VERSION ""

NS_ :

BS_:

BU_: R_BPCU_MCU JiaShiCang L_BPCU_MCU EMPC_ECU

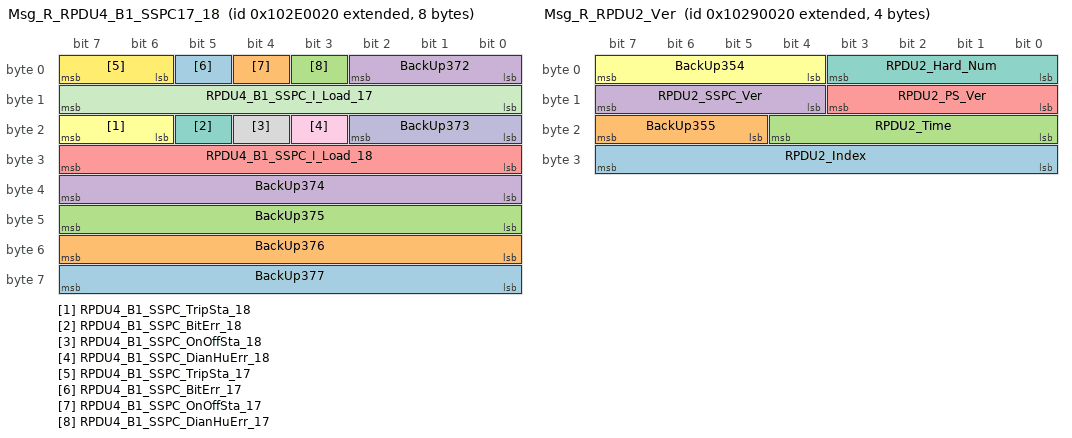
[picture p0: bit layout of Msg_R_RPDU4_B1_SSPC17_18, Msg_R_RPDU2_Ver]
BO_ 2418933792 Msg_R_RPDU4_B1_SSPC17_18: 8 R_BPCU_MCU
 SG_ BackUp377 : 56|8@1+ (1,0) [0|0] ""  JiaShiCang
 SG_ BackUp376 : 48|8@1+ (1,0) [0|0] ""  JiaShiCang
 SG_ BackUp375 : 40|8@1+ (1,0) [0|0] ""  JiaShiCang
 SG_ BackUp374 : 32|8@1+ (1,0) [0|0] ""  JiaShiCang
 SG_ RPDU4_B1_SSPC_I_Load_18 : 24|8@1+ (0.1,0) [0|25.5] "A"  JiaShiCang
 SG_ RPDU4_B1_SSPC_TripSta_18 : 22|2@1+ (1,0) [0|3] ""  JiaShiCang
 SG_ RPDU4_B1_SSPC_BitErr_18 : 21|1@1+ (1,0) [0|1] ""  JiaShiCang
 SG_ RPDU4_B1_SSPC_OnOffSta_18 : 20|1@1+ (1,0) [0|1] ""  JiaShiCang
 SG_ RPDU4_B1_SSPC_DianHuErr_18 : 19|1@1+ (1,0) [0|1] ""  JiaShiCang
 SG_ BackUp373 : 16|3@1+ (1,0) [0|0] ""  JiaShiCang
 SG_ RPDU4_B1_SSPC_I_Load_17 : 8|8@1+ (0.1,0) [0|25.5] "A"  JiaShiCang
 SG_ RPDU4_B1_SSPC_TripSta_17 : 6|2@1+ (1,0) [0|3] ""  JiaShiCang
 SG_ RPDU4_B1_SSPC_BitErr_17 : 5|1@1+ (1,0) [0|1] ""  JiaShiCang
 SG_ RPDU4_B1_SSPC_OnOffSta_17 : 4|1@1+ (1,0) [0|1] ""  JiaShiCang
 SG_ RPDU4_B1_SSPC_DianHuErr_17 : 3|1@1+ (1,0) [0|1] ""  JiaShiCang
 SG_ BackUp372 : 0|3@1+ (1,0) [0|0] ""  JiaShiCang

BO_ 2418868256 Msg_R_RPDU4_B1_SSPC13_16: 8 R_BPCU_MCU
 SG_ RPDU4_B1_SSPC_I_Load_16 : 56|8@1+ (0.1,0) [0|25.5] "A"  JiaShiCang
 SG_ RPDU4_B1_SSPC_TripSta_16 : 54|2@1+ (1,0) [0|3] ""  JiaShiCang
 SG_ RPDU4_B1_SSPC_BitErr_16 : 53|1@1+ (1,0) [0|1] ""  JiaShiCang
 SG_ RPDU4_B1_SSPC_OnOffSta_16 : 52|1@1+ (1,0) [0|1] ""  JiaShiCang
 SG_ RPDU4_B1_SSPC_DianHuErr_16 : 51|1@1+ (1,0) [0|1] ""  JiaShiCang
 SG_ BackUp371 : 48|3@1+ (1,0) [0|0] ""  JiaShiCang
 SG_ RPDU4_B1_SSPC_I_Load_15 : 40|8@1+ (0.1,0) [0|25.5] "A"  JiaShiCang
 SG_ RPDU4_B1_SSPC_TripSta_15 : 38|2@1+ (1,0) [0|3] ""  JiaShiCang
 SG_ RPDU4_B1_SSPC_BitErr_15 : 37|1@1+ (1,0) [0|1] ""  JiaShiCang
 SG_ RPDU4_B1_SSPC_OnOffSta_15 : 36|1@1+ (1,0) [0|1] ""  JiaShiCang
 SG_ RPDU4_B1_SSPC_DianHuErr_15 : 35|1@1+ (1,0) [0|1] ""  JiaShiCang
 SG_ BackUp370 : 32|3@1+ (1,0) [0|0] ""  JiaShiCang
 SG_ RPDU4_B1_SSPC_I_Load_14 : 24|8@1+ (0.1,0) [0|25.5] "A"  JiaShiCang
 SG_ RPDU4_B1_SSPC_TripSta_14 : 22|2@1+ (1,0) [0|3] ""  JiaShiCang
 SG_ RPDU4_B1_SSPC_BitErr_14 : 21|1@1+ (1,0) [0|1] ""  JiaShiCang
 SG_ RPDU4_B1_SSPC_OnOffSta_14 : 20|1@1+ (1,0) [0|1] ""  JiaShiCang
 SG_ RPDU4_B1_SSPC_DianHuErr_14 : 19|1@1+ (1,0) [0|1] ""  JiaShiCang
 SG_ BackUp369 : 16|3@1+ (1,0) [0|0] ""  JiaShiCang
 SG_ RPDU4_B1_SSPC_I_Load_13 : 8|8@1+ (0.1,0) [0|25.5] "A"  JiaShiCang
 SG_ RPDU4_B1_SSPC_TripSta_13 : 6|2@1+ (1,0) [0|3] ""  JiaShiCang
 SG_ RPDU4_B1_SSPC_BitErr_13 : 5|1@1+ (1,0) [0|1] ""  JiaShiCang
 SG_ RPDU4_B1_SSPC_OnOffSta_13 : 4|1@1+ (1,0) [0|1] ""  JiaShiCang
 SG_ RPDU4_B1_SSPC_DianHuErr_13 : 3|1@1+ (1,0) [0|1] ""  JiaShiCang
 SG_ BackUp368 : 0|3@1+ (1,0) [0|0] ""  JiaShiCang

BO_ 2418802720 Msg_R_RPDU4_B1_SSPC09_12: 8 R_BPCU_MCU
 SG_ RPDU4_B1_SSPC_I_Load_12 : 56|8@1+ (0.1,0) [0|25.5] "A"  JiaShiCang
 SG_ RPDU4_B1_SSPC_TripSta_12 : 54|2@1+ (1,0) [0|3] ""  JiaShiCang
 SG_ RPDU4_B1_SSPC_BitErr_12 : 53|1@1+ (1,0) [0|1] ""  JiaShiCang
 SG_ RPDU4_B1_SSPC_OnOffSta_12 : 52|1@1+ (1,0) [0|1] ""  JiaShiCang
 SG_ RPDU4_B1_SSPC_DianHuErr_12 : 51|1@1+ (1,0) [0|1] ""  JiaShiCang
 SG_ BackUp367 : 48|3@1+ (1,0) [0|0] ""  JiaShiCang
 SG_ RPDU4_B1_SSPC_I_Load_11 : 40|8@1+ (0.1,0) [0|25.5] "A"  JiaShiCang
 SG_ RPDU4_B1_SSPC_TripSta_11 : 38|2@1+ (1,0) [0|3] ""  JiaShiCang
 SG_ RPDU4_B1_SSPC_BitErr_11 : 37|1@1+ (1,0) [0|1] ""  JiaShiCang
 SG_ RPDU4_B1_SSPC_OnOffSta_11 : 36|1@1+ (1,0) [0|1] ""  JiaShiCang
 SG_ RPDU4_B1_SSPC_DianHuErr_11 : 35|1@1+ (1,0) [0|1] ""  JiaShiCang
 SG_ BackUp366 : 32|3@1+ (1,0) [0|0] ""  JiaShiCang
 SG_ RPDU4_B1_SSPC_I_Load_10 : 24|8@1+ (0.1,0) [0|25.5] "A"  JiaShiCang
 SG_ RPDU4_B1_SSPC_TripSta_10 : 22|2@1+ (1,0) [0|3] ""  JiaShiCang
 SG_ RPDU4_B1_SSPC_BitErr_10 : 21|1@1+ (1,0) [0|1] ""  JiaShiCang
 SG_ RPDU4_B1_SSPC_OnOffSta_10 : 20|1@1+ (1,0) [0|1] ""  JiaShiCang
 SG_ RPDU4_B1_SSPC_DianHuErr_10 : 19|1@1+ (1,0) [0|1] ""  JiaShiCang
 SG_ BackUp365 : 16|3@1+ (1,0) [0|0] ""  JiaShiCang
 SG_ RPDU4_B1_SSPC_I_Load_09 : 8|8@1+ (0.1,0) [0|25.5] "A"  JiaShiCang
 SG_ RPDU4_B1_SSPC_TripSta_09 : 6|2@1+ (1,0) [0|3] ""  JiaShiCang
 SG_ RPDU4_B1_SSPC_BitErr_09 : 5|1@1+ (1,0) [0|1] ""  JiaShiCang
 SG_ RPDU4_B1_SSPC_OnOffSta_09 : 4|1@1+ (1,0) [0|1] ""  JiaShiCang
 SG_ RPDU4_B1_SSPC_DianHuErr_09 : 3|1@1+ (1,0) [0|1] ""  JiaShiCang
 SG_ BackUp364 : 0|3@1+ (1,0) [0|0] ""  JiaShiCang

BO_ 2418737184 Msg_R_RPDU4_B1_SSPC05_08: 8 R_BPCU_MCU
 SG_ RPDU4_B1_SSPC_I_Load_08 : 56|8@1+ (0.1,0) [0|25.5] "A"  JiaShiCang
 SG_ RPDU4_B1_SSPC_TripSta_08 : 54|2@1+ (1,0) [0|3] ""  JiaShiCang
 SG_ RPDU4_B1_SSPC_BitErr_08 : 53|1@1+ (1,0) [0|1] ""  JiaShiCang
 SG_ RPDU4_B1_SSPC_OnOffSta_08 : 52|1@1+ (1,0) [0|1] ""  JiaShiCang
 SG_ RPDU4_B1_SSPC_DianHuErr_08 : 51|1@1+ (1,0) [0|1] ""  JiaShiCang
 SG_ BackUp363 : 48|3@1+ (1,0) [0|0] ""  JiaShiCang
 SG_ RPDU4_B1_SSPC_I_Load_07 : 40|8@1+ (0.1,0) [0|25.5] "A"  JiaShiCang
 SG_ RPDU4_B1_SSPC_TripSta_07 : 38|2@1+ (1,0) [0|3] ""  JiaShiCang
 SG_ RPDU4_B1_SSPC_BitErr_07 : 37|1@1+ (1,0) [0|1] ""  JiaShiCang
 SG_ RPDU4_B1_SSPC_OnOffSta_07 : 36|1@1+ (1,0) [0|1] ""  JiaShiCang
 SG_ RPDU4_B1_SSPC_DianHuErr_07 : 35|1@1+ (1,0) [0|1] ""  JiaShiCang
 SG_ BackUp362 : 32|3@1+ (1,0) [0|0] ""  JiaShiCang
 SG_ RPDU4_B1_SSPC_I_Load_06 : 24|8@1+ (0.1,0) [0|25.5] "A"  JiaShiCang
 SG_ RPDU4_B1_SSPC_TripSta_06 : 22|2@1+ (1,0) [0|3] ""  JiaShiCang
 SG_ RPDU4_B1_SSPC_BitErr_06 : 21|1@1+ (1,0) [0|1] ""  JiaShiCang
 SG_ RPDU4_B1_SSPC_OnOffSta_06 : 20|1@1+ (1,0) [0|1] ""  JiaShiCang
 SG_ RPDU4_B1_SSPC_DianHuErr_06 : 19|1@1+ (1,0) [0|1] ""  JiaShiCang
 SG_ BackUp361 : 16|3@1+ (1,0) [0|0] ""  JiaShiCang
 SG_ RPDU4_B1_SSPC_I_Load_05 : 8|8@1+ (0.1,0) [0|25.5] "A"  JiaShiCang
 SG_ RPDU4_B1_SSPC_TripSta_05 : 6|2@1+ (1,0) [0|3] ""  JiaShiCang
 SG_ RPDU4_B1_SSPC_BitErr_05 : 5|1@1+ (1,0) [0|1] ""  JiaShiCang
 SG_ RPDU4_B1_SSPC_OnOffSta_05 : 4|1@1+ (1,0) [0|1] ""  JiaShiCang
 SG_ RPDU4_B1_SSPC_DianHuErr_05 : 3|1@1+ (1,0) [0|1] ""  JiaShiCang
 SG_ BackUp360 : 0|3@1+ (1,0) [0|0] ""  JiaShiCang

BO_ 2418671648 Msg_R_RPDU4_B1_SSPC01_04: 8 R_BPCU_MCU
 SG_ RPDU4_B1_SSPC_I_Load_04 : 56|8@1+ (0.1,0) [0|25.5] "A"  JiaShiCang
 SG_ RPDU4_B1_SSPC_TripSta_04 : 54|2@1+ (1,0) [0|3] ""  JiaShiCang
 SG_ RPDU4_B1_SSPC_BitErr_04 : 53|1@1+ (1,0) [0|1] ""  JiaShiCang
 SG_ RPDU4_B1_SSPC_OnOffSta_04 : 52|1@1+ (1,0) [0|1] ""  JiaShiCang
 SG_ RPDU4_B1_SSPC_DianHuErr_04 : 51|1@1+ (1,0) [0|1] ""  JiaShiCang
 SG_ BackUp359 : 48|3@1+ (1,0) [0|0] ""  JiaShiCang
 SG_ RPDU4_B1_SSPC_I_Load_03 : 40|8@1+ (0.1,0) [0|25.5] "A"  JiaShiCang
 SG_ RPDU4_B1_SSPC_TripSta_03 : 38|2@1+ (1,0) [0|3] ""  JiaShiCang
 SG_ RPDU4_B1_SSPC_BitErr_03 : 37|1@1+ (1,0) [0|1] ""  JiaShiCang
 SG_ RPDU4_B1_SSPC_OnOffSta_03 : 36|1@1+ (1,0) [0|1] ""  JiaShiCang
 SG_ RPDU4_B1_SSPC_DianHuErr_03 : 35|1@1+ (1,0) [0|1] ""  JiaShiCang
 SG_ BackUp358 : 32|3@1+ (1,0) [0|0] ""  JiaShiCang
 SG_ RPDU4_B1_SSPC_I_Load_02 : 24|8@1+ (0.1,0) [0|25.5] "A"  JiaShiCang
 SG_ RPDU4_B1_SSPC_TripSta_02 : 22|2@1+ (1,0) [0|3] ""  JiaShiCang
 SG_ RPDU4_B1_SSPC_BitErr_02 : 21|1@1+ (1,0) [0|1] ""  JiaShiCang
 SG_ RPDU4_B1_SSPC_OnOffSta_02 : 20|1@1+ (1,0) [0|1] ""  JiaShiCang
 SG_ RPDU4_B1_SSPC_DianHuErr_02 : 19|1@1+ (1,0) [0|1] ""  JiaShiCang
 SG_ BackUp357 : 16|3@1+ (1,0) [0|0] ""  JiaShiCang
 SG_ RPDU4_B1_SSPC_I_Load_01 : 8|8@1+ (0.1,0) [0|25.5] "A"  JiaShiCang
 SG_ RPDU4_B1_SSPC_TripSta_01 : 6|2@1+ (1,0) [0|3] ""  JiaShiCang
 SG_ RPDU4_B1_SSPC_BitErr_01 : 5|1@1+ (1,0) [0|1] ""  JiaShiCang
 SG_ RPDU4_B1_SSPC_OnOffSta_01 : 4|1@1+ (1,0) [0|1] ""  JiaShiCang
 SG_ RPDU4_B1_SSPC_DianHuErr_01 : 3|1@1+ (1,0) [0|1] ""  JiaShiCang
 SG_ BackUp356 : 0|3@1+ (1,0) [0|0] ""  JiaShiCang

BO_ 2418606112 Msg_R_RPDU2_Ver: 4 R_BPCU_MCU
 SG_ RPDU2_Index : 24|8@1+ (1,0) [0|255] ""  JiaShiCang
 SG_ BackUp355 : 21|3@1+ (1,0) [0|0] ""  JiaShiCang
 SG_ RPDU2_Time : 16|5@1+ (1,0) [0|31] ""  JiaShiCang
 SG_ RPDU2_SSPC_Ver : 12|4@1+ (1,0) [0|15] ""  JiaShiCang
 SG_ RPDU2_PS_Ver : 8|4@1+ (1,0) [0|15] ""  JiaShiCang
 SG_ BackUp354 : 4|4@1+ (1,0) [0|0] ""  JiaShiCang
 SG_ RPDU2_Hard_Num : 0|4@1+ (1,0) [0|15] ""  JiaShiCang

BO_ 2418540576 Msg_R_RPDU2_B6_SSPC05_07: 8 R_BPCU_MCU
 SG_ BackUp353 : 56|8@1+ (1,0) [0|0] ""  JiaShiCang
 SG_ BackUp352 : 48|8@1+ (1,0) [0|0] ""  JiaShiCang
 SG_ RPDU2_B6_SSPC_I_Load_07 : 40|8@1+ (0.1,0) [0|25.5] "A"  JiaShiCang
 SG_ RPDU2_B6_SSPC_TripSta_07 : 38|2@1+ (1,0) [0|3] ""  JiaShiCang
 SG_ RPDU2_B6_SSPC_BitErr_07 : 37|1@1+ (1,0) [0|1] ""  JiaShiCang
 SG_ RPDU2_B6_SSPC_OnOffSta_07 : 36|1@1+ (1,0) [0|1] ""  JiaShiCang
 SG_ RPDU2_B6_SSPC_DianHuErr_07 : 35|1@1+ (1,0) [0|1] ""  JiaShiCang
 SG_ BackUp351 : 32|3@1+ (1,0) [0|0] ""  JiaShiCang
 SG_ RPDU2_B6_SSPC_I_Load_06 : 24|8@1+ (0.1,0) [0|25.5] "A"  JiaShiCang
 SG_ RPDU2_B6_SSPC_TripSta_06 : 22|2@1+ (1,0) [0|3] ""  JiaShiCang
 SG_ RPDU2_B6_SSPC_BitErr_06 : 21|1@1+ (1,0) [0|1] ""  JiaShiCang
 SG_ RPDU2_B6_SSPC_OnOffSta_06 : 20|1@1+ (1,0) [0|1] ""  JiaShiCang
 SG_ RPDU2_B6_SSPC_DianHuErr_06 : 19|1@1+ (1,0) [0|1] ""  JiaShiCang
 SG_ BackUp350 : 16|3@1+ (1,0) [0|0] ""  JiaShiCang
 SG_ RPDU2_B6_SSPC_I_Load_05 : 8|8@1+ (0.1,0) [0|25.5] "A"  JiaShiCang
 SG_ RPDU2_B6_SSPC_TripSta_05 : 6|2@1+ (1,0) [0|3] ""  JiaShiCang
 SG_ RPDU2_B6_SSPC_BitErr_05 : 5|1@1+ (1,0) [0|1] ""  JiaShiCang
 SG_ RPDU2_B6_SSPC_OnOffSta_05 : 4|1@1+ (1,0) [0|1] ""  JiaShiCang
 SG_ RPDU2_B6_SSPC_DianHuErr_05 : 3|1@1+ (1,0) [0|1] ""  JiaShiCang
 SG_ BackUp349 : 0|3@1+ (1,0) [0|0] ""  JiaShiCang

BO_ 2418475040 Msg_R_RPDU2_B6_SSPC01_04: 8 R_BPCU_MCU
 SG_ RPDU2_B6_SSPC_I_Load_04 : 56|8@1+ (0.1,0) [0|25.5] "A"  JiaShiCang
 SG_ RPDU2_B6_SSPC_TripSta_04 : 54|2@1+ (1,0) [0|3] ""  JiaShiCang
 SG_ RPDU2_B6_SSPC_BitErr_04 : 53|1@1+ (1,0) [0|1] ""  JiaShiCang
 SG_ RPDU2_B6_SSPC_OnOffSta_04 : 52|1@1+ (1,0) [0|1] ""  JiaShiCang
 SG_ RPDU2_B6_SSPC_DianHuErr_04 : 51|1@1+ (1,0) [0|1] ""  JiaShiCang
 SG_ BackUp348 : 48|3@1+ (1,0) [0|0] ""  JiaShiCang
 SG_ RPDU2_B6_SSPC_I_Load_03 : 40|8@1+ (0.1,0) [0|25.5] "A"  JiaShiCang
 SG_ RPDU2_B6_SSPC_TripSta_03 : 38|2@1+ (1,0) [0|3] ""  JiaShiCang
 SG_ RPDU2_B6_SSPC_BitErr_03 : 37|1@1+ (1,0) [0|1] ""  JiaShiCang
 SG_ RPDU2_B6_SSPC_OnOffSta_03 : 36|1@1+ (1,0) [0|1] ""  JiaShiCang
 SG_ RPDU2_B6_SSPC_DianHuErr_03 : 35|1@1+ (1,0) [0|1] ""  JiaShiCang
 SG_ BackUp347 : 32|3@1+ (1,0) [0|0] ""  JiaShiCang
 SG_ RPDU2_B6_SSPC_I_Load_02 : 24|8@1+ (0.1,0) [0|25.5] "A"  JiaShiCang
 SG_ RPDU2_B6_SSPC_TripSta_02 : 22|2@1+ (1,0) [0|3] ""  JiaShiCang
 SG_ RPDU2_B6_SSPC_BitErr_02 : 21|1@1+ (1,0) [0|1] ""  JiaShiCang
 SG_ RPDU2_B6_SSPC_OnOffSta_02 : 20|1@1+ (1,0) [0|1] ""  JiaShiCang
 SG_ RPDU2_B6_SSPC_DianHuErr_02 : 19|1@1+ (1,0) [0|1] ""  JiaShiCang
 SG_ BackUp346 : 16|3@1+ (1,0) [0|0] ""  JiaShiCang
 SG_ RPDU2_B6_SSPC_I_Load_01 : 8|8@1+ (0.1,0) [0|25.5] "A"  JiaShiCang
 SG_ RPDU2_B6_SSPC_TripSta_01 : 6|2@1+ (1,0) [0|3] ""  JiaShiCang
 SG_ RPDU2_B6_SSPC_BitErr_01 : 5|1@1+ (1,0) [0|1] ""  JiaShiCang
 SG_ RPDU2_B6_SSPC_OnOffSta_01 : 4|1@1+ (1,0) [0|1] ""  JiaShiCang
 SG_ RPDU2_B6_SSPC_DianHuErr_01 : 3|1@1+ (1,0) [0|1] ""  JiaShiCang
 SG_ BackUp345 : 0|3@1+ (1,0) [0|0] ""  JiaShiCang

BO_ 2418409504 Msg_R_RPDU2_B5_SSPC05_07: 8 R_BPCU_MCU
 SG_ BackUp344 : 56|8@1+ (1,0) [0|0] ""  JiaShiCang
 SG_ BackUp343 : 48|8@1+ (1,0) [0|0] ""  JiaShiCang
 SG_ RPDU2_B5_SSPC_I_Load_07 : 40|8@1+ (0.1,0) [0|25.5] "A"  JiaShiCang
 SG_ RPDU2_B5_SSPC_TripSta_07 : 38|2@1+ (1,0) [0|3] ""  JiaShiCang
 SG_ RPDU2_B5_SSPC_BitErr_07 : 37|1@1+ (1,0) [0|1] ""  JiaShiCang
 SG_ RPDU2_B5_SSPC_OnOffSta_07 : 36|1@1+ (1,0) [0|1] ""  JiaShiCang
 SG_ RPDU2_B5_SSPC_DianHuErr_07 : 35|1@1+ (1,0) [0|1] ""  JiaShiCang
 SG_ BackUp342 : 32|3@1+ (1,0) [0|0] ""  JiaShiCang
 SG_ RPDU2_B5_SSPC_I_Load_06 : 24|8@1+ (0.1,0) [0|25.5] "A"  JiaShiCang
 SG_ RPDU2_B5_SSPC_TripSta_06 : 22|2@1+ (1,0) [0|3] ""  JiaShiCang
 SG_ RPDU2_B5_SSPC_BitErr_06 : 21|1@1+ (1,0) [0|1] ""  JiaShiCang
 SG_ RPDU2_B5_SSPC_OnOffSta_06 : 20|1@1+ (1,0) [0|1] ""  JiaShiCang
 SG_ RPDU2_B5_SSPC_DianHuErr_06 : 19|1@1+ (1,0) [0|1] ""  JiaShiCang
 SG_ BackUp341 : 16|3@1+ (1,0) [0|0] ""  JiaShiCang
 SG_ RPDU2_B5_SSPC_I_Load_05 : 8|8@1+ (0.1,0) [0|25.5] "A"  JiaShiCang
 SG_ RPDU2_B5_SSPC_TripSta_05 : 6|2@1+ (1,0) [0|3] ""  JiaShiCang
 SG_ RPDU2_B5_SSPC_BitErr_05 : 5|1@1+ (1,0) [0|1] ""  JiaShiCang
 SG_ RPDU2_B5_SSPC_OnOffSta_05 : 4|1@1+ (1,0) [0|1] ""  JiaShiCang
 SG_ RPDU2_B5_SSPC_DianHuErr_05 : 3|1@1+ (1,0) [0|1] ""  JiaShiCang
 SG_ BackUp340 : 0|3@1+ (1,0) [0|0] ""  JiaShiCang

BO_ 2418343968 Msg_R_RPDU2_B5_SSPC01_04: 8 R_BPCU_MCU
 SG_ RPDU2_B5_SSPC_I_Load_04 : 56|8@1+ (0.1,0) [0|25.5] "A"  JiaShiCang
 SG_ RPDU2_B5_SSPC_TripSta_04 : 54|2@1+ (1,0) [0|3] ""  JiaShiCang
 SG_ RPDU2_B5_SSPC_BitErr_04 : 53|1@1+ (1,0) [0|1] ""  JiaShiCang
 SG_ RPDU2_B5_SSPC_OnOffSta_04 : 52|1@1+ (1,0) [0|1] ""  JiaShiCang
 SG_ RPDU2_B5_SSPC_DianHuErr_04 : 51|1@1+ (1,0) [0|1] ""  JiaShiCang
 SG_ BackUp339 : 48|3@1+ (1,0) [0|0] ""  JiaShiCang
 SG_ RPDU2_B5_SSPC_I_Load_03 : 40|8@1+ (0.1,0) [0|25.5] "A"  JiaShiCang
 SG_ RPDU2_B5_SSPC_TripSta_03 : 38|2@1+ (1,0) [0|3] ""  JiaShiCang
 SG_ RPDU2_B5_SSPC_BitErr_03 : 37|1@1+ (1,0) [0|1] ""  JiaShiCang
 SG_ RPDU2_B5_SSPC_OnOffSta_03 : 36|1@1+ (1,0) [0|1] ""  JiaShiCang
 SG_ RPDU2_B5_SSPC_DianHuErr_03 : 35|1@1+ (1,0) [0|1] ""  JiaShiCang
 SG_ BackUp338 : 32|3@1+ (1,0) [0|0] ""  JiaShiCang
 SG_ RPDU2_B5_SSPC_I_Load_02 : 24|8@1+ (0.1,0) [0|25.5] "A"  JiaShiCang
 SG_ RPDU2_B5_SSPC_TripSta_02 : 22|2@1+ (1,0) [0|3] ""  JiaShiCang
 SG_ RPDU2_B5_SSPC_BitErr_02 : 21|1@1+ (1,0) [0|1] ""  JiaShiCang
 SG_ RPDU2_B5_SSPC_OnOffSta_02 : 20|1@1+ (1,0) [0|1] ""  JiaShiCang
 SG_ RPDU2_B5_SSPC_DianHuErr_02 : 19|1@1+ (1,0) [0|1] ""  JiaShiCang
 SG_ BackUp337 : 16|3@1+ (1,0) [0|0] ""  JiaShiCang
 SG_ RPDU2_B5_SSPC_I_Load_01 : 8|8@1+ (0.1,0) [0|25.5] "A"  JiaShiCang
 SG_ RPDU2_B5_SSPC_TripSta_01 : 6|2@1+ (1,0) [0|3] ""  JiaShiCang
 SG_ RPDU2_B5_SSPC_BitErr_01 : 5|1@1+ (1,0) [0|1] ""  JiaShiCang
 SG_ RPDU2_B5_SSPC_OnOffSta_01 : 4|1@1+ (1,0) [0|1] ""  JiaShiCang
 SG_ RPDU2_B5_SSPC_DianHuErr_01 : 3|1@1+ (1,0) [0|1] ""  JiaShiCang
 SG_ BackUp336 : 0|3@1+ (1,0) [0|0] ""  JiaShiCang

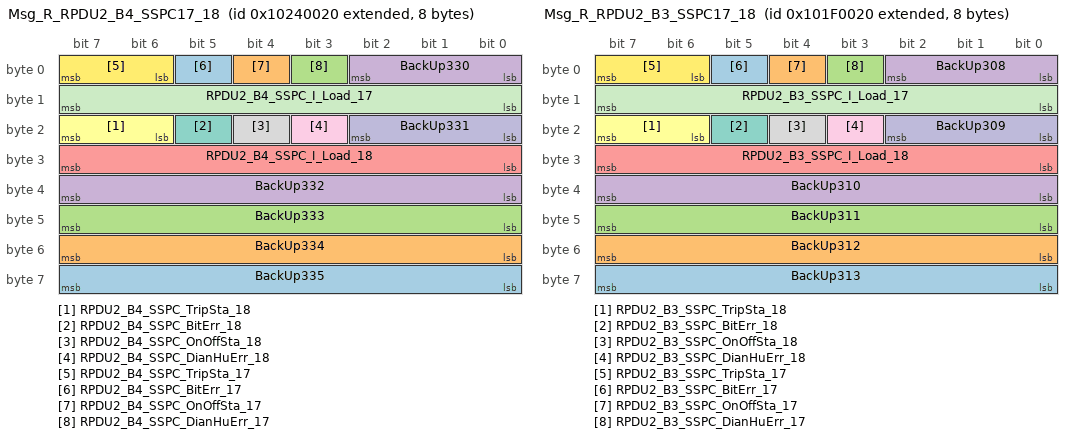
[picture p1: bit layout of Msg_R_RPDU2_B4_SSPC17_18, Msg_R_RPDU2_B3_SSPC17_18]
BO_ 2418278432 Msg_R_RPDU2_B4_SSPC17_18: 8 R_BPCU_MCU
 SG_ BackUp335 : 56|8@1+ (1,0) [0|0] ""  JiaShiCang
 SG_ BackUp334 : 48|8@1+ (1,0) [0|0] ""  JiaShiCang
 SG_ BackUp333 : 40|8@1+ (1,0) [0|0] ""  JiaShiCang
 SG_ BackUp332 : 32|8@1+ (1,0) [0|0] ""  JiaShiCang
 SG_ RPDU2_B4_SSPC_I_Load_18 : 24|8@1+ (0.1,0) [0|25.5] "A"  JiaShiCang
 SG_ RPDU2_B4_SSPC_TripSta_18 : 22|2@1+ (1,0) [0|3] ""  JiaShiCang
 SG_ RPDU2_B4_SSPC_BitErr_18 : 21|1@1+ (1,0) [0|1] ""  JiaShiCang
 SG_ RPDU2_B4_SSPC_OnOffSta_18 : 20|1@1+ (1,0) [0|1] ""  JiaShiCang
 SG_ RPDU2_B4_SSPC_DianHuErr_18 : 19|1@1+ (1,0) [0|1] ""  JiaShiCang
 SG_ BackUp331 : 16|3@1+ (1,0) [0|0] ""  JiaShiCang
 SG_ RPDU2_B4_SSPC_I_Load_17 : 8|8@1+ (0.1,0) [0|25.5] "A"  JiaShiCang
 SG_ RPDU2_B4_SSPC_TripSta_17 : 6|2@1+ (1,0) [0|3] ""  JiaShiCang
 SG_ RPDU2_B4_SSPC_BitErr_17 : 5|1@1+ (1,0) [0|1] ""  JiaShiCang
 SG_ RPDU2_B4_SSPC_OnOffSta_17 : 4|1@1+ (1,0) [0|1] ""  JiaShiCang
 SG_ RPDU2_B4_SSPC_DianHuErr_17 : 3|1@1+ (1,0) [0|1] ""  JiaShiCang
 SG_ BackUp330 : 0|3@1+ (1,0) [0|0] ""  JiaShiCang

BO_ 2418212896 Msg_R_RPDU2_B4_SSPC13_16: 8 R_BPCU_MCU
 SG_ RPDU2_B4_SSPC_I_Load_16 : 56|8@1+ (0.1,0) [0|25.5] "A"  JiaShiCang
 SG_ RPDU2_B4_SSPC_TripSta_16 : 54|2@1+ (1,0) [0|3] ""  JiaShiCang
 SG_ RPDU2_B4_SSPC_BitErr_16 : 53|1@1+ (1,0) [0|1] ""  JiaShiCang
 SG_ RPDU2_B4_SSPC_OnOffSta_16 : 52|1@1+ (1,0) [0|1] ""  JiaShiCang
 SG_ RPDU2_B4_SSPC_DianHuErr_16 : 51|1@1+ (1,0) [0|1] ""  JiaShiCang
 SG_ BackUp329 : 48|3@1+ (1,0) [0|0] ""  JiaShiCang
 SG_ RPDU2_B4_SSPC_I_Load_15 : 40|8@1+ (0.1,0) [0|25.5] "A"  JiaShiCang
 SG_ RPDU2_B4_SSPC_TripSta_15 : 38|2@1+ (1,0) [0|3] ""  JiaShiCang
 SG_ RPDU2_B4_SSPC_BitErr_15 : 37|1@1+ (1,0) [0|1] ""  JiaShiCang
 SG_ RPDU2_B4_SSPC_OnOffSta_15 : 36|1@1+ (1,0) [0|1] ""  JiaShiCang
 SG_ RPDU2_B4_SSPC_DianHuErr_15 : 35|1@1+ (1,0) [0|1] ""  JiaShiCang
 SG_ BackUp328 : 32|3@1+ (1,0) [0|0] ""  JiaShiCang
 SG_ RPDU2_B4_SSPC_I_Load_14 : 24|8@1+ (0.1,0) [0|25.5] "A"  JiaShiCang
 SG_ RPDU2_B4_SSPC_TripSta_14 : 22|2@1+ (1,0) [0|3] ""  JiaShiCang
 SG_ RPDU2_B4_SSPC_BitErr_14 : 21|1@1+ (1,0) [0|1] ""  JiaShiCang
 SG_ RPDU2_B4_SSPC_OnOffSta_14 : 20|1@1+ (1,0) [0|1] ""  JiaShiCang
 SG_ RPDU2_B4_SSPC_DianHuErr_14 : 19|1@1+ (1,0) [0|1] ""  JiaShiCang
 SG_ BackUp327 : 16|3@1+ (1,0) [0|0] ""  JiaShiCang
 SG_ RPDU2_B4_SSPC_I_Load_13 : 8|8@1+ (0.1,0) [0|25.5] "A"  JiaShiCang
 SG_ RPDU2_B4_SSPC_TripSta_13 : 6|2@1+ (1,0) [0|3] ""  JiaShiCang
 SG_ RPDU2_B4_SSPC_BitErr_13 : 5|1@1+ (1,0) [0|1] ""  JiaShiCang
 SG_ RPDU2_B4_SSPC_OnOffSta_13 : 4|1@1+ (1,0) [0|1] ""  JiaShiCang
 SG_ RPDU2_B4_SSPC_DianHuErr_13 : 3|1@1+ (1,0) [0|1] ""  JiaShiCang
 SG_ BackUp326 : 0|3@1+ (1,0) [0|0] ""  JiaShiCang

BO_ 2418147360 Msg_R_RPDU2_B4_SSPC09_12: 8 R_BPCU_MCU
 SG_ RPDU2_B4_SSPC_I_Load_12 : 56|8@1+ (0.1,0) [0|25.5] "A"  JiaShiCang
 SG_ RPDU2_B4_SSPC_TripSta_12 : 54|2@1+ (1,0) [0|3] ""  JiaShiCang
 SG_ RPDU2_B4_SSPC_BitErr_12 : 53|1@1+ (1,0) [0|1] ""  JiaShiCang
 SG_ RPDU2_B4_SSPC_OnOffSta_12 : 52|1@1+ (1,0) [0|1] ""  JiaShiCang
 SG_ RPDU2_B4_SSPC_DianHuErr_12 : 51|1@1+ (1,0) [0|1] ""  JiaShiCang
 SG_ BackUp325 : 48|3@1+ (1,0) [0|0] ""  JiaShiCang
 SG_ RPDU2_B4_SSPC_I_Load_11 : 40|8@1+ (0.1,0) [0|25.5] "A"  JiaShiCang
 SG_ RPDU2_B4_SSPC_TripSta_11 : 38|2@1+ (1,0) [0|3] ""  JiaShiCang
 SG_ RPDU2_B4_SSPC_BitErr_11 : 37|1@1+ (1,0) [0|1] ""  JiaShiCang
 SG_ RPDU2_B4_SSPC_OnOffSta_11 : 36|1@1+ (1,0) [0|1] ""  JiaShiCang
 SG_ RPDU2_B4_SSPC_DianHuErr_11 : 35|1@1+ (1,0) [0|1] ""  JiaShiCang
 SG_ BackUp324 : 32|3@1+ (1,0) [0|0] ""  JiaShiCang
 SG_ RPDU2_B4_SSPC_I_Load_10 : 24|8@1+ (0.1,0) [0|25.5] "A"  JiaShiCang
 SG_ RPDU2_B4_SSPC_TripSta_10 : 22|2@1+ (1,0) [0|3] ""  JiaShiCang
 SG_ RPDU2_B4_SSPC_BitErr_10 : 21|1@1+ (1,0) [0|1] ""  JiaShiCang
 SG_ RPDU2_B4_SSPC_OnOffSta_10 : 20|1@1+ (1,0) [0|1] ""  JiaShiCang
 SG_ RPDU2_B4_SSPC_DianHuErr_10 : 19|1@1+ (1,0) [0|1] ""  JiaShiCang
 SG_ BackUp323 : 16|3@1+ (1,0) [0|0] ""  JiaShiCang
 SG_ RPDU2_B4_SSPC_I_Load_09 : 8|8@1+ (0.1,0) [0|25.5] "A"  JiaShiCang
 SG_ RPDU2_B4_SSPC_TripSta_09 : 6|2@1+ (1,0) [0|3] ""  JiaShiCang
 SG_ RPDU2_B4_SSPC_BitErr_09 : 5|1@1+ (1,0) [0|1] ""  JiaShiCang
 SG_ RPDU2_B4_SSPC_OnOffSta_09 : 4|1@1+ (1,0) [0|1] ""  JiaShiCang
 SG_ RPDU2_B4_SSPC_DianHuErr_09 : 3|1@1+ (1,0) [0|1] ""  JiaShiCang
 SG_ BackUp322 : 0|3@1+ (1,0) [0|0] ""  JiaShiCang

BO_ 2418081824 Msg_R_RPDU2_B4_SSPC05_08: 8 R_BPCU_MCU
 SG_ RPDU2_B4_SSPC_I_Load_08 : 56|8@1+ (0.1,0) [0|25.5] "A"  JiaShiCang
 SG_ RPDU2_B4_SSPC_TripSta_08 : 54|2@1+ (1,0) [0|3] ""  JiaShiCang
 SG_ RPDU2_B4_SSPC_BitErr_08 : 53|1@1+ (1,0) [0|1] ""  JiaShiCang
 SG_ RPDU2_B4_SSPC_OnOffSta_08 : 52|1@1+ (1,0) [0|1] ""  JiaShiCang
 SG_ RPDU2_B4_SSPC_DianHuErr_08 : 51|1@1+ (1,0) [0|1] ""  JiaShiCang
 SG_ BackUp321 : 48|3@1+ (1,0) [0|0] ""  JiaShiCang
 SG_ RPDU2_B4_SSPC_I_Load_07 : 40|8@1+ (0.1,0) [0|25.5] "A"  JiaShiCang
 SG_ RPDU2_B4_SSPC_TripSta_07 : 38|2@1+ (1,0) [0|3] ""  JiaShiCang
 SG_ RPDU2_B4_SSPC_BitErr_07 : 37|1@1+ (1,0) [0|1] ""  JiaShiCang
 SG_ RPDU2_B4_SSPC_OnOffSta_07 : 36|1@1+ (1,0) [0|1] ""  JiaShiCang
 SG_ RPDU2_B4_SSPC_DianHuErr_07 : 35|1@1+ (1,0) [0|1] ""  JiaShiCang
 SG_ BackUp320 : 32|3@1+ (1,0) [0|0] ""  JiaShiCang
 SG_ RPDU2_B4_SSPC_I_Load_06 : 24|8@1+ (0.1,0) [0|25.5] "A"  JiaShiCang
 SG_ RPDU2_B4_SSPC_TripSta_06 : 22|2@1+ (1,0) [0|3] ""  JiaShiCang
 SG_ RPDU2_B4_SSPC_BitErr_06 : 21|1@1+ (1,0) [0|1] ""  JiaShiCang
 SG_ RPDU2_B4_SSPC_OnOffSta_06 : 20|1@1+ (1,0) [0|1] ""  JiaShiCang
 SG_ RPDU2_B4_SSPC_DianHuErr_06 : 19|1@1+ (1,0) [0|1] ""  JiaShiCang
 SG_ BackUp319 : 16|3@1+ (1,0) [0|0] ""  JiaShiCang
 SG_ RPDU2_B4_SSPC_I_Load_05 : 8|8@1+ (0.1,0) [0|25.5] "A"  JiaShiCang
 SG_ RPDU2_B4_SSPC_TripSta_05 : 6|2@1+ (1,0) [0|3] ""  JiaShiCang
 SG_ RPDU2_B4_SSPC_BitErr_05 : 5|1@1+ (1,0) [0|1] ""  JiaShiCang
 SG_ RPDU2_B4_SSPC_OnOffSta_05 : 4|1@1+ (1,0) [0|1] ""  JiaShiCang
 SG_ RPDU2_B4_SSPC_DianHuErr_05 : 3|1@1+ (1,0) [0|1] ""  JiaShiCang
 SG_ BackUp318 : 0|3@1+ (1,0) [0|0] ""  JiaShiCang

BO_ 2418016288 Msg_R_RPDU2_B4_SSPC01_04: 8 R_BPCU_MCU
 SG_ RPDU2_B4_SSPC_I_Load_04 : 56|8@1+ (0.1,0) [0|25.5] "A"  JiaShiCang
 SG_ RPDU2_B4_SSPC_TripSta_04 : 54|2@1+ (1,0) [0|3] ""  JiaShiCang
 SG_ RPDU2_B4_SSPC_BitErr_04 : 53|1@1+ (1,0) [0|1] ""  JiaShiCang
 SG_ RPDU2_B4_SSPC_OnOffSta_04 : 52|1@1+ (1,0) [0|1] ""  JiaShiCang
 SG_ RPDU2_B4_SSPC_DianHuErr_04 : 51|1@1+ (1,0) [0|1] ""  JiaShiCang
 SG_ BackUp317 : 48|3@1+ (1,0) [0|0] ""  JiaShiCang
 SG_ RPDU2_B4_SSPC_I_Load_03 : 40|8@1+ (0.1,0) [0|25.5] "A"  JiaShiCang
 SG_ RPDU2_B4_SSPC_TripSta_03 : 38|2@1+ (1,0) [0|3] ""  JiaShiCang
 SG_ RPDU2_B4_SSPC_BitErr_03 : 37|1@1+ (1,0) [0|1] ""  JiaShiCang
 SG_ RPDU2_B4_SSPC_OnOffSta_03 : 36|1@1+ (1,0) [0|1] ""  JiaShiCang
 SG_ RPDU2_B4_SSPC_DianHuErr_03 : 35|1@1+ (1,0) [0|1] ""  JiaShiCang
 SG_ BackUp316 : 32|3@1+ (1,0) [0|0] ""  JiaShiCang
 SG_ RPDU2_B4_SSPC_I_Load_02 : 24|8@1+ (0.1,0) [0|25.5] "A"  JiaShiCang
 SG_ RPDU2_B4_SSPC_TripSta_02 : 22|2@1+ (1,0) [0|3] ""  JiaShiCang
 SG_ RPDU2_B4_SSPC_BitErr_02 : 21|1@1+ (1,0) [0|1] ""  JiaShiCang
 SG_ RPDU2_B4_SSPC_OnOffSta_02 : 20|1@1+ (1,0) [0|1] ""  JiaShiCang
 SG_ RPDU2_B4_SSPC_DianHuErr_02 : 19|1@1+ (1,0) [0|1] ""  JiaShiCang
 SG_ BackUp315 : 16|3@1+ (1,0) [0|0] ""  JiaShiCang
 SG_ RPDU2_B4_SSPC_I_Load_01 : 8|8@1+ (0.1,0) [0|25.5] "A"  JiaShiCang
 SG_ RPDU2_B4_SSPC_TripSta_01 : 6|2@1+ (1,0) [0|3] ""  JiaShiCang
 SG_ RPDU2_B4_SSPC_BitErr_01 : 5|1@1+ (1,0) [0|1] ""  JiaShiCang
 SG_ RPDU2_B4_SSPC_OnOffSta_01 : 4|1@1+ (1,0) [0|1] ""  JiaShiCang
 SG_ RPDU2_B4_SSPC_DianHuErr_01 : 3|1@1+ (1,0) [0|1] ""  JiaShiCang
 SG_ BackUp314 : 0|3@1+ (1,0) [0|0] ""  JiaShiCang

BO_ 2417950752 Msg_R_RPDU2_B3_SSPC17_18: 8 R_BPCU_MCU
 SG_ BackUp313 : 56|8@1+ (1,0) [0|0] ""  JiaShiCang
 SG_ BackUp312 : 48|8@1+ (1,0) [0|0] ""  JiaShiCang
 SG_ BackUp311 : 40|8@1+ (1,0) [0|0] ""  JiaShiCang
 SG_ BackUp310 : 32|8@1+ (1,0) [0|0] ""  JiaShiCang
 SG_ RPDU2_B3_SSPC_I_Load_18 : 24|8@1+ (0.1,0) [0|25.5] "A"  JiaShiCang
 SG_ RPDU2_B3_SSPC_TripSta_18 : 22|2@1+ (1,0) [0|3] ""  JiaShiCang
 SG_ RPDU2_B3_SSPC_BitErr_18 : 21|1@1+ (1,0) [0|1] ""  JiaShiCang
 SG_ RPDU2_B3_SSPC_OnOffSta_18 : 20|1@1+ (1,0) [0|1] ""  JiaShiCang
 SG_ RPDU2_B3_SSPC_DianHuErr_18 : 19|1@1+ (1,0) [0|1] ""  JiaShiCang
 SG_ BackUp309 : 16|3@1+ (1,0) [0|0] ""  JiaShiCang
 SG_ RPDU2_B3_SSPC_I_Load_17 : 8|8@1+ (0.1,0) [0|25.5] "A"  JiaShiCang
 SG_ RPDU2_B3_SSPC_TripSta_17 : 6|2@1+ (1,0) [0|3] ""  JiaShiCang
 SG_ RPDU2_B3_SSPC_BitErr_17 : 5|1@1+ (1,0) [0|1] ""  JiaShiCang
 SG_ RPDU2_B3_SSPC_OnOffSta_17 : 4|1@1+ (1,0) [0|1] ""  JiaShiCang
 SG_ RPDU2_B3_SSPC_DianHuErr_17 : 3|1@1+ (1,0) [0|1] ""  JiaShiCang
 SG_ BackUp308 : 0|3@1+ (1,0) [0|0] ""  JiaShiCang

BO_ 2417885216 Msg_R_RPDU2_B3_SSPC13_16: 8 R_BPCU_MCU
 SG_ RPDU2_B3_SSPC_I_Load_16 : 56|8@1+ (0.1,0) [0|25.5] "A"  JiaShiCang
 SG_ RPDU2_B3_SSPC_TripSta_16 : 54|2@1+ (1,0) [0|3] ""  JiaShiCang
 SG_ RPDU2_B3_SSPC_BitErr_16 : 53|1@1+ (1,0) [0|1] ""  JiaShiCang
 SG_ RPDU2_B3_SSPC_OnOffSta_16 : 52|1@1+ (1,0) [0|1] ""  JiaShiCang
 SG_ RPDU2_B3_SSPC_DianHuErr_16 : 51|1@1+ (1,0) [0|1] ""  JiaShiCang
 SG_ BackUp307 : 48|3@1+ (1,0) [0|0] ""  JiaShiCang
 SG_ RPDU2_B3_SSPC_I_Load_15 : 40|8@1+ (0.1,0) [0|25.5] "A"  JiaShiCang
 SG_ RPDU2_B3_SSPC_TripSta_15 : 38|2@1+ (1,0) [0|3] ""  JiaShiCang
 SG_ RPDU2_B3_SSPC_BitErr_15 : 37|1@1+ (1,0) [0|1] ""  JiaShiCang
 SG_ RPDU2_B3_SSPC_OnOffSta_15 : 36|1@1+ (1,0) [0|1] ""  JiaShiCang
 SG_ RPDU2_B3_SSPC_DianHuErr_15 : 35|1@1+ (1,0) [0|1] ""  JiaShiCang
 SG_ BackUp306 : 32|3@1+ (1,0) [0|0] ""  JiaShiCang
 SG_ RPDU2_B3_SSPC_I_Load_14 : 24|8@1+ (0.1,0) [0|25.5] "A"  JiaShiCang
 SG_ RPDU2_B3_SSPC_TripSta_14 : 22|2@1+ (1,0) [0|3] ""  JiaShiCang
 SG_ RPDU2_B3_SSPC_BitErr_14 : 21|1@1+ (1,0) [0|1] ""  JiaShiCang
 SG_ RPDU2_B3_SSPC_OnOffSta_14 : 20|1@1+ (1,0) [0|1] ""  JiaShiCang
 SG_ RPDU2_B3_SSPC_DianHuErr_14 : 19|1@1+ (1,0) [0|1] ""  JiaShiCang
 SG_ BackUp305 : 16|3@1+ (1,0) [0|0] ""  JiaShiCang
 SG_ RPDU2_B3_SSPC_I_Load_13 : 8|8@1+ (0.1,0) [0|25.5] "A"  JiaShiCang
 SG_ RPDU2_B3_SSPC_TripSta_13 : 6|2@1+ (1,0) [0|3] ""  JiaShiCang
 SG_ RPDU2_B3_SSPC_BitErr_13 : 5|1@1+ (1,0) [0|1] ""  JiaShiCang
 SG_ RPDU2_B3_SSPC_OnOffSta_13 : 4|1@1+ (1,0) [0|1] ""  JiaShiCang
 SG_ RPDU2_B3_SSPC_DianHuErr_13 : 3|1@1+ (1,0) [0|1] ""  JiaShiCang
 SG_ BackUp304 : 0|3@1+ (1,0) [0|0] ""  JiaShiCang

BO_ 2417819680 Msg_R_RPDU2_B3_SSPC09_12: 8 R_BPCU_MCU
 SG_ RPDU2_B3_SSPC_I_Load_12 : 56|8@1+ (0.1,0) [0|25.5] "A"  JiaShiCang
 SG_ RPDU2_B3_SSPC_TripSta_12 : 54|2@1+ (1,0) [0|3] ""  JiaShiCang
 SG_ RPDU2_B3_SSPC_BitErr_12 : 53|1@1+ (1,0) [0|1] ""  JiaShiCang
 SG_ RPDU2_B3_SSPC_OnOffSta_12 : 52|1@1+ (1,0) [0|1] ""  JiaShiCang
 SG_ RPDU2_B3_SSPC_DianHuErr_12 : 51|1@1+ (1,0) [0|1] ""  JiaShiCang
 SG_ BackUp303 : 48|3@1+ (1,0) [0|0] ""  JiaShiCang
 SG_ RPDU2_B3_SSPC_I_Load_11 : 40|8@1+ (0.1,0) [0|25.5] "A"  JiaShiCang
 SG_ RPDU2_B3_SSPC_TripSta_11 : 38|2@1+ (1,0) [0|3] ""  JiaShiCang
 SG_ RPDU2_B3_SSPC_BitErr_11 : 37|1@1+ (1,0) [0|1] ""  JiaShiCang
 SG_ RPDU2_B3_SSPC_OnOffSta_11 : 36|1@1+ (1,0) [0|1] ""  JiaShiCang
 SG_ RPDU2_B3_SSPC_DianHuErr_11 : 35|1@1+ (1,0) [0|1] ""  JiaShiCang
 SG_ BackUp302 : 32|3@1+ (1,0) [0|0] ""  JiaShiCang
 SG_ RPDU2_B3_SSPC_I_Load_10 : 24|8@1+ (0.1,0) [0|25.5] "A"  JiaShiCang
 SG_ RPDU2_B3_SSPC_TripSta_10 : 22|2@1+ (1,0) [0|3] ""  JiaShiCang
 SG_ RPDU2_B3_SSPC_BitErr_10 : 21|1@1+ (1,0) [0|1] ""  JiaShiCang
 SG_ RPDU2_B3_SSPC_OnOffSta_10 : 20|1@1+ (1,0) [0|1] ""  JiaShiCang
 SG_ RPDU2_B3_SSPC_DianHuErr_10 : 19|1@1+ (1,0) [0|1] ""  JiaShiCang
 SG_ BackUp301 : 16|3@1+ (1,0) [0|0] ""  JiaShiCang
 SG_ RPDU2_B3_SSPC_I_Load_09 : 8|8@1+ (0.1,0) [0|25.5] "A"  JiaShiCang
 SG_ RPDU2_B3_SSPC_TripSta_09 : 6|2@1+ (1,0) [0|3] ""  JiaShiCang
 SG_ RPDU2_B3_SSPC_BitErr_09 : 5|1@1+ (1,0) [0|1] ""  JiaShiCang
 SG_ RPDU2_B3_SSPC_OnOffSta_09 : 4|1@1+ (1,0) [0|1] ""  JiaShiCang
 SG_ RPDU2_B3_SSPC_DianHuErr_09 : 3|1@1+ (1,0) [0|1] ""  JiaShiCang
 SG_ BackUp300 : 0|3@1+ (1,0) [0|0] ""  JiaShiCang

BO_ 2417754144 Msg_R_RPDU2_B3_SSPC05_08: 8 R_BPCU_MCU
 SG_ RPDU2_B3_SSPC_I_Load_08 : 56|8@1+ (0.1,0) [0|25.5] "A"  JiaShiCang
 SG_ RPDU2_B3_SSPC_TripSta_08 : 54|2@1+ (1,0) [0|3] ""  JiaShiCang
 SG_ RPDU2_B3_SSPC_BitErr_08 : 53|1@1+ (1,0) [0|1] ""  JiaShiCang
 SG_ RPDU2_B3_SSPC_OnOffSta_08 : 52|1@1+ (1,0) [0|1] ""  JiaShiCang
 SG_ RPDU2_B3_SSPC_DianHuErr_08 : 51|1@1+ (1,0) [0|1] ""  JiaShiCang
 SG_ BackUp299 : 48|3@1+ (1,0) [0|0] ""  JiaShiCang
 SG_ RPDU2_B3_SSPC_I_Load_07 : 40|8@1+ (0.1,0) [0|25.5] "A"  JiaShiCang
 SG_ RPDU2_B3_SSPC_TripSta_07 : 38|2@1+ (1,0) [0|3] ""  JiaShiCang
 SG_ RPDU2_B3_SSPC_BitErr_07 : 37|1@1+ (1,0) [0|1] ""  JiaShiCang
 SG_ RPDU2_B3_SSPC_OnOffSta_07 : 36|1@1+ (1,0) [0|1] ""  JiaShiCang
 SG_ RPDU2_B3_SSPC_DianHuErr_07 : 35|1@1+ (1,0) [0|1] ""  JiaShiCang
 SG_ BackUp298 : 32|3@1+ (1,0) [0|0] ""  JiaShiCang
 SG_ RPDU2_B3_SSPC_I_Load_06 : 24|8@1+ (0.1,0) [0|25.5] "A"  JiaShiCang
 SG_ RPDU2_B3_SSPC_TripSta_06 : 22|2@1+ (1,0) [0|3] ""  JiaShiCang
 SG_ RPDU2_B3_SSPC_BitErr_06 : 21|1@1+ (1,0) [0|1] ""  JiaShiCang
 SG_ RPDU2_B3_SSPC_OnOffSta_06 : 20|1@1+ (1,0) [0|1] ""  JiaShiCang
 SG_ RPDU2_B3_SSPC_DianHuErr_06 : 19|1@1+ (1,0) [0|1] ""  JiaShiCang
 SG_ BackUp297 : 16|3@1+ (1,0) [0|0] ""  JiaShiCang
 SG_ RPDU2_B3_SSPC_I_Load_05 : 8|8@1+ (0.1,0) [0|25.5] "A"  JiaShiCang
 SG_ RPDU2_B3_SSPC_TripSta_05 : 6|2@1+ (1,0) [0|3] ""  JiaShiCang
 SG_ RPDU2_B3_SSPC_BitErr_05 : 5|1@1+ (1,0) [0|1] ""  JiaShiCang
 SG_ RPDU2_B3_SSPC_OnOffSta_05 : 4|1@1+ (1,0) [0|1] ""  JiaShiCang
 SG_ RPDU2_B3_SSPC_DianHuErr_05 : 3|1@1+ (1,0) [0|1] ""  JiaShiCang
 SG_ BackUp296 : 0|3@1+ (1,0) [0|0] ""  JiaShiCang

BO_ 2417688608 Msg_R_RPDU2_B3_SSPC01_04: 8 R_BPCU_MCU
 SG_ RPDU2_B3_SSPC_I_Load_04 : 56|8@1+ (0.1,0) [0|25.5] "A"  JiaShiCang
 SG_ RPDU2_B3_SSPC_TripSta_04 : 54|2@1+ (1,0) [0|3] ""  JiaShiCang
 SG_ RPDU2_B3_SSPC_BitErr_04 : 53|1@1+ (1,0) [0|1] ""  JiaShiCang
 SG_ RPDU2_B3_SSPC_OnOffSta_04 : 52|1@1+ (1,0) [0|1] ""  JiaShiCang
 SG_ RPDU2_B3_SSPC_DianHuErr_04 : 51|1@1+ (1,0) [0|1] ""  JiaShiCang
 SG_ BackUp295 : 48|3@1+ (1,0) [0|0] ""  JiaShiCang
 SG_ RPDU2_B3_SSPC_I_Load_03 : 40|8@1+ (0.1,0) [0|25.5] "A"  JiaShiCang
 SG_ RPDU2_B3_SSPC_TripSta_03 : 38|2@1+ (1,0) [0|3] ""  JiaShiCang
 SG_ RPDU2_B3_SSPC_BitErr_03 : 37|1@1+ (1,0) [0|1] ""  JiaShiCang
 SG_ RPDU2_B3_SSPC_OnOffSta_03 : 36|1@1+ (1,0) [0|1] ""  JiaShiCang
 SG_ RPDU2_B3_SSPC_DianHuErr_03 : 35|1@1+ (1,0) [0|1] ""  JiaShiCang
 SG_ BackUp294 : 32|3@1+ (1,0) [0|0] ""  JiaShiCang
 SG_ RPDU2_B3_SSPC_I_Load_02 : 24|8@1+ (0.1,0) [0|25.5] "A"  JiaShiCang
 SG_ RPDU2_B3_SSPC_TripSta_02 : 22|2@1+ (1,0) [0|3] ""  JiaShiCang
 SG_ RPDU2_B3_SSPC_BitErr_02 : 21|1@1+ (1,0) [0|1] ""  JiaShiCang
 SG_ RPDU2_B3_SSPC_OnOffSta_02 : 20|1@1+ (1,0) [0|1] ""  JiaShiCang
 SG_ RPDU2_B3_SSPC_DianHuErr_02 : 19|1@1+ (1,0) [0|1] ""  JiaShiCang
 SG_ BackUp293 : 16|3@1+ (1,0) [0|0] ""  JiaShiCang
 SG_ RPDU2_B3_SSPC_I_Load_01 : 8|8@1+ (0.1,0) [0|25.5] "A"  JiaShiCang
 SG_ RPDU2_B3_SSPC_TripSta_01 : 6|2@1+ (1,0) [0|3] ""  JiaShiCang
 SG_ RPDU2_B3_SSPC_BitErr_01 : 5|1@1+ (1,0) [0|1] ""  JiaShiCang
 SG_ RPDU2_B3_SSPC_OnOffSta_01 : 4|1@1+ (1,0) [0|1] ""  JiaShiCang
 SG_ RPDU2_B3_SSPC_DianHuErr_01 : 3|1@1+ (1,0) [0|1] ""  JiaShiCang
 SG_ BackUp292 : 0|3@1+ (1,0) [0|0] ""  JiaShiCang

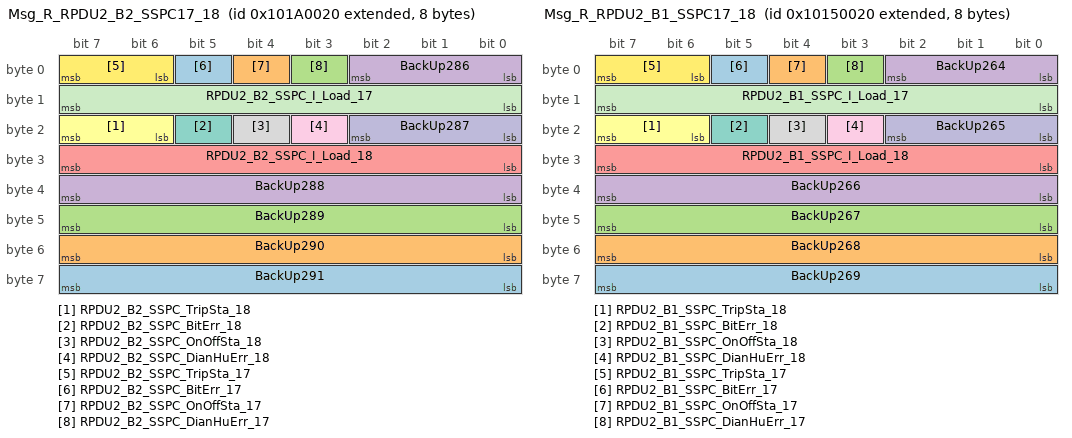
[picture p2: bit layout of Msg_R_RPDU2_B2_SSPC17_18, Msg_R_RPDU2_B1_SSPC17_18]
BO_ 2417623072 Msg_R_RPDU2_B2_SSPC17_18: 8 R_BPCU_MCU
 SG_ BackUp291 : 56|8@1+ (1,0) [0|0] ""  JiaShiCang
 SG_ BackUp290 : 48|8@1+ (1,0) [0|0] ""  JiaShiCang
 SG_ BackUp289 : 40|8@1+ (1,0) [0|0] ""  JiaShiCang
 SG_ BackUp288 : 32|8@1+ (1,0) [0|0] ""  JiaShiCang
 SG_ RPDU2_B2_SSPC_I_Load_18 : 24|8@1+ (0.1,0) [0|25.5] "A"  JiaShiCang
 SG_ RPDU2_B2_SSPC_TripSta_18 : 22|2@1+ (1,0) [0|3] ""  JiaShiCang
 SG_ RPDU2_B2_SSPC_BitErr_18 : 21|1@1+ (1,0) [0|1] ""  JiaShiCang
 SG_ RPDU2_B2_SSPC_OnOffSta_18 : 20|1@1+ (1,0) [0|1] ""  JiaShiCang
 SG_ RPDU2_B2_SSPC_DianHuErr_18 : 19|1@1+ (1,0) [0|1] ""  JiaShiCang
 SG_ BackUp287 : 16|3@1+ (1,0) [0|0] ""  JiaShiCang
 SG_ RPDU2_B2_SSPC_I_Load_17 : 8|8@1+ (0.1,0) [0|25.5] "A"  JiaShiCang
 SG_ RPDU2_B2_SSPC_TripSta_17 : 6|2@1+ (1,0) [0|3] ""  JiaShiCang
 SG_ RPDU2_B2_SSPC_BitErr_17 : 5|1@1+ (1,0) [0|1] ""  JiaShiCang
 SG_ RPDU2_B2_SSPC_OnOffSta_17 : 4|1@1+ (1,0) [0|1] ""  JiaShiCang
 SG_ RPDU2_B2_SSPC_DianHuErr_17 : 3|1@1+ (1,0) [0|1] ""  JiaShiCang
 SG_ BackUp286 : 0|3@1+ (1,0) [0|0] ""  JiaShiCang

BO_ 2417557536 Msg_R_RPDU2_B2_SSPC13_16: 8 R_BPCU_MCU
 SG_ RPDU2_B2_SSPC_I_Load_16 : 56|8@1+ (0.1,0) [0|25.5] "A"  JiaShiCang
 SG_ RPDU2_B2_SSPC_TripSta_16 : 54|2@1+ (1,0) [0|3] ""  JiaShiCang
 SG_ RPDU2_B2_SSPC_BitErr_16 : 53|1@1+ (1,0) [0|1] ""  JiaShiCang
 SG_ RPDU2_B2_SSPC_OnOffSta_16 : 52|1@1+ (1,0) [0|1] ""  JiaShiCang
 SG_ RPDU2_B2_SSPC_DianHuErr_16 : 51|1@1+ (1,0) [0|1] ""  JiaShiCang
 SG_ BackUp285 : 48|3@1+ (1,0) [0|0] ""  JiaShiCang
 SG_ RPDU2_B2_SSPC_I_Load_15 : 40|8@1+ (0.1,0) [0|25.5] "A"  JiaShiCang
 SG_ RPDU2_B2_SSPC_TripSta_15 : 38|2@1+ (1,0) [0|3] ""  JiaShiCang
 SG_ RPDU2_B2_SSPC_BitErr_15 : 37|1@1+ (1,0) [0|1] ""  JiaShiCang
 SG_ RPDU2_B2_SSPC_OnOffSta_15 : 36|1@1+ (1,0) [0|1] ""  JiaShiCang
 SG_ RPDU2_B2_SSPC_DianHuErr_15 : 35|1@1+ (1,0) [0|1] ""  JiaShiCang
 SG_ BackUp284 : 32|3@1+ (1,0) [0|0] ""  JiaShiCang
 SG_ RPDU2_B2_SSPC_I_Load_14 : 24|8@1+ (0.1,0) [0|25.5] "A"  JiaShiCang
 SG_ RPDU2_B2_SSPC_TripSta_14 : 22|2@1+ (1,0) [0|3] ""  JiaShiCang
 SG_ RPDU2_B2_SSPC_BitErr_14 : 21|1@1+ (1,0) [0|1] ""  JiaShiCang
 SG_ RPDU2_B2_SSPC_OnOffSta_14 : 20|1@1+ (1,0) [0|1] ""  JiaShiCang
 SG_ RPDU2_B2_SSPC_DianHuErr_14 : 19|1@1+ (1,0) [0|1] ""  JiaShiCang
 SG_ BackUp283 : 16|3@1+ (1,0) [0|0] ""  JiaShiCang
 SG_ RPDU2_B2_SSPC_I_Load_13 : 8|8@1+ (0.1,0) [0|25.5] "A"  JiaShiCang
 SG_ RPDU2_B2_SSPC_TripSta_13 : 6|2@1+ (1,0) [0|3] ""  JiaShiCang
 SG_ RPDU2_B2_SSPC_BitErr_13 : 5|1@1+ (1,0) [0|1] ""  JiaShiCang
 SG_ RPDU2_B2_SSPC_OnOffSta_13 : 4|1@1+ (1,0) [0|1] ""  JiaShiCang
 SG_ RPDU2_B2_SSPC_DianHuErr_13 : 3|1@1+ (1,0) [0|1] ""  JiaShiCang
 SG_ BackUp282 : 0|3@1+ (1,0) [0|0] ""  JiaShiCang

BO_ 2417492000 Msg_R_RPDU2_B2_SSPC09_12: 8 R_BPCU_MCU
 SG_ RPDU2_B2_SSPC_I_Load_12 : 56|8@1+ (0.1,0) [0|25.5] "A"  JiaShiCang
 SG_ RPDU2_B2_SSPC_TripSta_12 : 54|2@1+ (1,0) [0|3] ""  JiaShiCang
 SG_ RPDU2_B2_SSPC_BitErr_12 : 53|1@1+ (1,0) [0|1] ""  JiaShiCang
 SG_ RPDU2_B2_SSPC_OnOffSta_12 : 52|1@1+ (1,0) [0|1] ""  JiaShiCang
 SG_ RPDU2_B2_SSPC_DianHuErr_12 : 51|1@1+ (1,0) [0|1] ""  JiaShiCang
 SG_ BackUp281 : 48|3@1+ (1,0) [0|0] ""  JiaShiCang
 SG_ RPDU2_B2_SSPC_I_Load_11 : 40|8@1+ (0.1,0) [0|25.5] "A"  JiaShiCang
 SG_ RPDU2_B2_SSPC_TripSta_11 : 38|2@1+ (1,0) [0|3] ""  JiaShiCang
 SG_ RPDU2_B2_SSPC_BitErr_11 : 37|1@1+ (1,0) [0|1] ""  JiaShiCang
 SG_ RPDU2_B2_SSPC_OnOffSta_11 : 36|1@1+ (1,0) [0|1] ""  JiaShiCang
 SG_ RPDU2_B2_SSPC_DianHuErr_11 : 35|1@1+ (1,0) [0|1] ""  JiaShiCang
 SG_ BackUp280 : 32|3@1+ (1,0) [0|0] ""  JiaShiCang
 SG_ RPDU2_B2_SSPC_I_Load_10 : 24|8@1+ (0.1,0) [0|25.5] "A"  JiaShiCang
 SG_ RPDU2_B2_SSPC_TripSta_10 : 22|2@1+ (1,0) [0|3] ""  JiaShiCang
 SG_ RPDU2_B2_SSPC_BitErr_10 : 21|1@1+ (1,0) [0|1] ""  JiaShiCang
 SG_ RPDU2_B2_SSPC_OnOffSta_10 : 20|1@1+ (1,0) [0|1] ""  JiaShiCang
 SG_ RPDU2_B2_SSPC_DianHuErr_10 : 19|1@1+ (1,0) [0|1] ""  JiaShiCang
 SG_ BackUp279 : 16|3@1+ (1,0) [0|0] ""  JiaShiCang
 SG_ RPDU2_B2_SSPC_I_Load_09 : 8|8@1+ (0.1,0) [0|25.5] "A"  JiaShiCang
 SG_ RPDU2_B2_SSPC_TripSta_09 : 6|2@1+ (1,0) [0|3] ""  JiaShiCang
 SG_ RPDU2_B2_SSPC_BitErr_09 : 5|1@1+ (1,0) [0|1] ""  JiaShiCang
 SG_ RPDU2_B2_SSPC_OnOffSta_09 : 4|1@1+ (1,0) [0|1] ""  JiaShiCang
 SG_ RPDU2_B2_SSPC_DianHuErr_09 : 3|1@1+ (1,0) [0|1] ""  JiaShiCang
 SG_ BackUp278 : 0|3@1+ (1,0) [0|0] ""  JiaShiCang

BO_ 2417426464 Msg_R_RPDU2_B2_SSPC05_08: 8 R_BPCU_MCU
 SG_ RPDU2_B2_SSPC_I_Load_08 : 56|8@1+ (0.1,0) [0|25.5] "A"  JiaShiCang
 SG_ RPDU2_B2_SSPC_TripSta_08 : 54|2@1+ (1,0) [0|3] ""  JiaShiCang
 SG_ RPDU2_B2_SSPC_BitErr_08 : 53|1@1+ (1,0) [0|1] ""  JiaShiCang
 SG_ RPDU2_B2_SSPC_OnOffSta_08 : 52|1@1+ (1,0) [0|1] ""  JiaShiCang
 SG_ RPDU2_B2_SSPC_DianHuErr_08 : 51|1@1+ (1,0) [0|1] ""  JiaShiCang
 SG_ BackUp277 : 48|3@1+ (1,0) [0|0] ""  JiaShiCang
 SG_ RPDU2_B2_SSPC_I_Load_07 : 40|8@1+ (0.1,0) [0|25.5] "A"  JiaShiCang
 SG_ RPDU2_B2_SSPC_TripSta_07 : 38|2@1+ (1,0) [0|3] ""  JiaShiCang
 SG_ RPDU2_B2_SSPC_BitErr_07 : 37|1@1+ (1,0) [0|1] ""  JiaShiCang
 SG_ RPDU2_B2_SSPC_OnOffSta_07 : 36|1@1+ (1,0) [0|1] ""  JiaShiCang
 SG_ RPDU2_B2_SSPC_DianHuErr_07 : 35|1@1+ (1,0) [0|1] ""  JiaShiCang
 SG_ BackUp276 : 32|3@1+ (1,0) [0|0] ""  JiaShiCang
 SG_ RPDU2_B2_SSPC_I_Load_06 : 24|8@1+ (0.1,0) [0|25.5] "A"  JiaShiCang
 SG_ RPDU2_B2_SSPC_TripSta_06 : 22|2@1+ (1,0) [0|3] ""  JiaShiCang
 SG_ RPDU2_B2_SSPC_BitErr_06 : 21|1@1+ (1,0) [0|1] ""  JiaShiCang
 SG_ RPDU2_B2_SSPC_OnOffSta_06 : 20|1@1+ (1,0) [0|1] ""  JiaShiCang
 SG_ RPDU2_B2_SSPC_DianHuErr_06 : 19|1@1+ (1,0) [0|1] ""  JiaShiCang
 SG_ BackUp275 : 16|3@1+ (1,0) [0|0] ""  JiaShiCang
 SG_ RPDU2_B2_SSPC_I_Load_05 : 8|8@1+ (0.1,0) [0|25.5] "A"  JiaShiCang
 SG_ RPDU2_B2_SSPC_TripSta_05 : 6|2@1+ (1,0) [0|3] ""  JiaShiCang
 SG_ RPDU2_B2_SSPC_BitErr_05 : 5|1@1+ (1,0) [0|1] ""  JiaShiCang
 SG_ RPDU2_B2_SSPC_OnOffSta_05 : 4|1@1+ (1,0) [0|1] ""  JiaShiCang
 SG_ RPDU2_B2_SSPC_DianHuErr_05 : 3|1@1+ (1,0) [0|1] ""  JiaShiCang
 SG_ BackUp274 : 0|3@1+ (1,0) [0|0] ""  JiaShiCang

BO_ 2417360928 Msg_R_RPDU2_B2_SSPC01_04: 8 R_BPCU_MCU
 SG_ RPDU2_B2_SSPC_I_Load_04 : 56|8@1+ (0.1,0) [0|25.5] "A"  JiaShiCang
 SG_ RPDU2_B2_SSPC_TripSta_04 : 54|2@1+ (1,0) [0|3] ""  JiaShiCang
 SG_ RPDU2_B2_SSPC_BitErr_04 : 53|1@1+ (1,0) [0|1] ""  JiaShiCang
 SG_ RPDU2_B2_SSPC_OnOffSta_04 : 52|1@1+ (1,0) [0|1] ""  JiaShiCang
 SG_ RPDU2_B2_SSPC_DianHuErr_04 : 51|1@1+ (1,0) [0|1] ""  JiaShiCang
 SG_ BackUp273 : 48|3@1+ (1,0) [0|0] ""  JiaShiCang
 SG_ RPDU2_B2_SSPC_I_Load_03 : 40|8@1+ (0.1,0) [0|25.5] "A"  JiaShiCang
 SG_ RPDU2_B2_SSPC_TripSta_03 : 38|2@1+ (1,0) [0|3] ""  JiaShiCang
 SG_ RPDU2_B2_SSPC_BitErr_03 : 37|1@1+ (1,0) [0|1] ""  JiaShiCang
 SG_ RPDU2_B2_SSPC_OnOffSta_03 : 36|1@1+ (1,0) [0|1] ""  JiaShiCang
 SG_ RPDU2_B2_SSPC_DianHuErr_03 : 35|1@1+ (1,0) [0|1] ""  JiaShiCang
 SG_ BackUp272 : 32|3@1+ (1,0) [0|0] ""  JiaShiCang
 SG_ RPDU2_B2_SSPC_I_Load_02 : 24|8@1+ (0.1,0) [0|25.5] "A"  JiaShiCang
 SG_ RPDU2_B2_SSPC_TripSta_02 : 22|2@1+ (1,0) [0|3] ""  JiaShiCang
 SG_ RPDU2_B2_SSPC_BitErr_02 : 21|1@1+ (1,0) [0|1] ""  JiaShiCang
 SG_ RPDU2_B2_SSPC_OnOffSta_02 : 20|1@1+ (1,0) [0|1] ""  JiaShiCang
 SG_ RPDU2_B2_SSPC_DianHuErr_02 : 19|1@1+ (1,0) [0|1] ""  JiaShiCang
 SG_ BackUp271 : 16|3@1+ (1,0) [0|0] ""  JiaShiCang
 SG_ RPDU2_B2_SSPC_I_Load_01 : 8|8@1+ (0.1,0) [0|25.5] "A"  JiaShiCang
 SG_ RPDU2_B2_SSPC_TripSta_01 : 6|2@1+ (1,0) [0|3] ""  JiaShiCang
 SG_ RPDU2_B2_SSPC_BitErr_01 : 5|1@1+ (1,0) [0|1] ""  JiaShiCang
 SG_ RPDU2_B2_SSPC_OnOffSta_01 : 4|1@1+ (1,0) [0|1] ""  JiaShiCang
 SG_ RPDU2_B2_SSPC_DianHuErr_01 : 3|1@1+ (1,0) [0|1] ""  JiaShiCang
 SG_ BackUp270 : 0|3@1+ (1,0) [0|0] ""  JiaShiCang

BO_ 2417295392 Msg_R_RPDU2_B1_SSPC17_18: 8 R_BPCU_MCU
 SG_ BackUp269 : 56|8@1+ (1,0) [0|0] ""  JiaShiCang
 SG_ BackUp268 : 48|8@1+ (1,0) [0|0] ""  JiaShiCang
 SG_ BackUp267 : 40|8@1+ (1,0) [0|0] ""  JiaShiCang
 SG_ BackUp266 : 32|8@1+ (1,0) [0|0] ""  JiaShiCang
 SG_ RPDU2_B1_SSPC_I_Load_18 : 24|8@1+ (0.1,0) [0|25.5] "A"  JiaShiCang
 SG_ RPDU2_B1_SSPC_TripSta_18 : 22|2@1+ (1,0) [0|3] ""  JiaShiCang
 SG_ RPDU2_B1_SSPC_BitErr_18 : 21|1@1+ (1,0) [0|1] ""  JiaShiCang
 SG_ RPDU2_B1_SSPC_OnOffSta_18 : 20|1@1+ (1,0) [0|1] ""  JiaShiCang
 SG_ RPDU2_B1_SSPC_DianHuErr_18 : 19|1@1+ (1,0) [0|1] ""  JiaShiCang
 SG_ BackUp265 : 16|3@1+ (1,0) [0|0] ""  JiaShiCang
 SG_ RPDU2_B1_SSPC_I_Load_17 : 8|8@1+ (0.1,0) [0|25.5] "A"  JiaShiCang
 SG_ RPDU2_B1_SSPC_TripSta_17 : 6|2@1+ (1,0) [0|3] ""  JiaShiCang
 SG_ RPDU2_B1_SSPC_BitErr_17 : 5|1@1+ (1,0) [0|1] ""  JiaShiCang
 SG_ RPDU2_B1_SSPC_OnOffSta_17 : 4|1@1+ (1,0) [0|1] ""  JiaShiCang
 SG_ RPDU2_B1_SSPC_DianHuErr_17 : 3|1@1+ (1,0) [0|1] ""  JiaShiCang
 SG_ BackUp264 : 0|3@1+ (1,0) [0|0] ""  JiaShiCang

BO_ 2417229856 Msg_R_RPDU2_B1_SSPC13_16: 8 R_BPCU_MCU
 SG_ RPDU2_B1_SSPC_I_Load_16 : 56|8@1+ (0.1,0) [0|25.5] "A"  JiaShiCang
 SG_ RPDU2_B1_SSPC_TripSta_16 : 54|2@1+ (1,0) [0|3] ""  JiaShiCang
 SG_ RPDU2_B1_SSPC_BitErr_16 : 53|1@1+ (1,0) [0|1] ""  JiaShiCang
 SG_ RPDU2_B1_SSPC_OnOffSta_16 : 52|1@1+ (1,0) [0|1] ""  JiaShiCang
 SG_ RPDU2_B1_SSPC_DianHuErr_16 : 51|1@1+ (1,0) [0|1] ""  JiaShiCang
 SG_ BackUp263 : 48|3@1+ (1,0) [0|0] ""  JiaShiCang
 SG_ RPDU2_B1_SSPC_I_Load_15 : 40|8@1+ (0.1,0) [0|25.5] "A"  JiaShiCang
 SG_ RPDU2_B1_SSPC_TripSta_15 : 38|2@1+ (1,0) [0|3] ""  JiaShiCang
 SG_ RPDU2_B1_SSPC_BitErr_15 : 37|1@1+ (1,0) [0|1] ""  JiaShiCang
 SG_ RPDU2_B1_SSPC_OnOffSta_15 : 36|1@1+ (1,0) [0|1] ""  JiaShiCang
 SG_ RPDU2_B1_SSPC_DianHuErr_15 : 35|1@1+ (1,0) [0|1] ""  JiaShiCang
 SG_ BackUp262 : 32|3@1+ (1,0) [0|0] ""  JiaShiCang
 SG_ RPDU2_B1_SSPC_I_Load_14 : 24|8@1+ (0.1,0) [0|25.5] "A"  JiaShiCang
 SG_ RPDU2_B1_SSPC_TripSta_14 : 22|2@1+ (1,0) [0|3] ""  JiaShiCang
 SG_ RPDU2_B1_SSPC_BitErr_14 : 21|1@1+ (1,0) [0|1] ""  JiaShiCang
 SG_ RPDU2_B1_SSPC_OnOffSta_14 : 20|1@1+ (1,0) [0|1] ""  JiaShiCang
 SG_ RPDU2_B1_SSPC_DianHuErr_14 : 19|1@1+ (1,0) [0|1] ""  JiaShiCang
 SG_ BackUp261 : 16|3@1+ (1,0) [0|0] ""  JiaShiCang
 SG_ RPDU2_B1_SSPC_I_Load_13 : 8|8@1+ (0.1,0) [0|25.5] "A"  JiaShiCang
 SG_ RPDU2_B1_SSPC_TripSta_13 : 6|2@1+ (1,0) [0|3] ""  JiaShiCang
 SG_ RPDU2_B1_SSPC_BitErr_13 : 5|1@1+ (1,0) [0|1] ""  JiaShiCang
 SG_ RPDU2_B1_SSPC_OnOffSta_13 : 4|1@1+ (1,0) [0|1] ""  JiaShiCang
 SG_ RPDU2_B1_SSPC_DianHuErr_13 : 3|1@1+ (1,0) [0|1] ""  JiaShiCang
 SG_ BackUp260 : 0|3@1+ (1,0) [0|0] ""  JiaShiCang

BO_ 2417164320 Msg_R_RPDU2_B1_SSPC09_12: 8 R_BPCU_MCU
 SG_ RPDU2_B1_SSPC_I_Load_12 : 56|8@1+ (0.1,0) [0|25.5] "A"  JiaShiCang
 SG_ RPDU2_B1_SSPC_TripSta_12 : 54|2@1+ (1,0) [0|3] ""  JiaShiCang
 SG_ RPDU2_B1_SSPC_BitErr_12 : 53|1@1+ (1,0) [0|1] ""  JiaShiCang
 SG_ RPDU2_B1_SSPC_OnOffSta_12 : 52|1@1+ (1,0) [0|1] ""  JiaShiCang
 SG_ RPDU2_B1_SSPC_DianHuErr_12 : 51|1@1+ (1,0) [0|1] ""  JiaShiCang
 SG_ BackUp259 : 48|3@1+ (1,0) [0|0] ""  JiaShiCang
 SG_ RPDU2_B1_SSPC_I_Load_11 : 40|8@1+ (0.1,0) [0|25.5] "A"  JiaShiCang
 SG_ RPDU2_B1_SSPC_TripSta_11 : 38|2@1+ (1,0) [0|3] ""  JiaShiCang
 SG_ RPDU2_B1_SSPC_BitErr_11 : 37|1@1+ (1,0) [0|1] ""  JiaShiCang
 SG_ RPDU2_B1_SSPC_OnOffSta_11 : 36|1@1+ (1,0) [0|1] ""  JiaShiCang
 SG_ RPDU2_B1_SSPC_DianHuErr_11 : 35|1@1+ (1,0) [0|1] ""  JiaShiCang
 SG_ BackUp258 : 32|3@1+ (1,0) [0|0] ""  JiaShiCang
 SG_ RPDU2_B1_SSPC_I_Load_10 : 24|8@1+ (0.1,0) [0|25.5] "A"  JiaShiCang
 SG_ RPDU2_B1_SSPC_TripSta_10 : 22|2@1+ (1,0) [0|3] ""  JiaShiCang
 SG_ RPDU2_B1_SSPC_BitErr_10 : 21|1@1+ (1,0) [0|1] ""  JiaShiCang
 SG_ RPDU2_B1_SSPC_OnOffSta_10 : 20|1@1+ (1,0) [0|1] ""  JiaShiCang
 SG_ RPDU2_B1_SSPC_DianHuErr_10 : 19|1@1+ (1,0) [0|1] ""  JiaShiCang
 SG_ BackUp257 : 16|3@1+ (1,0) [0|0] ""  JiaShiCang
 SG_ RPDU2_B1_SSPC_I_Load_09 : 8|8@1+ (0.1,0) [0|25.5] "A"  JiaShiCang
 SG_ RPDU2_B1_SSPC_TripSta_09 : 6|2@1+ (1,0) [0|3] ""  JiaShiCang
 SG_ RPDU2_B1_SSPC_BitErr_09 : 5|1@1+ (1,0) [0|1] ""  JiaShiCang
 SG_ RPDU2_B1_SSPC_OnOffSta_09 : 4|1@1+ (1,0) [0|1] ""  JiaShiCang
 SG_ RPDU2_B1_SSPC_DianHuErr_09 : 3|1@1+ (1,0) [0|1] ""  JiaShiCang
 SG_ BackUp256 : 0|3@1+ (1,0) [0|0] ""  JiaShiCang

BO_ 2417098784 Msg_R_RPDU2_B1_SSPC05_08: 8 R_BPCU_MCU
 SG_ RPDU2_B1_SSPC_I_Load_08 : 56|8@1+ (0.1,0) [0|25.5] "A"  JiaShiCang
 SG_ RPDU2_B1_SSPC_TripSta_08 : 54|2@1+ (1,0) [0|3] ""  JiaShiCang
 SG_ RPDU2_B1_SSPC_BitErr_08 : 53|1@1+ (1,0) [0|1] ""  JiaShiCang
 SG_ RPDU2_B1_SSPC_OnOffSta_08 : 52|1@1+ (1,0) [0|1] ""  JiaShiCang
 SG_ RPDU2_B1_SSPC_DianHuErr_08 : 51|1@1+ (1,0) [0|1] ""  JiaShiCang
 SG_ BackUp255 : 48|3@1+ (1,0) [0|0] ""  JiaShiCang
 SG_ RPDU2_B1_SSPC_I_Load_07 : 40|8@1+ (0.1,0) [0|25.5] "A"  JiaShiCang
 SG_ RPDU2_B1_SSPC_TripSta_07 : 38|2@1+ (1,0) [0|3] ""  JiaShiCang
 SG_ RPDU2_B1_SSPC_BitErr_07 : 37|1@1+ (1,0) [0|1] ""  JiaShiCang
 SG_ RPDU2_B1_SSPC_OnOffSta_07 : 36|1@1+ (1,0) [0|1] ""  JiaShiCang
 SG_ RPDU2_B1_SSPC_DianHuErr_07 : 35|1@1+ (1,0) [0|1] ""  JiaShiCang
 SG_ BackUp254 : 32|3@1+ (1,0) [0|0] ""  JiaShiCang
 SG_ RPDU2_B1_SSPC_I_Load_06 : 24|8@1+ (0.1,0) [0|25.5] "A"  JiaShiCang
 SG_ RPDU2_B1_SSPC_TripSta_06 : 22|2@1+ (1,0) [0|3] ""  JiaShiCang
 SG_ RPDU2_B1_SSPC_BitErr_06 : 21|1@1+ (1,0) [0|1] ""  JiaShiCang
 SG_ RPDU2_B1_SSPC_OnOffSta_06 : 20|1@1+ (1,0) [0|1] ""  JiaShiCang
 SG_ RPDU2_B1_SSPC_DianHuErr_06 : 19|1@1+ (1,0) [0|1] ""  JiaShiCang
 SG_ BackUp253 : 16|3@1+ (1,0) [0|0] ""  JiaShiCang
 SG_ RPDU2_B1_SSPC_I_Load_05 : 8|8@1+ (0.1,0) [0|25.5] "A"  JiaShiCang
 SG_ RPDU2_B1_SSPC_TripSta_05 : 6|2@1+ (1,0) [0|3] ""  JiaShiCang
 SG_ RPDU2_B1_SSPC_BitErr_05 : 5|1@1+ (1,0) [0|1] ""  JiaShiCang
 SG_ RPDU2_B1_SSPC_OnOffSta_05 : 4|1@1+ (1,0) [0|1] ""  JiaShiCang
 SG_ RPDU2_B1_SSPC_DianHuErr_05 : 3|1@1+ (1,0) [0|1] ""  JiaShiCang
 SG_ BackUp252 : 0|3@1+ (1,0) [0|0] ""  JiaShiCang

BO_ 2417033248 Msg_R_RPDU2_B1_SSPC01_04: 8 R_BPCU_MCU
 SG_ RPDU2_B1_SSPC_I_Load_04 : 56|8@1+ (0.1,0) [0|25.5] "A"  JiaShiCang
 SG_ RPDU2_B1_SSPC_TripSta_04 : 54|2@1+ (1,0) [0|3] ""  JiaShiCang
 SG_ RPDU2_B1_SSPC_BitErr_04 : 53|1@1+ (1,0) [0|1] ""  JiaShiCang
 SG_ RPDU2_B1_SSPC_OnOffSta_04 : 52|1@1+ (1,0) [0|1] ""  JiaShiCang
 SG_ RPDU2_B1_SSPC_DianHuErr_04 : 51|1@1+ (1,0) [0|1] ""  JiaShiCang
 SG_ BackUp251 : 48|3@1+ (1,0) [0|0] ""  JiaShiCang
 SG_ RPDU2_B1_SSPC_I_Load_03 : 40|8@1+ (0.1,0) [0|25.5] "A"  JiaShiCang
 SG_ RPDU2_B1_SSPC_TripSta_03 : 38|2@1+ (1,0) [0|3] ""  JiaShiCang
 SG_ RPDU2_B1_SSPC_BitErr_03 : 37|1@1+ (1,0) [0|1] ""  JiaShiCang
 SG_ RPDU2_B1_SSPC_OnOffSta_03 : 36|1@1+ (1,0) [0|1] ""  JiaShiCang
 SG_ RPDU2_B1_SSPC_DianHuErr_03 : 35|1@1+ (1,0) [0|1] ""  JiaShiCang
 SG_ BackUp250 : 32|3@1+ (1,0) [0|0] ""  JiaShiCang
 SG_ RPDU2_B1_SSPC_I_Load_02 : 24|8@1+ (0.1,0) [0|25.5] "A"  JiaShiCang
 SG_ RPDU2_B1_SSPC_TripSta_02 : 22|2@1+ (1,0) [0|3] ""  JiaShiCang
 SG_ RPDU2_B1_SSPC_BitErr_02 : 21|1@1+ (1,0) [0|1] ""  JiaShiCang
 SG_ RPDU2_B1_SSPC_OnOffSta_02 : 20|1@1+ (1,0) [0|1] ""  JiaShiCang
 SG_ RPDU2_B1_SSPC_DianHuErr_02 : 19|1@1+ (1,0) [0|1] ""  JiaShiCang
 SG_ BackUp249 : 16|3@1+ (1,0) [0|0] ""  JiaShiCang
 SG_ RPDU2_B1_SSPC_I_Load_01 : 8|8@1+ (0.1,0) [0|25.5] "A"  JiaShiCang
 SG_ RPDU2_B1_SSPC_TripSta_01 : 6|2@1+ (1,0) [0|3] ""  JiaShiCang
 SG_ RPDU2_B1_SSPC_BitErr_01 : 5|1@1+ (1,0) [0|1] ""  JiaShiCang
 SG_ RPDU2_B1_SSPC_OnOffSta_01 : 4|1@1+ (1,0) [0|1] ""  JiaShiCang
 SG_ RPDU2_B1_SSPC_DianHuErr_01 : 3|1@1+ (1,0) [0|1] ""  JiaShiCang
 SG_ BackUp248 : 0|3@1+ (1,0) [0|0] ""  JiaShiCang

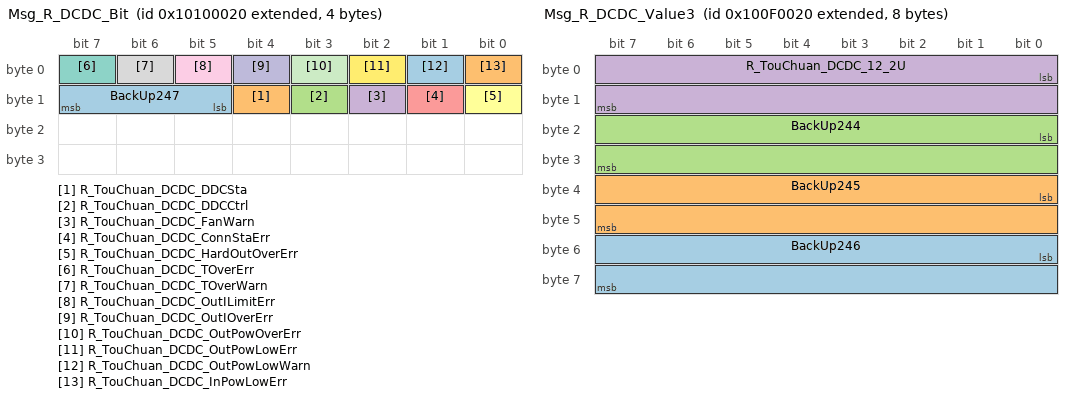
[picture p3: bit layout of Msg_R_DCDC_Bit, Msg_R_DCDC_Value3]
BO_ 2416967712 Msg_R_DCDC_Bit: 4 R_BPCU_MCU
 SG_ BackUp247 : 13|3@1+ (1,0) [0|0] ""  JiaShiCang
 SG_ R_TouChuan_DCDC_DDCSta : 12|1@1+ (1,0) [0|1] ""  JiaShiCang
 SG_ R_TouChuan_DCDC_DDCCtrl : 11|1@1+ (1,0) [0|1] ""  JiaShiCang
 SG_ R_TouChuan_DCDC_FanWarn : 10|1@1+ (1,0) [0|1] ""  JiaShiCang
 SG_ R_TouChuan_DCDC_ConnStaErr : 9|1@1+ (1,0) [0|1] ""  JiaShiCang
 SG_ R_TouChuan_DCDC_HardOutOverErr : 8|1@1+ (1,0) [0|1] ""  JiaShiCang
 SG_ R_TouChuan_DCDC_TOverErr : 7|1@1+ (1,0) [0|1] ""  JiaShiCang
 SG_ R_TouChuan_DCDC_TOverWarn : 6|1@1+ (1,0) [0|1] ""  JiaShiCang
 SG_ R_TouChuan_DCDC_OutILimitErr : 5|1@1+ (1,0) [0|1] ""  JiaShiCang
 SG_ R_TouChuan_DCDC_OutIOverErr : 4|1@1+ (1,0) [0|1] ""  JiaShiCang
 SG_ R_TouChuan_DCDC_OutPowOverErr : 3|1@1+ (1,0) [0|1] ""  JiaShiCang
 SG_ R_TouChuan_DCDC_OutPowLowErr : 2|1@1+ (1,0) [0|1] ""  JiaShiCang
 SG_ R_TouChuan_DCDC_OutPowLowWarn : 1|1@1+ (1,0) [0|1] ""  JiaShiCang
 SG_ R_TouChuan_DCDC_InPowLowErr : 0|1@1+ (1,0) [0|1] ""  JiaShiCang

BO_ 2416902176 Msg_R_DCDC_Value3: 8 R_BPCU_MCU
 SG_ BackUp246 : 48|16@1+ (1,0) [0|0] ""  JiaShiCang
 SG_ BackUp245 : 32|16@1+ (1,0) [0|0] ""  JiaShiCang
 SG_ BackUp244 : 16|16@1+ (1,0) [0|0] ""  JiaShiCang
 SG_ R_TouChuan_DCDC_12_2U : 0|16@1+ (0.1,0) [0|6553.5] "V"  JiaShiCang

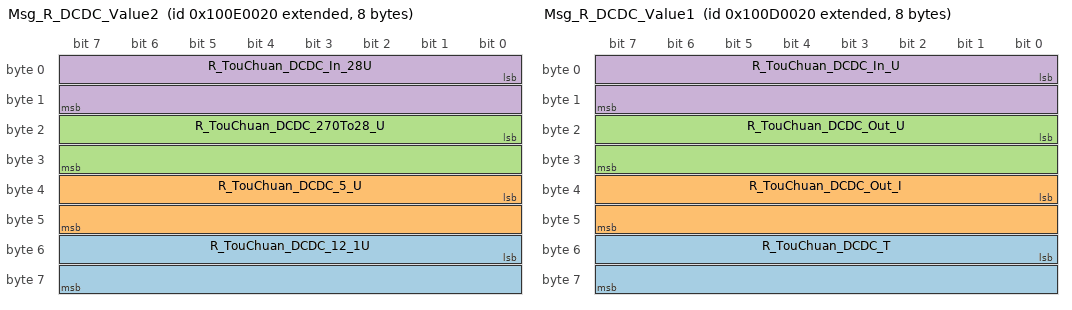
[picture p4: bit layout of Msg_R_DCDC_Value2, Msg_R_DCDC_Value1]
BO_ 2416836640 Msg_R_DCDC_Value2: 8 R_BPCU_MCU
 SG_ R_TouChuan_DCDC_12_1U : 48|16@1+ (0.1,0) [0|6553.5] "V"  JiaShiCang
 SG_ R_TouChuan_DCDC_5_U : 32|16@1+ (0.1,0) [0|6553.5] "V"  JiaShiCang
 SG_ R_TouChuan_DCDC_270To28_U : 16|16@1+ (0.1,0) [0|6553.5] "V"  JiaShiCang
 SG_ R_TouChuan_DCDC_In_28U : 0|16@1+ (0.1,0) [0|6553.5] "V"  JiaShiCang

BO_ 2416771104 Msg_R_DCDC_Value1: 8 R_BPCU_MCU
 SG_ R_TouChuan_DCDC_T : 48|16@1+ (1,-55) [-55|65480] ""  JiaShiCang
 SG_ R_TouChuan_DCDC_Out_I : 32|16@1+ (0.1,0) [0|6553.5] "A"  JiaShiCang
 SG_ R_TouChuan_DCDC_Out_U : 16|16@1+ (0.1,0) [0|6553.5] "V"  JiaShiCang
 SG_ R_TouChuan_DCDC_In_U : 0|16@1+ (0.1,0) [0|6553.5] "V"  JiaShiCang

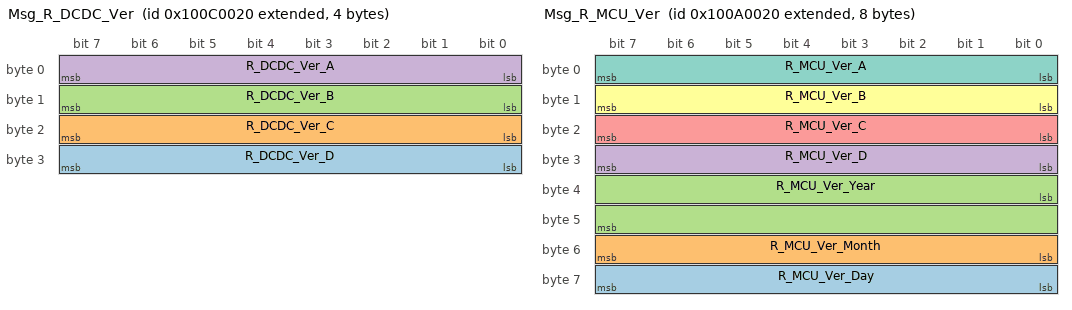
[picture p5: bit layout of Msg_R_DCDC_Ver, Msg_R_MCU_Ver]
BO_ 2416705568 Msg_R_DCDC_Ver: 4 R_BPCU_MCU
 SG_ R_DCDC_Ver_D : 24|8@1+ (1,0) [0|153] ""  JiaShiCang
 SG_ R_DCDC_Ver_C : 16|8@1+ (1,0) [0|153] ""  JiaShiCang
 SG_ R_DCDC_Ver_B : 8|8@1+ (1,0) [0|153] ""  JiaShiCang
 SG_ R_DCDC_Ver_A : 0|8@1+ (1,0) [0|153] ""  JiaShiCang

BO_ 2416574496 Msg_R_MCU_Ver: 8 R_BPCU_MCU
 SG_ R_MCU_Ver_Day : 56|8@1+ (1,0) [1|49] ""  JiaShiCang
 SG_ R_MCU_Ver_Month : 48|8@1+ (1,0) [1|18] ""  JiaShiCang
 SG_ R_MCU_Ver_Year : 32|16@1+ (1,0) [0|39321] ""  JiaShiCang
 SG_ R_MCU_Ver_D : 24|8@1+ (1,0) [0|153] ""  JiaShiCang
 SG_ R_MCU_Ver_C : 16|8@1+ (1,0) [0|153] ""  JiaShiCang
 SG_ R_MCU_Ver_B : 8|8@1+ (1,0) [0|153] ""  JiaShiCang
 SG_ R_MCU_Ver_A : 0|8@1+ (1,0) [0|153] ""  JiaShiCang

BO_ 2416508960 Msg_R_DuanLuQi_State: 7 R_BPCU_MCU
 SG_ BackUp243 : 49|7@1+ (1,0) [0|0] ""  JiaShiCang
 SG_ R_DuanLuQi_Sta_49 : 48|1@1+ (1,0) [0|1] ""  JiaShiCang
 SG_ R_DuanLuQi_Sta_48 : 47|1@1+ (1,0) [0|1] ""  JiaShiCang
 SG_ R_DuanLuQi_Sta_47 : 46|1@1+ (1,0) [0|1] ""  JiaShiCang
 SG_ R_DuanLuQi_Sta_46 : 45|1@1+ (1,0) [0|1] ""  JiaShiCang
 SG_ R_DuanLuQi_Sta_45 : 44|1@1+ (1,0) [0|1] ""  JiaShiCang
 SG_ R_DuanLuQi_Sta_44 : 43|1@1+ (1,0) [0|1] ""  JiaShiCang
 SG_ R_DuanLuQi_Sta_43 : 42|1@1+ (1,0) [0|1] ""  JiaShiCang
 SG_ R_DuanLuQi_Sta_42 : 41|1@1+ (1,0) [0|1] ""  JiaShiCang
 SG_ R_DuanLuQi_Sta_41 : 40|1@1+ (1,0) [0|1] ""  JiaShiCang
 SG_ R_DuanLuQi_Sta_40 : 39|1@1+ (1,0) [0|1] ""  JiaShiCang
 SG_ R_DuanLuQi_Sta_39 : 38|1@1+ (1,0) [0|1] ""  JiaShiCang
 SG_ R_DuanLuQi_Sta_38 : 37|1@1+ (1,0) [0|1] ""  JiaShiCang
 SG_ R_DuanLuQi_Sta_37 : 36|1@1+ (1,0) [0|1] ""  JiaShiCang
 SG_ R_DuanLuQi_Sta_36 : 35|1@1+ (1,0) [0|1] ""  JiaShiCang
 SG_ R_DuanLuQi_Sta_35 : 34|1@1+ (1,0) [0|1] ""  JiaShiCang
 SG_ R_DuanLuQi_Sta_34 : 33|1@1+ (1,0) [0|1] ""  JiaShiCang
 SG_ R_DuanLuQi_Sta_33 : 32|1@1+ (1,0) [0|1] ""  JiaShiCang
 SG_ R_DuanLuQi_Sta_32 : 31|1@1+ (1,0) [0|1] ""  JiaShiCang
 SG_ R_DuanLuQi_Sta_31 : 30|1@1+ (1,0) [0|1] ""  JiaShiCang
 SG_ R_DuanLuQi_Sta_30 : 29|1@1+ (1,0) [0|1] ""  JiaShiCang
 SG_ R_DuanLuQi_Sta_29 : 28|1@1+ (1,0) [0|1] ""  JiaShiCang
 SG_ R_DuanLuQi_Sta_28 : 27|1@1+ (1,0) [0|1] ""  JiaShiCang
 SG_ R_DuanLuQi_Sta_27 : 26|1@1+ (1,0) [0|1] ""  JiaShiCang
 SG_ R_DuanLuQi_Sta_26 : 25|1@1+ (1,0) [0|1] ""  JiaShiCang
 SG_ R_DuanLuQi_Sta_25 : 24|1@1+ (1,0) [0|1] ""  JiaShiCang
 SG_ R_DuanLuQi_Sta_24 : 23|1@1+ (1,0) [0|1] ""  JiaShiCang
 SG_ R_DuanLuQi_Sta_23 : 22|1@1+ (1,0) [0|1] ""  JiaShiCang
 SG_ R_DuanLuQi_Sta_22 : 21|1@1+ (1,0) [0|1] ""  JiaShiCang
 SG_ R_DuanLuQi_Sta_21 : 20|1@1+ (1,0) [0|1] ""  JiaShiCang
 SG_ R_DuanLuQi_Sta_20 : 19|1@1+ (1,0) [0|1] ""  JiaShiCang
 SG_ R_DuanLuQi_Sta_19 : 18|1@1+ (1,0) [0|1] ""  JiaShiCang
 SG_ R_DuanLuQi_Sta_18 : 17|1@1+ (1,0) [0|1] ""  JiaShiCang
 SG_ R_DuanLuQi_Sta_17 : 16|1@1+ (1,0) [0|1] ""  JiaShiCang
 SG_ R_DuanLuQi_Sta_16 : 15|1@1+ (1,0) [0|1] ""  JiaShiCang
 SG_ R_DuanLuQi_Sta_15 : 14|1@1+ (1,0) [0|1] ""  JiaShiCang
 SG_ R_DuanLuQi_Sta_14 : 13|1@1+ (1,0) [0|1] ""  JiaShiCang
 SG_ R_DuanLuQi_Sta_13 : 12|1@1+ (1,0) [0|1] ""  JiaShiCang
 SG_ R_DuanLuQi_Sta_12 : 11|1@1+ (1,0) [0|1] ""  JiaShiCang
 SG_ R_DuanLuQi_Sta_11 : 10|1@1+ (1,0) [0|1] ""  JiaShiCang
 SG_ R_DuanLuQi_Sta_10 : 9|1@1+ (1,0) [0|1] ""  JiaShiCang
 SG_ R_DuanLuQi_Sta_09 : 8|1@1+ (1,0) [0|1] ""  JiaShiCang
 SG_ R_DuanLuQi_Sta_08 : 7|1@1+ (1,0) [0|1] ""  JiaShiCang
 SG_ R_DuanLuQi_Sta_07 : 6|1@1+ (1,0) [0|1] ""  JiaShiCang
 SG_ R_DuanLuQi_Sta_06 : 5|1@1+ (1,0) [0|1] ""  JiaShiCang
 SG_ R_DuanLuQi_Sta_05 : 4|1@1+ (1,0) [0|1] ""  JiaShiCang
 SG_ R_DuanLuQi_Sta_04 : 3|1@1+ (1,0) [0|1] ""  JiaShiCang
 SG_ R_DuanLuQi_Sta_03 : 2|1@1+ (1,0) [0|1] ""  JiaShiCang
 SG_ R_DuanLuQi_Sta_02 : 1|1@1+ (1,0) [0|1] ""  JiaShiCang
 SG_ R_DuanLuQi_Sta_01 : 0|1@1+ (1,0) [0|1] ""  JiaShiCang

BO_ 2416443424 Msg_R_BIT_Msg: 8 R_BPCU_MCU
 SG_ BackUp242 : 39|1@1+ (1,0) [0|0] ""  JiaShiCang
 SG_ R_RE28IOver : 38|1@1+ (1,0) [0|1] ""  JiaShiCang
 SG_ R_RL28IOver : 37|1@1+ (1,0) [0|1] ""  JiaShiCang
 SG_ R_HLT281IOver : 36|1@1+ (1,0) [0|1] ""  JiaShiCang
 SG_ R_HLT282IOver : 35|1@1+ (1,0) [0|1] ""  JiaShiCang
 SG_ R_RE270IOver : 34|1@1+ (1,0) [0|1] ""  JiaShiCang
 SG_ BackUp241 : 33|1@1+ (1,0) [0|0] ""  JiaShiCang
 SG_ R_HLT270IOver : 32|1@1+ (1,0) [0|1] ""  JiaShiCang
 SG_ BackUp240 : 30|2@1+ (1,0) [0|0] ""  JiaShiCang
 SG_ R_HOTBBUSta : 28|2@1+ (1,0) [0|3] ""  JiaShiCang
 SG_ R_HLT281USta : 26|2@1+ (1,0) [0|3] ""  JiaShiCang
 SG_ R_HLT282USta : 24|2@1+ (1,0) [0|3] ""  JiaShiCang
 SG_ R_DCDC28OutUSta : 22|2@1+ (1,0) [0|3] ""  JiaShiCang
 SG_ R_DCDC270InUSta : 20|2@1+ (1,0) [0|3] ""  JiaShiCang
 SG_ R_HLT270USta : 18|2@1+ (1,0) [0|3] ""  JiaShiCang
 SG_ R_Batter270USta : 16|2@1+ (1,0) [0|3] ""  JiaShiCang
 SG_ BackUp239 : 11|5@1+ (1,0) [0|0] ""  JiaShiCang
 SG_ R_Heart_BIT : 10|1@1+ (1,0) [0|1] ""  JiaShiCang
 SG_ R_ZBUART_BIT : 9|1@1+ (1,0) [0|1] ""  JiaShiCang
 SG_ R_ADCIN_BIT : 8|1@1+ (1,0) [0|1] ""  JiaShiCang
 SG_ R_GpioIN_BIT : 7|1@1+ (1,0) [0|1] ""  JiaShiCang
 SG_ R_Flash_BIT : 6|1@1+ (1,0) [0|1] ""  JiaShiCang
 SG_ R_UART_BIT : 5|1@1+ (1,0) [0|1] ""  JiaShiCang
 SG_ R_IntCAN2_BIT : 4|1@1+ (1,0) [0|1] ""  JiaShiCang
 SG_ R_IntCAN1_BIT : 3|1@1+ (1,0) [0|1] ""  JiaShiCang
 SG_ R_ExtCAN_BIT : 2|1@1+ (1,0) [0|1] ""  JiaShiCang
 SG_ R_CPU_BIT : 1|1@1+ (1,0) [0|1] ""  JiaShiCang
 SG_ R_Pow_BIT : 0|1@1+ (1,0) [0|1] ""  JiaShiCang

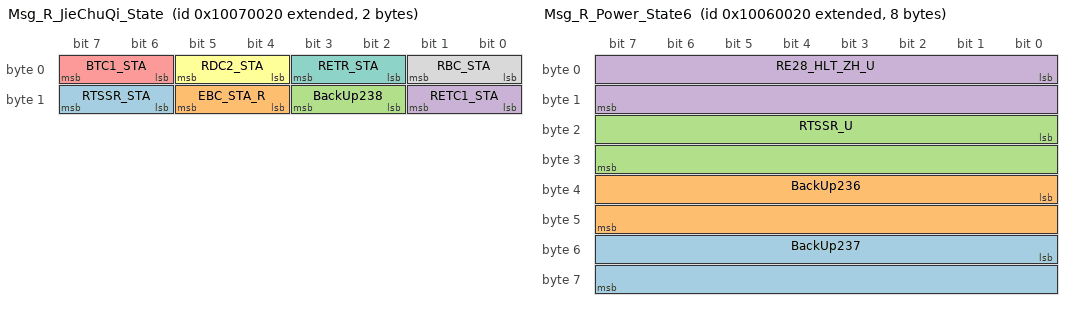
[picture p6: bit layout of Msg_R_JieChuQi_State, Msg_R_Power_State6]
BO_ 2416377888 Msg_R_JieChuQi_State: 2 R_BPCU_MCU
 SG_ RTSSR_STA : 14|2@1+ (1,0) [0|3] ""  JiaShiCang
 SG_ EBC_STA_R : 12|2@1+ (1,0) [0|3] ""  JiaShiCang
 SG_ BackUp238 : 10|2@1+ (1,0) [0|0] ""  JiaShiCang
 SG_ RETC1_STA : 8|2@1+ (1,0) [0|3] ""  JiaShiCang
 SG_ BTC1_STA : 6|2@1+ (1,0) [0|3] ""  JiaShiCang
 SG_ RDC2_STA : 4|2@1+ (1,0) [0|3] ""  JiaShiCang
 SG_ RETR_STA : 2|2@1+ (1,0) [0|3] ""  JiaShiCang
 SG_ RBC_STA : 0|2@1+ (1,0) [0|3] ""  JiaShiCang

BO_ 2416312352 Msg_R_Power_State6: 8 R_BPCU_MCU
 SG_ BackUp237 : 48|16@1+ (1,0) [0|0] ""  JiaShiCang
 SG_ BackUp236 : 32|16@1+ (1,0) [0|0] ""  JiaShiCang
 SG_ RTSSR_U : 16|16@1+ (0.1,0) [0|6553.5] "V"  JiaShiCang
 SG_ RE28_HLT_ZH_U : 0|16@1+ (0.1,0) [0|6553.5] "V"  JiaShiCang

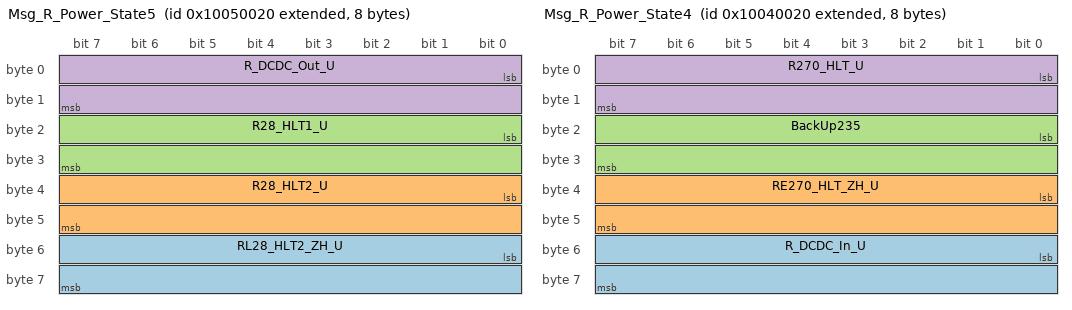
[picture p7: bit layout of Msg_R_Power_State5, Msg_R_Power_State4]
BO_ 2416246816 Msg_R_Power_State5: 8 R_BPCU_MCU
 SG_ RL28_HLT2_ZH_U : 48|16@1+ (0.1,0) [0|6553.5] "V"  JiaShiCang
 SG_ R28_HLT2_U : 32|16@1+ (0.1,0) [0|6553.5] "V"  JiaShiCang
 SG_ R28_HLT1_U : 16|16@1+ (0.1,0) [0|6553.5] "V"  JiaShiCang
 SG_ R_DCDC_Out_U : 0|16@1+ (0.1,0) [0|6553.5] "V"  JiaShiCang

BO_ 2416181280 Msg_R_Power_State4: 8 R_BPCU_MCU
 SG_ R_DCDC_In_U : 48|16@1+ (0.1,0) [0|6553.5] "V"  JiaShiCang
 SG_ RE270_HLT_ZH_U : 32|16@1+ (0.1,0) [0|6553.5] "V"  JiaShiCang
 SG_ BackUp235 : 16|16@1+ (1,0) [0|0] ""  JiaShiCang
 SG_ R270_HLT_U : 0|16@1+ (0.1,0) [0|6553.5] "V"  JiaShiCang

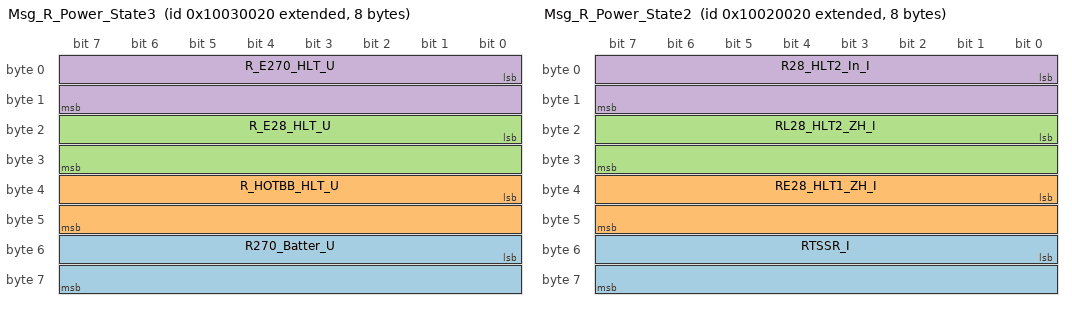
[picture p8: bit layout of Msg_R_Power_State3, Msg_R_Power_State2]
BO_ 2416115744 Msg_R_Power_State3: 8 R_BPCU_MCU
 SG_ R270_Batter_U : 48|16@1+ (0.1,0) [0|6553.5] "V"  JiaShiCang
 SG_ R_HOTBB_HLT_U : 32|16@1+ (0.1,0) [0|6553.5] "V"  JiaShiCang
 SG_ R_E28_HLT_U : 16|16@1+ (0.1,0) [0|6553.5] "V"  JiaShiCang
 SG_ R_E270_HLT_U : 0|16@1+ (0.1,0) [0|6553.5] "V"  JiaShiCang

BO_ 2416050208 Msg_R_Power_State2: 8 R_BPCU_MCU
 SG_ RTSSR_I : 48|16@1+ (0.1,0) [0|6553.5] "A"  JiaShiCang
 SG_ RE28_HLT1_ZH_I : 32|16@1+ (0.1,0) [0|6553.5] "A"  JiaShiCang
 SG_ RL28_HLT2_ZH_I : 16|16@1+ (0.1,0) [0|6553.5] "A"  JiaShiCang
 SG_ R28_HLT2_In_I : 0|16@1+ (0.1,0) [0|6553.5] "A"  JiaShiCang

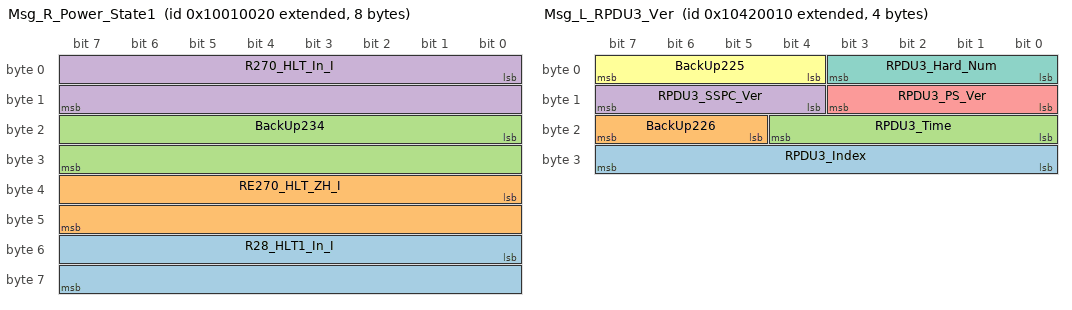
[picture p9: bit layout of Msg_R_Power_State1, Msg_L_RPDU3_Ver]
BO_ 2415984672 Msg_R_Power_State1: 8 R_BPCU_MCU
 SG_ R28_HLT1_In_I : 48|16@1+ (0.1,0) [0|6553.5] "A"  JiaShiCang
 SG_ RE270_HLT_ZH_I : 32|16@1+ (0.1,0) [0|6553.5] "A"  JiaShiCang
 SG_ BackUp234 : 16|16@1+ (1,0) [0|0] ""  JiaShiCang
 SG_ R270_HLT_In_I : 0|16@1+ (0.1,0) [0|6553.5] "A"  JiaShiCang

BO_ 2421178384 Msg_L_ChongGou_JiaoHu: 8 L_BPCU_MCU
 SG_ BackUp233 : 56|8@1+ (1,0) [0|0] ""  R_BPCU_MCU,EMPC_ECU
 SG_ BackUp232 : 48|8@1+ (1,0) [0|0] ""  R_BPCU_MCU,EMPC_ECU
 SG_ BackUp231 : 32|16@1+ (1,0) [0|0] ""  R_BPCU_MCU,EMPC_ECU
 SG_ BackUp230 : 24|8@1+ (1,0) [0|0] ""  R_BPCU_MCU,EMPC_ECU
 SG_ LETC1_Ctrl : 23|1@1+ (1,0) [0|1] ""  R_BPCU_MCU,EMPC_ECU
 SG_ LETR_Ctrl : 22|1@1+ (1,0) [0|1] ""  R_BPCU_MCU,EMPC_ECU
 SG_ LETR_STA_ChongGou : 20|2@1+ (1,0) [0|3] ""  R_BPCU_MCU,EMPC_ECU
 SG_ LETC1_ChongGou_ChangJing : 18|2@1+ (1,0) [0|3] ""  R_BPCU_MCU,EMPC_ECU
 SG_ LETC1_STA_ChongGou : 16|2@1+ (1,0) [0|3] ""  R_BPCU_MCU,EMPC_ECU
 SG_ BTC2_STA_ChongGou : 14|2@1+ (1,0) [0|3] ""  R_BPCU_MCU,EMPC_ECU
 SG_ BackUp229 : 13|1@1+ (1,0) [0|0] ""  R_BPCU_MCU,EMPC_ECU
 SG_ BTC2_ReSta : 12|1@1+ (1,0) [0|1] ""  R_BPCU_MCU,EMPC_ECU
 SG_ BackUp228 : 11|1@1+ (1,0) [0|0] ""  R_BPCU_MCU,EMPC_ECU
 SG_ LTR_Ctrl : 10|1@1+ (1,0) [0|1] ""  R_BPCU_MCU,EMPC_ECU
 SG_ LDC2_Ctrl : 9|1@1+ (1,0) [0|1] ""  R_BPCU_MCU,EMPC_ECU
 SG_ LDC1_Ctrl : 8|1@1+ (1,0) [0|1] ""  R_BPCU_MCU,EMPC_ECU
 SG_ BTC2_ChongGou_ChangJing : 6|2@1+ (1,0) [0|3] ""  R_BPCU_MCU,EMPC_ECU
 SG_ BackUp227 : 4|2@1+ (1,0) [0|0] ""  R_BPCU_MCU,EMPC_ECU
 SG_ LETC1_ReSta : 3|1@1+ (1,0) [0|1] ""  R_BPCU_MCU,EMPC_ECU
 SG_ L_HLT282IOver_ChongGou : 2|1@1+ (1,0) [0|1] ""  R_BPCU_MCU,EMPC_ECU
 SG_ L_HLT281IOver_ChongGou : 1|1@1+ (1,0) [0|1] ""  R_BPCU_MCU,EMPC_ECU
 SG_ L_HLT270IOver_ChongGou : 0|1@1+ (1,0) [0|1] ""  R_BPCU_MCU,EMPC_ECU

BO_ 2420244496 Msg_L_RPDU3_Ver: 4 L_BPCU_MCU
 SG_ RPDU3_Index : 24|8@1+ (1,0) [0|255] ""  JiaShiCang
 SG_ BackUp226 : 21|3@1+ (1,0) [0|0] ""  JiaShiCang
 SG_ RPDU3_Time : 16|5@1+ (1,0) [0|31] ""  JiaShiCang
 SG_ RPDU3_SSPC_Ver : 12|4@1+ (1,0) [0|15] ""  JiaShiCang
 SG_ RPDU3_PS_Ver : 8|4@1+ (1,0) [0|15] ""  JiaShiCang
 SG_ BackUp225 : 4|4@1+ (1,0) [0|0] ""  JiaShiCang
 SG_ RPDU3_Hard_Num : 0|4@1+ (1,0) [0|15] ""  JiaShiCang

BO_ 2420178960 Msg_L_RPDU3_B6_SSPC05_07: 8 L_BPCU_MCU
 SG_ BackUp224 : 56|8@1+ (1,0) [0|0] ""  JiaShiCang
 SG_ BackUp223 : 48|8@1+ (1,0) [0|0] ""  JiaShiCang
 SG_ RPDU3_B6_SSPC_I_Load_07 : 40|8@1+ (0.1,0) [0|25.5] "A"  JiaShiCang
 SG_ RPDU3_B6_SSPC_TripSta_07 : 38|2@1+ (1,0) [0|3] ""  JiaShiCang
 SG_ RPDU3_B6_SSPC_BitErr_07 : 37|1@1+ (1,0) [0|1] ""  JiaShiCang
 SG_ RPDU3_B6_SSPC_OnOffSta_07 : 36|1@1+ (1,0) [0|1] ""  JiaShiCang
 SG_ RPDU3_B6_SSPC_DianHuErr_07 : 35|1@1+ (1,0) [0|1] ""  JiaShiCang
 SG_ BackUp222 : 32|3@1+ (1,0) [0|0] ""  JiaShiCang
 SG_ RPDU3_B6_SSPC_I_Load_06 : 24|8@1+ (0.1,0) [0|25.5] "A"  JiaShiCang
 SG_ RPDU3_B6_SSPC_TripSta_06 : 22|2@1+ (1,0) [0|3] ""  JiaShiCang
 SG_ RPDU3_B6_SSPC_BitErr_06 : 21|1@1+ (1,0) [0|1] ""  JiaShiCang
 SG_ RPDU3_B6_SSPC_OnOffSta_06 : 20|1@1+ (1,0) [0|1] ""  JiaShiCang
 SG_ RPDU3_B6_SSPC_DianHuErr_06 : 19|1@1+ (1,0) [0|1] ""  JiaShiCang
 SG_ BackUp221 : 16|3@1+ (1,0) [0|0] ""  JiaShiCang
 SG_ RPDU3_B6_SSPC_I_Load_05 : 8|8@1+ (0.1,0) [0|25.5] "A"  JiaShiCang
 SG_ RPDU3_B6_SSPC_TripSta_05 : 6|2@1+ (1,0) [0|3] ""  JiaShiCang
 SG_ RPDU3_B6_SSPC_BitErr_05 : 5|1@1+ (1,0) [0|1] ""  JiaShiCang
 SG_ RPDU3_B6_SSPC_OnOffSta_05 : 4|1@1+ (1,0) [0|1] ""  JiaShiCang
 SG_ RPDU3_B6_SSPC_DianHuErr_05 : 3|1@1+ (1,0) [0|1] ""  JiaShiCang
 SG_ BackUp220 : 0|3@1+ (1,0) [0|0] ""  JiaShiCang

BO_ 2420113424 Msg_L_RPDU3_B6_SSPC01_04: 8 L_BPCU_MCU
 SG_ RPDU3_B6_SSPC_I_Load_04 : 56|8@1+ (0.1,0) [0|25.5] "A"  JiaShiCang
 SG_ RPDU3_B6_SSPC_TripSta_04 : 54|2@1+ (1,0) [0|3] ""  JiaShiCang
 SG_ RPDU3_B6_SSPC_BitErr_04 : 53|1@1+ (1,0) [0|1] ""  JiaShiCang
 SG_ RPDU3_B6_SSPC_OnOffSta_04 : 52|1@1+ (1,0) [0|1] ""  JiaShiCang
 SG_ RPDU3_B6_SSPC_DianHuErr_04 : 51|1@1+ (1,0) [0|1] ""  JiaShiCang
 SG_ BackUp219 : 48|3@1+ (1,0) [0|0] ""  JiaShiCang
 SG_ RPDU3_B6_SSPC_I_Load_03 : 40|8@1+ (0.1,0) [0|25.5] "A"  JiaShiCang
 SG_ RPDU3_B6_SSPC_TripSta_03 : 38|2@1+ (1,0) [0|3] ""  JiaShiCang
 SG_ RPDU3_B6_SSPC_BitErr_03 : 37|1@1+ (1,0) [0|1] ""  JiaShiCang
 SG_ RPDU3_B6_SSPC_OnOffSta_03 : 36|1@1+ (1,0) [0|1] ""  JiaShiCang
 SG_ RPDU3_B6_SSPC_DianHuErr_03 : 35|1@1+ (1,0) [0|1] ""  JiaShiCang
 SG_ BackUp218 : 32|3@1+ (1,0) [0|0] ""  JiaShiCang
 SG_ RPDU3_B6_SSPC_I_Load_02 : 24|8@1+ (0.1,0) [0|25.5] "A"  JiaShiCang
 SG_ RPDU3_B6_SSPC_TripSta_02 : 22|2@1+ (1,0) [0|3] ""  JiaShiCang
 SG_ RPDU3_B6_SSPC_BitErr_02 : 21|1@1+ (1,0) [0|1] ""  JiaShiCang
 SG_ RPDU3_B6_SSPC_OnOffSta_02 : 20|1@1+ (1,0) [0|1] ""  JiaShiCang
 SG_ RPDU3_B6_SSPC_DianHuErr_02 : 19|1@1+ (1,0) [0|1] ""  JiaShiCang
 SG_ BackUp217 : 16|3@1+ (1,0) [0|0] ""  JiaShiCang
 SG_ RPDU3_B6_SSPC_I_Load_01 : 8|8@1+ (0.1,0) [0|25.5] "A"  JiaShiCang
 SG_ RPDU3_B6_SSPC_TripSta_01 : 6|2@1+ (1,0) [0|3] ""  JiaShiCang
 SG_ RPDU3_B6_SSPC_BitErr_01 : 5|1@1+ (1,0) [0|1] ""  JiaShiCang
 SG_ RPDU3_B6_SSPC_OnOffSta_01 : 4|1@1+ (1,0) [0|1] ""  JiaShiCang
 SG_ RPDU3_B6_SSPC_DianHuErr_01 : 3|1@1+ (1,0) [0|1] ""  JiaShiCang
 SG_ BackUp216 : 0|3@1+ (1,0) [0|0] ""  JiaShiCang

BO_ 2420047888 Msg_L_RPDU3_B5_SSPC05_07: 8 L_BPCU_MCU
 SG_ BackUp215 : 56|8@1+ (1,0) [0|0] ""  JiaShiCang
 SG_ BackUp214 : 48|8@1+ (1,0) [0|0] ""  JiaShiCang
 SG_ RPDU3_B5_SSPC_I_Load_07 : 40|8@1+ (0.1,0) [0|25.5] "A"  JiaShiCang
 SG_ RPDU3_B5_SSPC_TripSta_07 : 38|2@1+ (1,0) [0|3] ""  JiaShiCang
 SG_ RPDU3_B5_SSPC_BitErr_07 : 37|1@1+ (1,0) [0|1] ""  JiaShiCang
 SG_ RPDU3_B5_SSPC_OnOffSta_07 : 36|1@1+ (1,0) [0|1] ""  JiaShiCang
 SG_ RPDU3_B5_SSPC_DianHuErr_07 : 35|1@1+ (1,0) [0|1] ""  JiaShiCang
 SG_ BackUp213 : 32|3@1+ (1,0) [0|0] ""  JiaShiCang
 SG_ RPDU3_B5_SSPC_I_Load_06 : 24|8@1+ (0.1,0) [0|25.5] "A"  JiaShiCang
 SG_ RPDU3_B5_SSPC_TripSta_06 : 22|2@1+ (1,0) [0|3] ""  JiaShiCang
 SG_ RPDU3_B5_SSPC_BitErr_06 : 21|1@1+ (1,0) [0|1] ""  JiaShiCang
 SG_ RPDU3_B5_SSPC_OnOffSta_06 : 20|1@1+ (1,0) [0|1] ""  JiaShiCang
 SG_ RPDU3_B5_SSPC_DianHuErr_06 : 19|1@1+ (1,0) [0|1] ""  JiaShiCang
 SG_ BackUp212 : 16|3@1+ (1,0) [0|0] ""  JiaShiCang
 SG_ RPDU3_B5_SSPC_I_Load_05 : 8|8@1+ (0.1,0) [0|25.5] "A"  JiaShiCang
 SG_ RPDU3_B5_SSPC_TripSta_05 : 6|2@1+ (1,0) [0|3] ""  JiaShiCang
 SG_ RPDU3_B5_SSPC_BitErr_05 : 5|1@1+ (1,0) [0|1] ""  JiaShiCang
 SG_ RPDU3_B5_SSPC_OnOffSta_05 : 4|1@1+ (1,0) [0|1] ""  JiaShiCang
 SG_ RPDU3_B5_SSPC_DianHuErr_05 : 3|1@1+ (1,0) [0|1] ""  JiaShiCang
 SG_ BackUp211 : 0|3@1+ (1,0) [0|0] ""  JiaShiCang

BO_ 2419982352 Msg_L_RPDU3_B5_SSPC01_04: 8 L_BPCU_MCU
 SG_ RPDU3_B5_SSPC_I_Load_04 : 56|8@1+ (0.1,0) [0|25.5] "A"  JiaShiCang
 SG_ RPDU3_B5_SSPC_TripSta_04 : 54|2@1+ (1,0) [0|3] ""  JiaShiCang
 SG_ RPDU3_B5_SSPC_BitErr_04 : 53|1@1+ (1,0) [0|1] ""  JiaShiCang
 SG_ RPDU3_B5_SSPC_OnOffSta_04 : 52|1@1+ (1,0) [0|1] ""  JiaShiCang
 SG_ RPDU3_B5_SSPC_DianHuErr_04 : 51|1@1+ (1,0) [0|1] ""  JiaShiCang
 SG_ BackUp210 : 48|3@1+ (1,0) [0|0] ""  JiaShiCang
 SG_ RPDU3_B5_SSPC_I_Load_03 : 40|8@1+ (0.1,0) [0|25.5] "A"  JiaShiCang
 SG_ RPDU3_B5_SSPC_TripSta_03 : 38|2@1+ (1,0) [0|3] ""  JiaShiCang
 SG_ RPDU3_B5_SSPC_BitErr_03 : 37|1@1+ (1,0) [0|1] ""  JiaShiCang
 SG_ RPDU3_B5_SSPC_OnOffSta_03 : 36|1@1+ (1,0) [0|1] ""  JiaShiCang
 SG_ RPDU3_B5_SSPC_DianHuErr_03 : 35|1@1+ (1,0) [0|1] ""  JiaShiCang
 SG_ BackUp209 : 32|3@1+ (1,0) [0|0] ""  JiaShiCang
 SG_ RPDU3_B5_SSPC_I_Load_02 : 24|8@1+ (0.1,0) [0|25.5] "A"  JiaShiCang
 SG_ RPDU3_B5_SSPC_TripSta_02 : 22|2@1+ (1,0) [0|3] ""  JiaShiCang
 SG_ RPDU3_B5_SSPC_BitErr_02 : 21|1@1+ (1,0) [0|1] ""  JiaShiCang
 SG_ RPDU3_B5_SSPC_OnOffSta_02 : 20|1@1+ (1,0) [0|1] ""  JiaShiCang
 SG_ RPDU3_B5_SSPC_DianHuErr_02 : 19|1@1+ (1,0) [0|1] ""  JiaShiCang
 SG_ BackUp208 : 16|3@1+ (1,0) [0|0] ""  JiaShiCang
 SG_ RPDU3_B5_SSPC_I_Load_01 : 8|8@1+ (0.1,0) [0|25.5] "A"  JiaShiCang
 SG_ RPDU3_B5_SSPC_TripSta_01 : 6|2@1+ (1,0) [0|3] ""  JiaShiCang
 SG_ RPDU3_B5_SSPC_BitErr_01 : 5|1@1+ (1,0) [0|1] ""  JiaShiCang
 SG_ RPDU3_B5_SSPC_OnOffSta_01 : 4|1@1+ (1,0) [0|1] ""  JiaShiCang
 SG_ RPDU3_B5_SSPC_DianHuErr_01 : 3|1@1+ (1,0) [0|1] ""  JiaShiCang
 SG_ BackUp207 : 0|3@1+ (1,0) [0|0] ""  JiaShiCang

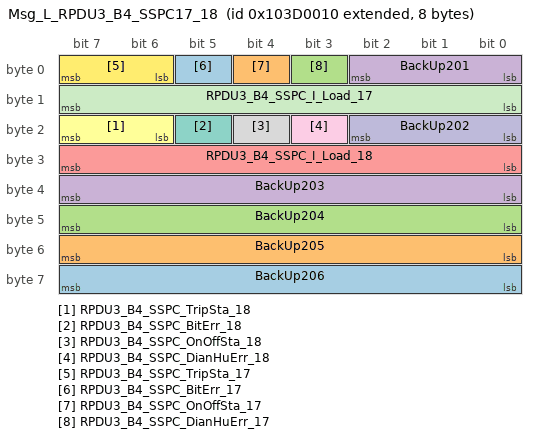
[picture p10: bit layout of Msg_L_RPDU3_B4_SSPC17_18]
BO_ 2419916816 Msg_L_RPDU3_B4_SSPC17_18: 8 L_BPCU_MCU
 SG_ BackUp206 : 56|8@1+ (1,0) [0|0] ""  JiaShiCang
 SG_ BackUp205 : 48|8@1+ (1,0) [0|0] ""  JiaShiCang
 SG_ BackUp204 : 40|8@1+ (1,0) [0|0] ""  JiaShiCang
 SG_ BackUp203 : 32|8@1+ (1,0) [0|0] ""  JiaShiCang
 SG_ RPDU3_B4_SSPC_I_Load_18 : 24|8@1+ (0.1,0) [0|25.5] "A"  JiaShiCang
 SG_ RPDU3_B4_SSPC_TripSta_18 : 22|2@1+ (1,0) [0|3] ""  JiaShiCang
 SG_ RPDU3_B4_SSPC_BitErr_18 : 21|1@1+ (1,0) [0|1] ""  JiaShiCang
 SG_ RPDU3_B4_SSPC_OnOffSta_18 : 20|1@1+ (1,0) [0|1] ""  JiaShiCang
 SG_ RPDU3_B4_SSPC_DianHuErr_18 : 19|1@1+ (1,0) [0|1] ""  JiaShiCang
 SG_ BackUp202 : 16|3@1+ (1,0) [0|0] ""  JiaShiCang
 SG_ RPDU3_B4_SSPC_I_Load_17 : 8|8@1+ (0.1,0) [0|25.5] "A"  JiaShiCang
 SG_ RPDU3_B4_SSPC_TripSta_17 : 6|2@1+ (1,0) [0|3] ""  JiaShiCang
 SG_ RPDU3_B4_SSPC_BitErr_17 : 5|1@1+ (1,0) [0|1] ""  JiaShiCang
 SG_ RPDU3_B4_SSPC_OnOffSta_17 : 4|1@1+ (1,0) [0|1] ""  JiaShiCang
 SG_ RPDU3_B4_SSPC_DianHuErr_17 : 3|1@1+ (1,0) [0|1] ""  JiaShiCang
 SG_ BackUp201 : 0|3@1+ (1,0) [0|0] ""  JiaShiCang

BO_ 2419851280 Msg_L_RPDU3_B4_SSPC13_16: 8 L_BPCU_MCU
 SG_ RPDU3_B4_SSPC_I_Load_16 : 56|8@1+ (0.1,0) [0|25.5] "A"  JiaShiCang
 SG_ RPDU3_B4_SSPC_TripSta_16 : 54|2@1+ (1,0) [0|3] ""  JiaShiCang
 SG_ RPDU3_B4_SSPC_BitErr_16 : 53|1@1+ (1,0) [0|1] ""  JiaShiCang
 SG_ RPDU3_B4_SSPC_OnOffSta_16 : 52|1@1+ (1,0) [0|1] ""  JiaShiCang
 SG_ RPDU3_B4_SSPC_DianHuErr_16 : 51|1@1+ (1,0) [0|1] ""  JiaShiCang
 SG_ BackUp200 : 48|3@1+ (1,0) [0|0] ""  JiaShiCang
 SG_ RPDU3_B4_SSPC_I_Load_15 : 40|8@1+ (0.1,0) [0|25.5] "A"  JiaShiCang
 SG_ RPDU3_B4_SSPC_TripSta_15 : 38|2@1+ (1,0) [0|3] ""  JiaShiCang
 SG_ RPDU3_B4_SSPC_BitErr_15 : 37|1@1+ (1,0) [0|1] ""  JiaShiCang
 SG_ RPDU3_B4_SSPC_OnOffSta_15 : 36|1@1+ (1,0) [0|1] ""  JiaShiCang
 SG_ RPDU3_B4_SSPC_DianHuErr_15 : 35|1@1+ (1,0) [0|1] ""  JiaShiCang
 SG_ BackUp199 : 32|3@1+ (1,0) [0|0] ""  JiaShiCang
 SG_ RPDU3_B4_SSPC_I_Load_14 : 24|8@1+ (0.1,0) [0|25.5] "A"  JiaShiCang
 SG_ RPDU3_B4_SSPC_TripSta_14 : 22|2@1+ (1,0) [0|3] ""  JiaShiCang
 SG_ RPDU3_B4_SSPC_BitErr_14 : 21|1@1+ (1,0) [0|1] ""  JiaShiCang
 SG_ RPDU3_B4_SSPC_OnOffSta_14 : 20|1@1+ (1,0) [0|1] ""  JiaShiCang
 SG_ RPDU3_B4_SSPC_DianHuErr_14 : 19|1@1+ (1,0) [0|1] ""  JiaShiCang
 SG_ BackUp198 : 16|3@1+ (1,0) [0|0] ""  JiaShiCang
 SG_ RPDU3_B4_SSPC_I_Load_13 : 8|8@1+ (0.1,0) [0|25.5] "A"  JiaShiCang
 SG_ RPDU3_B4_SSPC_TripSta_13 : 6|2@1+ (1,0) [0|3] ""  JiaShiCang
 SG_ RPDU3_B4_SSPC_BitErr_13 : 5|1@1+ (1,0) [0|1] ""  JiaShiCang
 SG_ RPDU3_B4_SSPC_OnOffSta_13 : 4|1@1+ (1,0) [0|1] ""  JiaShiCang
 SG_ RPDU3_B4_SSPC_DianHuErr_13 : 3|1@1+ (1,0) [0|1] ""  JiaShiCang
 SG_ BackUp197 : 0|3@1+ (1,0) [0|0] ""  JiaShiCang

BO_ 2419785744 Msg_L_RPDU3_B4_SSPC09_12: 8 L_BPCU_MCU
 SG_ RPDU3_B4_SSPC_I_Load_12 : 56|8@1+ (0.1,0) [0|25.5] "A"  JiaShiCang
 SG_ RPDU3_B4_SSPC_TripSta_12 : 54|2@1+ (1,0) [0|3] ""  JiaShiCang
 SG_ RPDU3_B4_SSPC_BitErr_12 : 53|1@1+ (1,0) [0|1] ""  JiaShiCang
 SG_ RPDU3_B4_SSPC_OnOffSta_12 : 52|1@1+ (1,0) [0|1] ""  JiaShiCang
 SG_ RPDU3_B4_SSPC_DianHuErr_12 : 51|1@1+ (1,0) [0|1] ""  JiaShiCang
 SG_ BackUp196 : 48|3@1+ (1,0) [0|0] ""  JiaShiCang
 SG_ RPDU3_B4_SSPC_I_Load_11 : 40|8@1+ (0.1,0) [0|25.5] "A"  JiaShiCang
 SG_ RPDU3_B4_SSPC_TripSta_11 : 38|2@1+ (1,0) [0|3] ""  JiaShiCang
 SG_ RPDU3_B4_SSPC_BitErr_11 : 37|1@1+ (1,0) [0|1] ""  JiaShiCang
 SG_ RPDU3_B4_SSPC_OnOffSta_11 : 36|1@1+ (1,0) [0|1] ""  JiaShiCang
 SG_ RPDU3_B4_SSPC_DianHuErr_11 : 35|1@1+ (1,0) [0|1] ""  JiaShiCang
 SG_ BackUp195 : 32|3@1+ (1,0) [0|0] ""  JiaShiCang
 SG_ RPDU3_B4_SSPC_I_Load_10 : 24|8@1+ (0.1,0) [0|25.5] "A"  JiaShiCang
 SG_ RPDU3_B4_SSPC_TripSta_10 : 22|2@1+ (1,0) [0|3] ""  JiaShiCang
 SG_ RPDU3_B4_SSPC_BitErr_10 : 21|1@1+ (1,0) [0|1] ""  JiaShiCang
 SG_ RPDU3_B4_SSPC_OnOffSta_10 : 20|1@1+ (1,0) [0|1] ""  JiaShiCang
 SG_ RPDU3_B4_SSPC_DianHuErr_10 : 19|1@1+ (1,0) [0|1] ""  JiaShiCang
 SG_ BackUp194 : 16|3@1+ (1,0) [0|0] ""  JiaShiCang
 SG_ RPDU3_B4_SSPC_I_Load_09 : 8|8@1+ (0.1,0) [0|25.5] "A"  JiaShiCang
 SG_ RPDU3_B4_SSPC_TripSta_09 : 6|2@1+ (1,0) [0|3] ""  JiaShiCang
 SG_ RPDU3_B4_SSPC_BitErr_09 : 5|1@1+ (1,0) [0|1] ""  JiaShiCang
 SG_ RPDU3_B4_SSPC_OnOffSta_09 : 4|1@1+ (1,0) [0|1] ""  JiaShiCang
 SG_ RPDU3_B4_SSPC_DianHuErr_09 : 3|1@1+ (1,0) [0|1] ""  JiaShiCang
 SG_ BackUp193 : 0|3@1+ (1,0) [0|0] ""  JiaShiCang

BO_ 2419720208 Msg_L_RPDU3_B4_SSPC05_08: 8 L_BPCU_MCU
 SG_ RPDU3_B4_SSPC_I_Load_08 : 56|8@1+ (0.1,0) [0|25.5] "A"  JiaShiCang
 SG_ RPDU3_B4_SSPC_TripSta_08 : 54|2@1+ (1,0) [0|3] ""  JiaShiCang
 SG_ RPDU3_B4_SSPC_BitErr_08 : 53|1@1+ (1,0) [0|1] ""  JiaShiCang
 SG_ RPDU3_B4_SSPC_OnOffSta_08 : 52|1@1+ (1,0) [0|1] ""  JiaShiCang
 SG_ RPDU3_B4_SSPC_DianHuErr_08 : 51|1@1+ (1,0) [0|1] ""  JiaShiCang
 SG_ BackUp192 : 48|3@1+ (1,0) [0|0] ""  JiaShiCang
 SG_ RPDU3_B4_SSPC_I_Load_07 : 40|8@1+ (0.1,0) [0|25.5] "A"  JiaShiCang
 SG_ RPDU3_B4_SSPC_TripSta_07 : 38|2@1+ (1,0) [0|3] ""  JiaShiCang
 SG_ RPDU3_B4_SSPC_BitErr_07 : 37|1@1+ (1,0) [0|1] ""  JiaShiCang
 SG_ RPDU3_B4_SSPC_OnOffSta_07 : 36|1@1+ (1,0) [0|1] ""  JiaShiCang
 SG_ RPDU3_B4_SSPC_DianHuErr_07 : 35|1@1+ (1,0) [0|1] ""  JiaShiCang
 SG_ BackUp191 : 32|3@1+ (1,0) [0|0] ""  JiaShiCang
 SG_ RPDU3_B4_SSPC_I_Load_06 : 24|8@1+ (0.1,0) [0|25.5] "A"  JiaShiCang
 SG_ RPDU3_B4_SSPC_TripSta_06 : 22|2@1+ (1,0) [0|3] ""  JiaShiCang
 SG_ RPDU3_B4_SSPC_BitErr_06 : 21|1@1+ (1,0) [0|1] ""  JiaShiCang
 SG_ RPDU3_B4_SSPC_OnOffSta_06 : 20|1@1+ (1,0) [0|1] ""  JiaShiCang
 SG_ RPDU3_B4_SSPC_DianHuErr_06 : 19|1@1+ (1,0) [0|1] ""  JiaShiCang
 SG_ BackUp190 : 16|3@1+ (1,0) [0|0] ""  JiaShiCang
 SG_ RPDU3_B4_SSPC_I_Load_05 : 8|8@1+ (0.1,0) [0|25.5] "A"  JiaShiCang
 SG_ RPDU3_B4_SSPC_TripSta_05 : 6|2@1+ (1,0) [0|3] ""  JiaShiCang
 SG_ RPDU3_B4_SSPC_BitErr_05 : 5|1@1+ (1,0) [0|1] ""  JiaShiCang
 SG_ RPDU3_B4_SSPC_OnOffSta_05 : 4|1@1+ (1,0) [0|1] ""  JiaShiCang
 SG_ RPDU3_B4_SSPC_DianHuErr_05 : 3|1@1+ (1,0) [0|1] ""  JiaShiCang
 SG_ BackUp189 : 0|3@1+ (1,0) [0|0] ""  JiaShiCang

BO_ 2419654672 Msg_L_RPDU3_B4_SSPC01_04: 8 L_BPCU_MCU
 SG_ RPDU3_B4_SSPC_I_Load_04 : 56|8@1+ (0.1,0) [0|25.5] "A"  JiaShiCang
 SG_ RPDU3_B4_SSPC_TripSta_04 : 54|2@1+ (1,0) [0|3] ""  JiaShiCang
 SG_ RPDU3_B4_SSPC_BitErr_04 : 53|1@1+ (1,0) [0|1] ""  JiaShiCang
 SG_ RPDU3_B4_SSPC_OnOffSta_04 : 52|1@1+ (1,0) [0|1] ""  JiaShiCang
 SG_ RPDU3_B4_SSPC_DianHuErr_04 : 51|1@1+ (1,0) [0|1] ""  JiaShiCang
 SG_ BackUp188 : 48|3@1+ (1,0) [0|0] ""  JiaShiCang
 SG_ RPDU3_B4_SSPC_I_Load_03 : 40|8@1+ (0.1,0) [0|25.5] "A"  JiaShiCang
 SG_ RPDU3_B4_SSPC_TripSta_03 : 38|2@1+ (1,0) [0|3] ""  JiaShiCang
 SG_ RPDU3_B4_SSPC_BitErr_03 : 37|1@1+ (1,0) [0|1] ""  JiaShiCang
 SG_ RPDU3_B4_SSPC_OnOffSta_03 : 36|1@1+ (1,0) [0|1] ""  JiaShiCang
 SG_ RPDU3_B4_SSPC_DianHuErr_03 : 35|1@1+ (1,0) [0|1] ""  JiaShiCang
 SG_ BackUp187 : 32|3@1+ (1,0) [0|0] ""  JiaShiCang
 SG_ RPDU3_B4_SSPC_I_Load_02 : 24|8@1+ (0.1,0) [0|25.5] "A"  JiaShiCang
 SG_ RPDU3_B4_SSPC_TripSta_02 : 22|2@1+ (1,0) [0|3] ""  JiaShiCang
 SG_ RPDU3_B4_SSPC_BitErr_02 : 21|1@1+ (1,0) [0|1] ""  JiaShiCang
 SG_ RPDU3_B4_SSPC_OnOffSta_02 : 20|1@1+ (1,0) [0|1] ""  JiaShiCang
 SG_ RPDU3_B4_SSPC_DianHuErr_02 : 19|1@1+ (1,0) [0|1] ""  JiaShiCang
 SG_ BackUp186 : 16|3@1+ (1,0) [0|0] ""  JiaShiCang
 SG_ RPDU3_B4_SSPC_I_Load_01 : 8|8@1+ (0.1,0) [0|25.5] "A"  JiaShiCang
 SG_ RPDU3_B4_SSPC_TripSta_01 : 6|2@1+ (1,0) [0|3] ""  JiaShiCang
 SG_ RPDU3_B4_SSPC_BitErr_01 : 5|1@1+ (1,0) [0|1] ""  JiaShiCang
 SG_ RPDU3_B4_SSPC_OnOffSta_01 : 4|1@1+ (1,0) [0|1] ""  JiaShiCang
 SG_ RPDU3_B4_SSPC_DianHuErr_01 : 3|1@1+ (1,0) [0|1] ""  JiaShiCang
 SG_ BackUp185 : 0|3@1+ (1,0) [0|0] ""  JiaShiCang

CM_ SG_ 2418933792 BackUp377 "预留";
CM_ SG_ 2418933792 BackUp376 "预留";
CM_ SG_ 2418933792 BackUp375 "预留";
CM_ SG_ 2418933792 BackUp374 "预留";
CM_ SG_ 2418933792 RPDU4_B1_SSPC_I_Load_18 "SSPC18通道电流";
CM_ SG_ 2418933792 RPDU4_B1_SSPC_TripSta_18 "SSPC18跳闸状态";
CM_ SG_ 2418933792 RPDU4_B1_SSPC_BitErr_18 "SSPC18通断周期自检状态";
CM_ SG_ 2418933792 RPDU4_B1_SSPC_OnOffSta_18 "SSPC18通断状态";
CM_ SG_ 2418933792 RPDU4_B1_SSPC_DianHuErr_18 "SSPC18电弧故障状态";
CM_ SG_ 2418933792 BackUp373 "预留";
CM_ SG_ 2418933792 RPDU4_B1_SSPC_I_Load_17 "SSPC17通道电流";
CM_ SG_ 2418933792 RPDU4_B1_SSPC_TripSta_17 "SSPC17跳闸状态";
CM_ SG_ 2418933792 RPDU4_B1_SSPC_BitErr_17 "SSPC17通断周期自检状态";
CM_ SG_ 2418933792 RPDU4_B1_SSPC_OnOffSta_17 "SSPC17通断状态";
CM_ SG_ 2418933792 RPDU4_B1_SSPC_DianHuErr_17 "SSPC17电弧故障状态";
CM_ SG_ 2418933792 BackUp372 "预留";
CM_ SG_ 2418868256 RPDU4_B1_SSPC_I_Load_16 "SSPC16通道电流";
CM_ SG_ 2418868256 RPDU4_B1_SSPC_TripSta_16 "SSPC16跳闸状态";
CM_ SG_ 2418868256 RPDU4_B1_SSPC_BitErr_16 "SSPC16通断周期自检状态";
CM_ SG_ 2418868256 RPDU4_B1_SSPC_OnOffSta_16 "SSPC16通断状态";
CM_ SG_ 2418868256 RPDU4_B1_SSPC_DianHuErr_16 "SSPC16电弧故障状态";
CM_ SG_ 2418868256 BackUp371 "预留";
CM_ SG_ 2418868256 RPDU4_B1_SSPC_I_Load_15 "SSPC15通道电流";
CM_ SG_ 2418868256 RPDU4_B1_SSPC_TripSta_15 "SSPC15跳闸状态";
CM_ SG_ 2418868256 RPDU4_B1_SSPC_BitErr_15 "SSPC15通断周期自检状态";
CM_ SG_ 2418868256 RPDU4_B1_SSPC_OnOffSta_15 "SSPC15通断状态";
CM_ SG_ 2418868256 RPDU4_B1_SSPC_DianHuErr_15 "SSPC15电弧故障状态";
CM_ SG_ 2418868256 BackUp370 "预留";
CM_ SG_ 2418868256 RPDU4_B1_SSPC_I_Load_14 "SSPC14通道电流";
CM_ SG_ 2418868256 RPDU4_B1_SSPC_TripSta_14 "SSPC14跳闸状态";
CM_ SG_ 2418868256 RPDU4_B1_SSPC_BitErr_14 "SSPC14通断周期自检状态";
CM_ SG_ 2418868256 RPDU4_B1_SSPC_OnOffSta_14 "SSPC14通断状态";
CM_ SG_ 2418868256 RPDU4_B1_SSPC_DianHuErr_14 "SSPC14电弧故障状态";
CM_ SG_ 2418868256 BackUp369 "预留";
CM_ SG_ 2418868256 RPDU4_B1_SSPC_I_Load_13 "SSPC13通道电流";
CM_ SG_ 2418868256 RPDU4_B1_SSPC_TripSta_13 "SSPC13跳闸状态";
CM_ SG_ 2418868256 RPDU4_B1_SSPC_BitErr_13 "SSPC13通断周期自检状态";
CM_ SG_ 2418868256 RPDU4_B1_SSPC_OnOffSta_13 "SSPC13通断状态";
CM_ SG_ 2418868256 RPDU4_B1_SSPC_DianHuErr_13 "SSPC13电弧故障状态";
CM_ SG_ 2418868256 BackUp368 "预留";
CM_ SG_ 2418802720 RPDU4_B1_SSPC_I_Load_12 "SSPC12通道电流";
CM_ SG_ 2418802720 RPDU4_B1_SSPC_TripSta_12 "SSPC12跳闸状态";
CM_ SG_ 2418802720 RPDU4_B1_SSPC_BitErr_12 "SSPC12通断周期自检状态";
CM_ SG_ 2418802720 RPDU4_B1_SSPC_OnOffSta_12 "SSPC12通断状态";
CM_ SG_ 2418802720 RPDU4_B1_SSPC_DianHuErr_12 "SSPC12电弧故障状态";
CM_ SG_ 2418802720 BackUp367 "预留";
CM_ SG_ 2418802720 RPDU4_B1_SSPC_I_Load_11 "SSPC11通道电流";
CM_ SG_ 2418802720 RPDU4_B1_SSPC_TripSta_11 "SSPC11跳闸状态";
CM_ SG_ 2418802720 RPDU4_B1_SSPC_BitErr_11 "SSPC11通断周期自检状态";
CM_ SG_ 2418802720 RPDU4_B1_SSPC_OnOffSta_11 "SSPC11通断状态";
CM_ SG_ 2418802720 RPDU4_B1_SSPC_DianHuErr_11 "SSPC11电弧故障状态";
CM_ SG_ 2418802720 BackUp366 "预留";
CM_ SG_ 2418802720 RPDU4_B1_SSPC_I_Load_10 "SSPC10通道电流";
CM_ SG_ 2418802720 RPDU4_B1_SSPC_TripSta_10 "SSPC10跳闸状态";
CM_ SG_ 2418802720 RPDU4_B1_SSPC_BitErr_10 "SSPC10通断周期自检状态";
CM_ SG_ 2418802720 RPDU4_B1_SSPC_OnOffSta_10 "SSPC10通断状态";
CM_ SG_ 2418802720 RPDU4_B1_SSPC_DianHuErr_10 "SSPC10电弧故障状态";
CM_ SG_ 2418802720 BackUp365 "预留";
CM_ SG_ 2418802720 RPDU4_B1_SSPC_I_Load_09 "SSPC9通道电流";
CM_ SG_ 2418802720 RPDU4_B1_SSPC_TripSta_09 "SSPC9跳闸状态";
CM_ SG_ 2418802720 RPDU4_B1_SSPC_BitErr_09 "SSPC9通断周期自检状态";
CM_ SG_ 2418802720 RPDU4_B1_SSPC_OnOffSta_09 "SSPC9通断状态";
CM_ SG_ 2418802720 RPDU4_B1_SSPC_DianHuErr_09 "SSPC9电弧故障状态";
CM_ SG_ 2418802720 BackUp364 "预留";
CM_ SG_ 2418737184 RPDU4_B1_SSPC_I_Load_08 "SSPC8通道电流";
CM_ SG_ 2418737184 RPDU4_B1_SSPC_TripSta_08 "SSPC8跳闸状态";
CM_ SG_ 2418737184 RPDU4_B1_SSPC_BitErr_08 "SSPC8通断周期自检状态";
CM_ SG_ 2418737184 RPDU4_B1_SSPC_OnOffSta_08 "SSPC8通断状态";
CM_ SG_ 2418737184 RPDU4_B1_SSPC_DianHuErr_08 "SSPC8电弧故障状态";
CM_ SG_ 2418737184 BackUp363 "预留";
CM_ SG_ 2418737184 RPDU4_B1_SSPC_I_Load_07 "SSPC7通道电流";
CM_ SG_ 2418737184 RPDU4_B1_SSPC_TripSta_07 "SSPC7跳闸状态";
CM_ SG_ 2418737184 RPDU4_B1_SSPC_BitErr_07 "SSPC7通断周期自检状态";
CM_ SG_ 2418737184 RPDU4_B1_SSPC_OnOffSta_07 "SSPC7通断状态";
CM_ SG_ 2418737184 RPDU4_B1_SSPC_DianHuErr_07 "SSPC7电弧故障状态";
CM_ SG_ 2418737184 BackUp362 "预留";
CM_ SG_ 2418737184 RPDU4_B1_SSPC_I_Load_06 "SSPC6通道电流";
CM_ SG_ 2418737184 RPDU4_B1_SSPC_TripSta_06 "SSPC6跳闸状态";
CM_ SG_ 2418737184 RPDU4_B1_SSPC_BitErr_06 "SSPC6通断周期自检状态";
CM_ SG_ 2418737184 RPDU4_B1_SSPC_OnOffSta_06 "SSPC6通断状态";
CM_ SG_ 2418737184 RPDU4_B1_SSPC_DianHuErr_06 "SSPC6电弧故障状态";
CM_ SG_ 2418737184 BackUp361 "预留";
CM_ SG_ 2418737184 RPDU4_B1_SSPC_I_Load_05 "SSPC5通道电流";
CM_ SG_ 2418737184 RPDU4_B1_SSPC_TripSta_05 "SSPC5跳闸状态";
CM_ SG_ 2418737184 RPDU4_B1_SSPC_BitErr_05 "SSPC5通断周期自检状态";
CM_ SG_ 2418737184 RPDU4_B1_SSPC_OnOffSta_05 "SSPC5通断状态";
CM_ SG_ 2418737184 RPDU4_B1_SSPC_DianHuErr_05 "SSPC5电弧故障状态";
CM_ SG_ 2418737184 BackUp360 "预留";
CM_ SG_ 2418671648 RPDU4_B1_SSPC_I_Load_04 "SSPC4通道电流";
CM_ SG_ 2418671648 RPDU4_B1_SSPC_TripSta_04 "SSPC4跳闸状态";
CM_ SG_ 2418671648 RPDU4_B1_SSPC_BitErr_04 "SSPC4通断周期自检状态";
CM_ SG_ 2418671648 RPDU4_B1_SSPC_OnOffSta_04 "SSPC4通断状态";
CM_ SG_ 2418671648 RPDU4_B1_SSPC_DianHuErr_04 "SSPC4电弧故障状态";
CM_ SG_ 2418671648 BackUp359 "预留";
CM_ SG_ 2418671648 RPDU4_B1_SSPC_I_Load_03 "SSPC3通道电流";
CM_ SG_ 2418671648 RPDU4_B1_SSPC_TripSta_03 "SSPC3跳闸状态";
CM_ SG_ 2418671648 RPDU4_B1_SSPC_BitErr_03 "SSPC3通断周期自检状态";
CM_ SG_ 2418671648 RPDU4_B1_SSPC_OnOffSta_03 "SSPC3通断状态";
CM_ SG_ 2418671648 RPDU4_B1_SSPC_DianHuErr_03 "SSPC3电弧故障状态";
CM_ SG_ 2418671648 BackUp358 "预留";
CM_ SG_ 2418671648 RPDU4_B1_SSPC_I_Load_02 "SSPC2通道电流";
CM_ SG_ 2418671648 RPDU4_B1_SSPC_TripSta_02 "SSPC2跳闸状态";
CM_ SG_ 2418671648 RPDU4_B1_SSPC_BitErr_02 "SSPC2通断周期自检状态";
CM_ SG_ 2418671648 RPDU4_B1_SSPC_OnOffSta_02 "SSPC2通断状态";
CM_ SG_ 2418671648 RPDU4_B1_SSPC_DianHuErr_02 "SSPC2电弧故障状态";
CM_ SG_ 2418671648 BackUp357 "预留";
CM_ SG_ 2418671648 RPDU4_B1_SSPC_I_Load_01 "SSPC1通道电流";
CM_ SG_ 2418671648 RPDU4_B1_SSPC_TripSta_01 "SSPC1跳闸状态";
CM_ SG_ 2418671648 RPDU4_B1_SSPC_BitErr_01 "SSPC1通断周期自检状态";
CM_ SG_ 2418671648 RPDU4_B1_SSPC_OnOffSta_01 "SSPC1通断状态";
CM_ SG_ 2418671648 RPDU4_B1_SSPC_DianHuErr_01 "SSPC1电弧故障状态";
CM_ SG_ 2418671648 BackUp356 "预留";
CM_ SG_ 2418606112 RPDU2_Index "序号";
CM_ SG_ 2418606112 BackUp355 "预留";
CM_ SG_ 2418606112 RPDU2_Time "时间";
CM_ SG_ 2418606112 RPDU2_SSPC_Ver "SSPC模块软件版本号";
CM_ SG_ 2418606112 RPDU2_PS_Ver "PS软件版本号";
CM_ SG_ 2418606112 BackUp354 "预留";
CM_ SG_ 2418606112 RPDU2_Hard_Num "硬件修改号";
CM_ SG_ 2418540576 BackUp353 "预留";
CM_ SG_ 2418540576 BackUp352 "预留";
CM_ SG_ 2418540576 RPDU2_B6_SSPC_I_Load_07 "SSPC7通道电流";
CM_ SG_ 2418540576 RPDU2_B6_SSPC_TripSta_07 "SSPC7跳闸状态";
CM_ SG_ 2418540576 RPDU2_B6_SSPC_BitErr_07 "SSPC7通断周期自检状态";
CM_ SG_ 2418540576 RPDU2_B6_SSPC_OnOffSta_07 "SSPC7通断状态";
CM_ SG_ 2418540576 RPDU2_B6_SSPC_DianHuErr_07 "SSPC7电弧故障状态";
CM_ SG_ 2418540576 BackUp351 "预留";
CM_ SG_ 2418540576 RPDU2_B6_SSPC_I_Load_06 "SSPC6通道电流";
CM_ SG_ 2418540576 RPDU2_B6_SSPC_TripSta_06 "SSPC6跳闸状态";
CM_ SG_ 2418540576 RPDU2_B6_SSPC_BitErr_06 "SSPC6通断周期自检状态";
CM_ SG_ 2418540576 RPDU2_B6_SSPC_OnOffSta_06 "SSPC6通断状态";
CM_ SG_ 2418540576 RPDU2_B6_SSPC_DianHuErr_06 "SSPC6电弧故障状态";
CM_ SG_ 2418540576 BackUp350 "预留";
CM_ SG_ 2418540576 RPDU2_B6_SSPC_I_Load_05 "SSPC5通道电流";
CM_ SG_ 2418540576 RPDU2_B6_SSPC_TripSta_05 "SSPC5跳闸状态";
CM_ SG_ 2418540576 RPDU2_B6_SSPC_BitErr_05 "SSPC5通断周期自检状态";
CM_ SG_ 2418540576 RPDU2_B6_SSPC_OnOffSta_05 "SSPC5通断状态";
CM_ SG_ 2418540576 RPDU2_B6_SSPC_DianHuErr_05 "SSPC5电弧故障状态";
CM_ SG_ 2418540576 BackUp349 "预留";
CM_ SG_ 2418475040 RPDU2_B6_SSPC_I_Load_04 "SSPC4通道电流";
CM_ SG_ 2418475040 RPDU2_B6_SSPC_TripSta_04 "SSPC4跳闸状态";
CM_ SG_ 2418475040 RPDU2_B6_SSPC_BitErr_04 "SSPC4通断周期自检状态";
CM_ SG_ 2418475040 RPDU2_B6_SSPC_OnOffSta_04 "SSPC4通断状态";
CM_ SG_ 2418475040 RPDU2_B6_SSPC_DianHuErr_04 "SSPC4电弧故障状态";
CM_ SG_ 2418475040 BackUp348 "预留";
CM_ SG_ 2418475040 RPDU2_B6_SSPC_I_Load_03 "SSPC3通道电流";
CM_ SG_ 2418475040 RPDU2_B6_SSPC_TripSta_03 "SSPC3跳闸状态";
CM_ SG_ 2418475040 RPDU2_B6_SSPC_BitErr_03 "SSPC3通断周期自检状态";
CM_ SG_ 2418475040 RPDU2_B6_SSPC_OnOffSta_03 "SSPC3通断状态";
CM_ SG_ 2418475040 RPDU2_B6_SSPC_DianHuErr_03 "SSPC3电弧故障状态";
CM_ SG_ 2418475040 BackUp347 "预留";
CM_ SG_ 2418475040 RPDU2_B6_SSPC_I_Load_02 "SSPC2通道电流";
CM_ SG_ 2418475040 RPDU2_B6_SSPC_TripSta_02 "SSPC2跳闸状态";
CM_ SG_ 2418475040 RPDU2_B6_SSPC_BitErr_02 "SSPC2通断周期自检状态";
CM_ SG_ 2418475040 RPDU2_B6_SSPC_OnOffSta_02 "SSPC2通断状态";
CM_ SG_ 2418475040 RPDU2_B6_SSPC_DianHuErr_02 "SSPC2电弧故障状态";
CM_ SG_ 2418475040 BackUp346 "预留";
CM_ SG_ 2418475040 RPDU2_B6_SSPC_I_Load_01 "SSPC1通道电流";
CM_ SG_ 2418475040 RPDU2_B6_SSPC_TripSta_01 "SSPC1跳闸状态";
CM_ SG_ 2418475040 RPDU2_B6_SSPC_BitErr_01 "SSPC1通断周期自检状态";
CM_ SG_ 2418475040 RPDU2_B6_SSPC_OnOffSta_01 "SSPC1通断状态";
CM_ SG_ 2418475040 RPDU2_B6_SSPC_DianHuErr_01 "SSPC1电弧故障状态";
CM_ SG_ 2418475040 BackUp345 "预留";
CM_ SG_ 2418409504 BackUp344 "预留";
CM_ SG_ 2418409504 BackUp343 "预留";
CM_ SG_ 2418409504 RPDU2_B5_SSPC_I_Load_07 "SSPC7通道电流";
CM_ SG_ 2418409504 RPDU2_B5_SSPC_TripSta_07 "SSPC7跳闸状态";
CM_ SG_ 2418409504 RPDU2_B5_SSPC_BitErr_07 "SSPC7通断周期自检状态";
CM_ SG_ 2418409504 RPDU2_B5_SSPC_OnOffSta_07 "SSPC7通断状态";
CM_ SG_ 2418409504 RPDU2_B5_SSPC_DianHuErr_07 "SSPC7电弧故障状态";
CM_ SG_ 2418409504 BackUp342 "预留";
CM_ SG_ 2418409504 RPDU2_B5_SSPC_I_Load_06 "SSPC6通道电流";
CM_ SG_ 2418409504 RPDU2_B5_SSPC_TripSta_06 "SSPC6跳闸状态";
CM_ SG_ 2418409504 RPDU2_B5_SSPC_BitErr_06 "SSPC6通断周期自检状态";
CM_ SG_ 2418409504 RPDU2_B5_SSPC_OnOffSta_06 "SSPC6通断状态";
CM_ SG_ 2418409504 RPDU2_B5_SSPC_DianHuErr_06 "SSPC6电弧故障状态";
CM_ SG_ 2418409504 BackUp341 "预留";
CM_ SG_ 2418409504 RPDU2_B5_SSPC_I_Load_05 "SSPC5通道电流";
CM_ SG_ 2418409504 RPDU2_B5_SSPC_TripSta_05 "SSPC5跳闸状态";
CM_ SG_ 2418409504 RPDU2_B5_SSPC_BitErr_05 "SSPC5通断周期自检状态";
CM_ SG_ 2418409504 RPDU2_B5_SSPC_OnOffSta_05 "SSPC5通断状态";
CM_ SG_ 2418409504 RPDU2_B5_SSPC_DianHuErr_05 "SSPC5电弧故障状态";
CM_ SG_ 2418409504 BackUp340 "预留";
CM_ SG_ 2418343968 RPDU2_B5_SSPC_I_Load_04 "SSPC4通道电流";
CM_ SG_ 2418343968 RPDU2_B5_SSPC_TripSta_04 "SSPC4跳闸状态";
CM_ SG_ 2418343968 RPDU2_B5_SSPC_BitErr_04 "SSPC4通断周期自检状态";
CM_ SG_ 2418343968 RPDU2_B5_SSPC_OnOffSta_04 "SSPC4通断状态";
CM_ SG_ 2418343968 RPDU2_B5_SSPC_DianHuErr_04 "SSPC4电弧故障状态";
CM_ SG_ 2418343968 BackUp339 "预留";
CM_ SG_ 2418343968 RPDU2_B5_SSPC_I_Load_03 "SSPC3通道电流";
CM_ SG_ 2418343968 RPDU2_B5_SSPC_TripSta_03 "SSPC3跳闸状态";
CM_ SG_ 2418343968 RPDU2_B5_SSPC_BitErr_03 "SSPC3通断周期自检状态";
CM_ SG_ 2418343968 RPDU2_B5_SSPC_OnOffSta_03 "SSPC3通断状态";
CM_ SG_ 2418343968 RPDU2_B5_SSPC_DianHuErr_03 "SSPC3电弧故障状态";
CM_ SG_ 2418343968 BackUp338 "预留";
CM_ SG_ 2418343968 RPDU2_B5_SSPC_I_Load_02 "SSPC2通道电流";
CM_ SG_ 2418343968 RPDU2_B5_SSPC_TripSta_02 "SSPC2跳闸状态";
CM_ SG_ 2418343968 RPDU2_B5_SSPC_BitErr_02 "SSPC2通断周期自检状态";
CM_ SG_ 2418343968 RPDU2_B5_SSPC_OnOffSta_02 "SSPC2通断状态";
CM_ SG_ 2418343968 RPDU2_B5_SSPC_DianHuErr_02 "SSPC2电弧故障状态";
CM_ SG_ 2418343968 BackUp337 "预留";
CM_ SG_ 2418343968 RPDU2_B5_SSPC_I_Load_01 "SSPC1通道电流";
CM_ SG_ 2418343968 RPDU2_B5_SSPC_TripSta_01 "SSPC1跳闸状态";
CM_ SG_ 2418343968 RPDU2_B5_SSPC_BitErr_01 "SSPC1通断周期自检状态";
CM_ SG_ 2418343968 RPDU2_B5_SSPC_OnOffSta_01 "SSPC1通断状态";
CM_ SG_ 2418343968 RPDU2_B5_SSPC_DianHuErr_01 "SSPC1电弧故障状态";
CM_ SG_ 2418343968 BackUp336 "预留";
CM_ SG_ 2418278432 BackUp335 "预留";
CM_ SG_ 2418278432 BackUp334 "预留";
CM_ SG_ 2418278432 BackUp333 "预留";
CM_ SG_ 2418278432 BackUp332 "预留";
CM_ SG_ 2418278432 RPDU2_B4_SSPC_I_Load_18 "SSPC18通道电流";
CM_ SG_ 2418278432 RPDU2_B4_SSPC_TripSta_18 "SSPC18跳闸状态";
CM_ SG_ 2418278432 RPDU2_B4_SSPC_BitErr_18 "SSPC18通断周期自检状态";
CM_ SG_ 2418278432 RPDU2_B4_SSPC_OnOffSta_18 "SSPC18通断状态";
CM_ SG_ 2418278432 RPDU2_B4_SSPC_DianHuErr_18 "SSPC18电弧故障状态";
CM_ SG_ 2418278432 BackUp331 "预留";
CM_ SG_ 2418278432 RPDU2_B4_SSPC_I_Load_17 "SSPC17通道电流";
CM_ SG_ 2418278432 RPDU2_B4_SSPC_TripSta_17 "SSPC17跳闸状态";
CM_ SG_ 2418278432 RPDU2_B4_SSPC_BitErr_17 "SSPC17通断周期自检状态";
CM_ SG_ 2418278432 RPDU2_B4_SSPC_OnOffSta_17 "SSPC17通断状态";
CM_ SG_ 2418278432 RPDU2_B4_SSPC_DianHuErr_17 "SSPC17电弧故障状态";
CM_ SG_ 2418278432 BackUp330 "预留";
CM_ SG_ 2418212896 RPDU2_B4_SSPC_I_Load_16 "SSPC16通道电流";
CM_ SG_ 2418212896 RPDU2_B4_SSPC_TripSta_16 "SSPC16跳闸状态";
CM_ SG_ 2418212896 RPDU2_B4_SSPC_BitErr_16 "SSPC16通断周期自检状态";
CM_ SG_ 2418212896 RPDU2_B4_SSPC_OnOffSta_16 "SSPC16通断状态";
CM_ SG_ 2418212896 RPDU2_B4_SSPC_DianHuErr_16 "SSPC16电弧故障状态";
CM_ SG_ 2418212896 BackUp329 "预留";
CM_ SG_ 2418212896 RPDU2_B4_SSPC_I_Load_15 "SSPC15通道电流";
CM_ SG_ 2418212896 RPDU2_B4_SSPC_TripSta_15 "SSPC15跳闸状态";
CM_ SG_ 2418212896 RPDU2_B4_SSPC_BitErr_15 "SSPC15通断周期自检状态";
CM_ SG_ 2418212896 RPDU2_B4_SSPC_OnOffSta_15 "SSPC15通断状态";
CM_ SG_ 2418212896 RPDU2_B4_SSPC_DianHuErr_15 "SSPC15电弧故障状态";
CM_ SG_ 2418212896 BackUp328 "预留";
CM_ SG_ 2418212896 RPDU2_B4_SSPC_I_Load_14 "SSPC14通道电流";
CM_ SG_ 2418212896 RPDU2_B4_SSPC_TripSta_14 "SSPC14跳闸状态";
CM_ SG_ 2418212896 RPDU2_B4_SSPC_BitErr_14 "SSPC14通断周期自检状态";
CM_ SG_ 2418212896 RPDU2_B4_SSPC_OnOffSta_14 "SSPC14通断状态";
CM_ SG_ 2418212896 RPDU2_B4_SSPC_DianHuErr_14 "SSPC14电弧故障状态";
CM_ SG_ 2418212896 BackUp327 "预留";
CM_ SG_ 2418212896 RPDU2_B4_SSPC_I_Load_13 "SSPC13通道电流";
CM_ SG_ 2418212896 RPDU2_B4_SSPC_TripSta_13 "SSPC13跳闸状态";
CM_ SG_ 2418212896 RPDU2_B4_SSPC_BitErr_13 "SSPC13通断周期自检状态";
CM_ SG_ 2418212896 RPDU2_B4_SSPC_OnOffSta_13 "SSPC13通断状态";
CM_ SG_ 2418212896 RPDU2_B4_SSPC_DianHuErr_13 "SSPC13电弧故障状态";
CM_ SG_ 2418212896 BackUp326 "预留";
CM_ SG_ 2418147360 RPDU2_B4_SSPC_I_Load_12 "SSPC12通道电流";
CM_ SG_ 2418147360 RPDU2_B4_SSPC_TripSta_12 "SSPC12跳闸状态";
CM_ SG_ 2418147360 RPDU2_B4_SSPC_BitErr_12 "SSPC12通断周期自检状态";
CM_ SG_ 2418147360 RPDU2_B4_SSPC_OnOffSta_12 "SSPC12通断状态";
CM_ SG_ 2418147360 RPDU2_B4_SSPC_DianHuErr_12 "SSPC12电弧故障状态";
CM_ SG_ 2418147360 BackUp325 "预留";
CM_ SG_ 2418147360 RPDU2_B4_SSPC_I_Load_11 "SSPC11通道电流";
CM_ SG_ 2418147360 RPDU2_B4_SSPC_TripSta_11 "SSPC11跳闸状态";
CM_ SG_ 2418147360 RPDU2_B4_SSPC_BitErr_11 "SSPC11通断周期自检状态";
CM_ SG_ 2418147360 RPDU2_B4_SSPC_OnOffSta_11 "SSPC11通断状态";
CM_ SG_ 2418147360 RPDU2_B4_SSPC_DianHuErr_11 "SSPC11电弧故障状态";
CM_ SG_ 2418147360 BackUp324 "预留";
CM_ SG_ 2418147360 RPDU2_B4_SSPC_I_Load_10 "SSPC10通道电流";
CM_ SG_ 2418147360 RPDU2_B4_SSPC_TripSta_10 "SSPC10跳闸状态";
CM_ SG_ 2418147360 RPDU2_B4_SSPC_BitErr_10 "SSPC10通断周期自检状态";
CM_ SG_ 2418147360 RPDU2_B4_SSPC_OnOffSta_10 "SSPC10通断状态";
CM_ SG_ 2418147360 RPDU2_B4_SSPC_DianHuErr_10 "SSPC10电弧故障状态";
CM_ SG_ 2418147360 BackUp323 "预留";
CM_ SG_ 2418147360 RPDU2_B4_SSPC_I_Load_09 "SSPC9通道电流";
CM_ SG_ 2418147360 RPDU2_B4_SSPC_TripSta_09 "SSPC9跳闸状态";
CM_ SG_ 2418147360 RPDU2_B4_SSPC_BitErr_09 "SSPC9通断周期自检状态";
CM_ SG_ 2418147360 RPDU2_B4_SSPC_OnOffSta_09 "SSPC9通断状态";
CM_ SG_ 2418147360 RPDU2_B4_SSPC_DianHuErr_09 "SSPC9电弧故障状态";
CM_ SG_ 2418147360 BackUp322 "预留";
CM_ SG_ 2418081824 RPDU2_B4_SSPC_I_Load_08 "SSPC8通道电流";
CM_ SG_ 2418081824 RPDU2_B4_SSPC_TripSta_08 "SSPC8跳闸状态";
CM_ SG_ 2418081824 RPDU2_B4_SSPC_BitErr_08 "SSPC8通断周期自检状态";
CM_ SG_ 2418081824 RPDU2_B4_SSPC_OnOffSta_08 "SSPC8通断状态";
CM_ SG_ 2418081824 RPDU2_B4_SSPC_DianHuErr_08 "SSPC8电弧故障状态";
CM_ SG_ 2418081824 BackUp321 "预留";
CM_ SG_ 2418081824 RPDU2_B4_SSPC_I_Load_07 "SSPC7通道电流";
CM_ SG_ 2418081824 RPDU2_B4_SSPC_TripSta_07 "SSPC7跳闸状态";
CM_ SG_ 2418081824 RPDU2_B4_SSPC_BitErr_07 "SSPC7通断周期自检状态";
CM_ SG_ 2418081824 RPDU2_B4_SSPC_OnOffSta_07 "SSPC7通断状态";
CM_ SG_ 2418081824 RPDU2_B4_SSPC_DianHuErr_07 "SSPC7电弧故障状态";
CM_ SG_ 2418081824 BackUp320 "预留";
CM_ SG_ 2418081824 RPDU2_B4_SSPC_I_Load_06 "SSPC6通道电流";
CM_ SG_ 2418081824 RPDU2_B4_SSPC_TripSta_06 "SSPC6跳闸状态";
CM_ SG_ 2418081824 RPDU2_B4_SSPC_BitErr_06 "SSPC6通断周期自检状态";
CM_ SG_ 2418081824 RPDU2_B4_SSPC_OnOffSta_06 "SSPC6通断状态";
CM_ SG_ 2418081824 RPDU2_B4_SSPC_DianHuErr_06 "SSPC6电弧故障状态";
CM_ SG_ 2418081824 BackUp319 "预留";
CM_ SG_ 2418081824 RPDU2_B4_SSPC_I_Load_05 "SSPC5通道电流";
CM_ SG_ 2418081824 RPDU2_B4_SSPC_TripSta_05 "SSPC5跳闸状态";
CM_ SG_ 2418081824 RPDU2_B4_SSPC_BitErr_05 "SSPC5通断周期自检状态";
CM_ SG_ 2418081824 RPDU2_B4_SSPC_OnOffSta_05 "SSPC5通断状态";
CM_ SG_ 2418081824 RPDU2_B4_SSPC_DianHuErr_05 "SSPC5电弧故障状态";
CM_ SG_ 2418081824 BackUp318 "预留";
CM_ SG_ 2418016288 RPDU2_B4_SSPC_I_Load_04 "SSPC4通道电流";
CM_ SG_ 2418016288 RPDU2_B4_SSPC_TripSta_04 "SSPC4跳闸状态";
CM_ SG_ 2418016288 RPDU2_B4_SSPC_BitErr_04 "SSPC4通断周期自检状态";
CM_ SG_ 2418016288 RPDU2_B4_SSPC_OnOffSta_04 "SSPC4通断状态";
CM_ SG_ 2418016288 RPDU2_B4_SSPC_DianHuErr_04 "SSPC4电弧故障状态";
CM_ SG_ 2418016288 BackUp317 "预留";
CM_ SG_ 2418016288 RPDU2_B4_SSPC_I_Load_03 "SSPC3通道电流";
CM_ SG_ 2418016288 RPDU2_B4_SSPC_TripSta_03 "SSPC3跳闸状态";
CM_ SG_ 2418016288 RPDU2_B4_SSPC_BitErr_03 "SSPC3通断周期自检状态";
CM_ SG_ 2418016288 RPDU2_B4_SSPC_OnOffSta_03 "SSPC3通断状态";
CM_ SG_ 2418016288 RPDU2_B4_SSPC_DianHuErr_03 "SSPC3电弧故障状态";
CM_ SG_ 2418016288 BackUp316 "预留";
CM_ SG_ 2418016288 RPDU2_B4_SSPC_I_Load_02 "SSPC2通道电流";
CM_ SG_ 2418016288 RPDU2_B4_SSPC_TripSta_02 "SSPC2跳闸状态";
CM_ SG_ 2418016288 RPDU2_B4_SSPC_BitErr_02 "SSPC2通断周期自检状态";
CM_ SG_ 2418016288 RPDU2_B4_SSPC_OnOffSta_02 "SSPC2通断状态";
CM_ SG_ 2418016288 RPDU2_B4_SSPC_DianHuErr_02 "SSPC2电弧故障状态";
CM_ SG_ 2418016288 BackUp315 "预留";
CM_ SG_ 2418016288 RPDU2_B4_SSPC_I_Load_01 "SSPC1通道电流";
CM_ SG_ 2418016288 RPDU2_B4_SSPC_TripSta_01 "SSPC1跳闸状态";
CM_ SG_ 2418016288 RPDU2_B4_SSPC_BitErr_01 "SSPC1通断周期自检状态";
CM_ SG_ 2418016288 RPDU2_B4_SSPC_OnOffSta_01 "SSPC1通断状态";
CM_ SG_ 2418016288 RPDU2_B4_SSPC_DianHuErr_01 "SSPC1电弧故障状态";
CM_ SG_ 2418016288 BackUp314 "预留";
CM_ SG_ 2417950752 BackUp313 "预留";
CM_ SG_ 2417950752 BackUp312 "预留";
CM_ SG_ 2417950752 BackUp311 "预留";
CM_ SG_ 2417950752 BackUp310 "预留";
CM_ SG_ 2417950752 RPDU2_B3_SSPC_I_Load_18 "SSPC18通道电流";
CM_ SG_ 2417950752 RPDU2_B3_SSPC_TripSta_18 "SSPC18跳闸状态";
CM_ SG_ 2417950752 RPDU2_B3_SSPC_BitErr_18 "SSPC18通断周期自检状态";
CM_ SG_ 2417950752 RPDU2_B3_SSPC_OnOffSta_18 "SSPC18通断状态";
CM_ SG_ 2417950752 RPDU2_B3_SSPC_DianHuErr_18 "SSPC18电弧故障状态";
CM_ SG_ 2417950752 BackUp309 "预留";
CM_ SG_ 2417950752 RPDU2_B3_SSPC_I_Load_17 "SSPC17通道电流";
CM_ SG_ 2417950752 RPDU2_B3_SSPC_TripSta_17 "SSPC17跳闸状态";
CM_ SG_ 2417950752 RPDU2_B3_SSPC_BitErr_17 "SSPC17通断周期自检状态";
CM_ SG_ 2417950752 RPDU2_B3_SSPC_OnOffSta_17 "SSPC17通断状态";
CM_ SG_ 2417950752 RPDU2_B3_SSPC_DianHuErr_17 "SSPC17电弧故障状态";
CM_ SG_ 2417950752 BackUp308 "预留";
CM_ SG_ 2417885216 RPDU2_B3_SSPC_I_Load_16 "SSPC16通道电流";
CM_ SG_ 2417885216 RPDU2_B3_SSPC_TripSta_16 "SSPC16跳闸状态";
CM_ SG_ 2417885216 RPDU2_B3_SSPC_BitErr_16 "SSPC16通断周期自检状态";
CM_ SG_ 2417885216 RPDU2_B3_SSPC_OnOffSta_16 "SSPC16通断状态";
CM_ SG_ 2417885216 RPDU2_B3_SSPC_DianHuErr_16 "SSPC16电弧故障状态";
CM_ SG_ 2417885216 BackUp307 "预留";
CM_ SG_ 2417885216 RPDU2_B3_SSPC_I_Load_15 "SSPC15通道电流";
CM_ SG_ 2417885216 RPDU2_B3_SSPC_TripSta_15 "SSPC15跳闸状态";
CM_ SG_ 2417885216 RPDU2_B3_SSPC_BitErr_15 "SSPC15通断周期自检状态";
CM_ SG_ 2417885216 RPDU2_B3_SSPC_OnOffSta_15 "SSPC15通断状态";
CM_ SG_ 2417885216 RPDU2_B3_SSPC_DianHuErr_15 "SSPC15电弧故障状态";
CM_ SG_ 2417885216 BackUp306 "预留";
CM_ SG_ 2417885216 RPDU2_B3_SSPC_I_Load_14 "SSPC14通道电流";
CM_ SG_ 2417885216 RPDU2_B3_SSPC_TripSta_14 "SSPC14跳闸状态";
CM_ SG_ 2417885216 RPDU2_B3_SSPC_BitErr_14 "SSPC14通断周期自检状态";
CM_ SG_ 2417885216 RPDU2_B3_SSPC_OnOffSta_14 "SSPC14通断状态";
CM_ SG_ 2417885216 RPDU2_B3_SSPC_DianHuErr_14 "SSPC14电弧故障状态";
CM_ SG_ 2417885216 BackUp305 "预留";
CM_ SG_ 2417885216 RPDU2_B3_SSPC_I_Load_13 "SSPC13通道电流";
CM_ SG_ 2417885216 RPDU2_B3_SSPC_TripSta_13 "SSPC13跳闸状态";
CM_ SG_ 2417885216 RPDU2_B3_SSPC_BitErr_13 "SSPC13通断周期自检状态";
CM_ SG_ 2417885216 RPDU2_B3_SSPC_OnOffSta_13 "SSPC13通断状态";
CM_ SG_ 2417885216 RPDU2_B3_SSPC_DianHuErr_13 "SSPC13电弧故障状态";
CM_ SG_ 2417885216 BackUp304 "预留";
CM_ SG_ 2417819680 RPDU2_B3_SSPC_I_Load_12 "SSPC12通道电流";
CM_ SG_ 2417819680 RPDU2_B3_SSPC_TripSta_12 "SSPC12跳闸状态";
CM_ SG_ 2417819680 RPDU2_B3_SSPC_BitErr_12 "SSPC12通断周期自检状态";
CM_ SG_ 2417819680 RPDU2_B3_SSPC_OnOffSta_12 "SSPC12通断状态";
CM_ SG_ 2417819680 RPDU2_B3_SSPC_DianHuErr_12 "SSPC12电弧故障状态";
CM_ SG_ 2417819680 BackUp303 "预留";
CM_ SG_ 2417819680 RPDU2_B3_SSPC_I_Load_11 "SSPC11通道电流";
CM_ SG_ 2417819680 RPDU2_B3_SSPC_TripSta_11 "SSPC11跳闸状态";
CM_ SG_ 2417819680 RPDU2_B3_SSPC_BitErr_11 "SSPC11通断周期自检状态";
CM_ SG_ 2417819680 RPDU2_B3_SSPC_OnOffSta_11 "SSPC11通断状态";
CM_ SG_ 2417819680 RPDU2_B3_SSPC_DianHuErr_11 "SSPC11电弧故障状态";
CM_ SG_ 2417819680 BackUp302 "预留";
CM_ SG_ 2417819680 RPDU2_B3_SSPC_I_Load_10 "SSPC10通道电流";
CM_ SG_ 2417819680 RPDU2_B3_SSPC_TripSta_10 "SSPC10跳闸状态";
CM_ SG_ 2417819680 RPDU2_B3_SSPC_BitErr_10 "SSPC10通断周期自检状态";
CM_ SG_ 2417819680 RPDU2_B3_SSPC_OnOffSta_10 "SSPC10通断状态";
CM_ SG_ 2417819680 RPDU2_B3_SSPC_DianHuErr_10 "SSPC10电弧故障状态";
CM_ SG_ 2417819680 BackUp301 "预留";
CM_ SG_ 2417819680 RPDU2_B3_SSPC_I_Load_09 "SSPC9通道电流";
CM_ SG_ 2417819680 RPDU2_B3_SSPC_TripSta_09 "SSPC9跳闸状态";
CM_ SG_ 2417819680 RPDU2_B3_SSPC_BitErr_09 "SSPC9通断周期自检状态";
CM_ SG_ 2417819680 RPDU2_B3_SSPC_OnOffSta_09 "SSPC9通断状态";
CM_ SG_ 2417819680 RPDU2_B3_SSPC_DianHuErr_09 "SSPC9电弧故障状态";
CM_ SG_ 2417819680 BackUp300 "预留";
CM_ SG_ 2417754144 RPDU2_B3_SSPC_I_Load_08 "SSPC8通道电流";
CM_ SG_ 2417754144 RPDU2_B3_SSPC_TripSta_08 "SSPC8跳闸状态";
CM_ SG_ 2417754144 RPDU2_B3_SSPC_BitErr_08 "SSPC8通断周期自检状态";
CM_ SG_ 2417754144 RPDU2_B3_SSPC_OnOffSta_08 "SSPC8通断状态";
CM_ SG_ 2417754144 RPDU2_B3_SSPC_DianHuErr_08 "SSPC8电弧故障状态";
CM_ SG_ 2417754144 BackUp299 "预留";
CM_ SG_ 2417754144 RPDU2_B3_SSPC_I_Load_07 "SSPC7通道电流";
CM_ SG_ 2417754144 RPDU2_B3_SSPC_TripSta_07 "SSPC7跳闸状态";
CM_ SG_ 2417754144 RPDU2_B3_SSPC_BitErr_07 "SSPC7通断周期自检状态";
CM_ SG_ 2417754144 RPDU2_B3_SSPC_OnOffSta_07 "SSPC7通断状态";
CM_ SG_ 2417754144 RPDU2_B3_SSPC_DianHuErr_07 "SSPC7电弧故障状态";
CM_ SG_ 2417754144 BackUp298 "预留";
CM_ SG_ 2417754144 RPDU2_B3_SSPC_I_Load_06 "SSPC6通道电流";
CM_ SG_ 2417754144 RPDU2_B3_SSPC_TripSta_06 "SSPC6跳闸状态";
CM_ SG_ 2417754144 RPDU2_B3_SSPC_BitErr_06 "SSPC6通断周期自检状态";
CM_ SG_ 2417754144 RPDU2_B3_SSPC_OnOffSta_06 "SSPC6通断状态";
CM_ SG_ 2417754144 RPDU2_B3_SSPC_DianHuErr_06 "SSPC6电弧故障状态";
CM_ SG_ 2417754144 BackUp297 "预留";
CM_ SG_ 2417754144 RPDU2_B3_SSPC_I_Load_05 "SSPC5通道电流";
CM_ SG_ 2417754144 RPDU2_B3_SSPC_TripSta_05 "SSPC5跳闸状态";
CM_ SG_ 2417754144 RPDU2_B3_SSPC_BitErr_05 "SSPC5通断周期自检状态";
CM_ SG_ 2417754144 RPDU2_B3_SSPC_OnOffSta_05 "SSPC5通断状态";
CM_ SG_ 2417754144 RPDU2_B3_SSPC_DianHuErr_05 "SSPC5电弧故障状态";
CM_ SG_ 2417754144 BackUp296 "预留";
CM_ SG_ 2417688608 RPDU2_B3_SSPC_I_Load_04 "SSPC4通道电流";
CM_ SG_ 2417688608 RPDU2_B3_SSPC_TripSta_04 "SSPC4跳闸状态";
CM_ SG_ 2417688608 RPDU2_B3_SSPC_BitErr_04 "SSPC4通断周期自检状态";
CM_ SG_ 2417688608 RPDU2_B3_SSPC_OnOffSta_04 "SSPC4通断状态";
CM_ SG_ 2417688608 RPDU2_B3_SSPC_DianHuErr_04 "SSPC4电弧故障状态";
CM_ SG_ 2417688608 BackUp295 "预留";
CM_ SG_ 2417688608 RPDU2_B3_SSPC_I_Load_03 "SSPC3通道电流";
CM_ SG_ 2417688608 RPDU2_B3_SSPC_TripSta_03 "SSPC3跳闸状态";
CM_ SG_ 2417688608 RPDU2_B3_SSPC_BitErr_03 "SSPC3通断周期自检状态";
CM_ SG_ 2417688608 RPDU2_B3_SSPC_OnOffSta_03 "SSPC3通断状态";
CM_ SG_ 2417688608 RPDU2_B3_SSPC_DianHuErr_03 "SSPC3电弧故障状态";
CM_ SG_ 2417688608 BackUp294 "预留";
CM_ SG_ 2417688608 RPDU2_B3_SSPC_I_Load_02 "SSPC2通道电流";
CM_ SG_ 2417688608 RPDU2_B3_SSPC_TripSta_02 "SSPC2跳闸状态";
CM_ SG_ 2417688608 RPDU2_B3_SSPC_BitErr_02 "SSPC2通断周期自检状态";
CM_ SG_ 2417688608 RPDU2_B3_SSPC_OnOffSta_02 "SSPC2通断状态";
CM_ SG_ 2417688608 RPDU2_B3_SSPC_DianHuErr_02 "SSPC2电弧故障状态";
CM_ SG_ 2417688608 BackUp293 "预留";
CM_ SG_ 2417688608 RPDU2_B3_SSPC_I_Load_01 "SSPC1通道电流";
CM_ SG_ 2417688608 RPDU2_B3_SSPC_TripSta_01 "SSPC1跳闸状态";
CM_ SG_ 2417688608 RPDU2_B3_SSPC_BitErr_01 "SSPC1通断周期自检状态";
CM_ SG_ 2417688608 RPDU2_B3_SSPC_OnOffSta_01 "SSPC1通断状态";
CM_ SG_ 2417688608 RPDU2_B3_SSPC_DianHuErr_01 "SSPC1电弧故障状态";
CM_ SG_ 2417688608 BackUp292 "预留";
CM_ SG_ 2417623072 BackUp291 "预留";
CM_ SG_ 2417623072 BackUp290 "预留";
CM_ SG_ 2417623072 BackUp289 "预留";
CM_ SG_ 2417623072 BackUp288 "预留";
CM_ SG_ 2417623072 RPDU2_B2_SSPC_I_Load_18 "SSPC18通道电流";
CM_ SG_ 2417623072 RPDU2_B2_SSPC_TripSta_18 "SSPC18跳闸状态";
CM_ SG_ 2417623072 RPDU2_B2_SSPC_BitErr_18 "SSPC18通断周期自检状态";
CM_ SG_ 2417623072 RPDU2_B2_SSPC_OnOffSta_18 "SSPC18通断状态";
CM_ SG_ 2417623072 RPDU2_B2_SSPC_DianHuErr_18 "SSPC18电弧故障状态";
CM_ SG_ 2417623072 BackUp287 "预留";
CM_ SG_ 2417623072 RPDU2_B2_SSPC_I_Load_17 "SSPC17通道电流";
CM_ SG_ 2417623072 RPDU2_B2_SSPC_TripSta_17 "SSPC17跳闸状态";
CM_ SG_ 2417623072 RPDU2_B2_SSPC_BitErr_17 "SSPC17通断周期自检状态";
CM_ SG_ 2417623072 RPDU2_B2_SSPC_OnOffSta_17 "SSPC17通断状态";
CM_ SG_ 2417623072 RPDU2_B2_SSPC_DianHuErr_17 "SSPC17电弧故障状态";
CM_ SG_ 2417623072 BackUp286 "预留";
CM_ SG_ 2417557536 RPDU2_B2_SSPC_I_Load_16 "SSPC16通道电流";
CM_ SG_ 2417557536 RPDU2_B2_SSPC_TripSta_16 "SSPC16跳闸状态";
CM_ SG_ 2417557536 RPDU2_B2_SSPC_BitErr_16 "SSPC16通断周期自检状态";
CM_ SG_ 2417557536 RPDU2_B2_SSPC_OnOffSta_16 "SSPC16通断状态";
CM_ SG_ 2417557536 RPDU2_B2_SSPC_DianHuErr_16 "SSPC16电弧故障状态";
CM_ SG_ 2417557536 BackUp285 "预留";
CM_ SG_ 2417557536 RPDU2_B2_SSPC_I_Load_15 "SSPC15通道电流";
CM_ SG_ 2417557536 RPDU2_B2_SSPC_TripSta_15 "SSPC15跳闸状态";
CM_ SG_ 2417557536 RPDU2_B2_SSPC_BitErr_15 "SSPC15通断周期自检状态";
CM_ SG_ 2417557536 RPDU2_B2_SSPC_OnOffSta_15 "SSPC15通断状态";
CM_ SG_ 2417557536 RPDU2_B2_SSPC_DianHuErr_15 "SSPC15电弧故障状态";
CM_ SG_ 2417557536 BackUp284 "预留";
CM_ SG_ 2417557536 RPDU2_B2_SSPC_I_Load_14 "SSPC14通道电流";
CM_ SG_ 2417557536 RPDU2_B2_SSPC_TripSta_14 "SSPC14跳闸状态";
CM_ SG_ 2417557536 RPDU2_B2_SSPC_BitErr_14 "SSPC14通断周期自检状态";
CM_ SG_ 2417557536 RPDU2_B2_SSPC_OnOffSta_14 "SSPC14通断状态";
CM_ SG_ 2417557536 RPDU2_B2_SSPC_DianHuErr_14 "SSPC14电弧故障状态";
CM_ SG_ 2417557536 BackUp283 "预留";
CM_ SG_ 2417557536 RPDU2_B2_SSPC_I_Load_13 "SSPC13通道电流";
CM_ SG_ 2417557536 RPDU2_B2_SSPC_TripSta_13 "SSPC13跳闸状态";
CM_ SG_ 2417557536 RPDU2_B2_SSPC_BitErr_13 "SSPC13通断周期自检状态";
CM_ SG_ 2417557536 RPDU2_B2_SSPC_OnOffSta_13 "SSPC13通断状态";
CM_ SG_ 2417557536 RPDU2_B2_SSPC_DianHuErr_13 "SSPC13电弧故障状态";
CM_ SG_ 2417557536 BackUp282 "预留";
CM_ SG_ 2417492000 RPDU2_B2_SSPC_I_Load_12 "SSPC12通道电流";
CM_ SG_ 2417492000 RPDU2_B2_SSPC_TripSta_12 "SSPC12跳闸状态";
CM_ SG_ 2417492000 RPDU2_B2_SSPC_BitErr_12 "SSPC12通断周期自检状态";
CM_ SG_ 2417492000 RPDU2_B2_SSPC_OnOffSta_12 "SSPC12通断状态";
CM_ SG_ 2417492000 RPDU2_B2_SSPC_DianHuErr_12 "SSPC12电弧故障状态";
CM_ SG_ 2417492000 BackUp281 "预留";
CM_ SG_ 2417492000 RPDU2_B2_SSPC_I_Load_11 "SSPC11通道电流";
CM_ SG_ 2417492000 RPDU2_B2_SSPC_TripSta_11 "SSPC11跳闸状态";
CM_ SG_ 2417492000 RPDU2_B2_SSPC_BitErr_11 "SSPC11通断周期自检状态";
CM_ SG_ 2417492000 RPDU2_B2_SSPC_OnOffSta_11 "SSPC11通断状态";
CM_ SG_ 2417492000 RPDU2_B2_SSPC_DianHuErr_11 "SSPC11电弧故障状态";
CM_ SG_ 2417492000 BackUp280 "预留";
CM_ SG_ 2417492000 RPDU2_B2_SSPC_I_Load_10 "SSPC10通道电流";
CM_ SG_ 2417492000 RPDU2_B2_SSPC_TripSta_10 "SSPC10跳闸状态";
CM_ SG_ 2417492000 RPDU2_B2_SSPC_BitErr_10 "SSPC10通断周期自检状态";
CM_ SG_ 2417492000 RPDU2_B2_SSPC_OnOffSta_10 "SSPC10通断状态";
CM_ SG_ 2417492000 RPDU2_B2_SSPC_DianHuErr_10 "SSPC10电弧故障状态";
CM_ SG_ 2417492000 BackUp279 "预留";
CM_ SG_ 2417492000 RPDU2_B2_SSPC_I_Load_09 "SSPC9通道电流";
CM_ SG_ 2417492000 RPDU2_B2_SSPC_TripSta_09 "SSPC9跳闸状态";
CM_ SG_ 2417492000 RPDU2_B2_SSPC_BitErr_09 "SSPC9通断周期自检状态";
CM_ SG_ 2417492000 RPDU2_B2_SSPC_OnOffSta_09 "SSPC9通断状态";
CM_ SG_ 2417492000 RPDU2_B2_SSPC_DianHuErr_09 "SSPC9电弧故障状态";
CM_ SG_ 2417492000 BackUp278 "预留";
CM_ SG_ 2417426464 RPDU2_B2_SSPC_I_Load_08 "SSPC8通道电流";
CM_ SG_ 2417426464 RPDU2_B2_SSPC_TripSta_08 "SSPC8跳闸状态";
CM_ SG_ 2417426464 RPDU2_B2_SSPC_BitErr_08 "SSPC8通断周期自检状态";
CM_ SG_ 2417426464 RPDU2_B2_SSPC_OnOffSta_08 "SSPC8通断状态";
CM_ SG_ 2417426464 RPDU2_B2_SSPC_DianHuErr_08 "SSPC8电弧故障状态";
CM_ SG_ 2417426464 BackUp277 "预留";
CM_ SG_ 2417426464 RPDU2_B2_SSPC_I_Load_07 "SSPC7通道电流";
CM_ SG_ 2417426464 RPDU2_B2_SSPC_TripSta_07 "SSPC7跳闸状态";
CM_ SG_ 2417426464 RPDU2_B2_SSPC_BitErr_07 "SSPC7通断周期自检状态";
CM_ SG_ 2417426464 RPDU2_B2_SSPC_OnOffSta_07 "SSPC7通断状态";
CM_ SG_ 2417426464 RPDU2_B2_SSPC_DianHuErr_07 "SSPC7电弧故障状态";
CM_ SG_ 2417426464 BackUp276 "预留";
CM_ SG_ 2417426464 RPDU2_B2_SSPC_I_Load_06 "SSPC6通道电流";
CM_ SG_ 2417426464 RPDU2_B2_SSPC_TripSta_06 "SSPC6跳闸状态";
CM_ SG_ 2417426464 RPDU2_B2_SSPC_BitErr_06 "SSPC6通断周期自检状态";
CM_ SG_ 2417426464 RPDU2_B2_SSPC_OnOffSta_06 "SSPC6通断状态";
CM_ SG_ 2417426464 RPDU2_B2_SSPC_DianHuErr_06 "SSPC6电弧故障状态";
CM_ SG_ 2417426464 BackUp275 "预留";
CM_ SG_ 2417426464 RPDU2_B2_SSPC_I_Load_05 "SSPC5通道电流";
CM_ SG_ 2417426464 RPDU2_B2_SSPC_TripSta_05 "SSPC5跳闸状态";
CM_ SG_ 2417426464 RPDU2_B2_SSPC_BitErr_05 "SSPC5通断周期自检状态";
CM_ SG_ 2417426464 RPDU2_B2_SSPC_OnOffSta_05 "SSPC5通断状态";
CM_ SG_ 2417426464 RPDU2_B2_SSPC_DianHuErr_05 "SSPC5电弧故障状态";
CM_ SG_ 2417426464 BackUp274 "预留";
CM_ SG_ 2417360928 RPDU2_B2_SSPC_I_Load_04 "SSPC4通道电流";
CM_ SG_ 2417360928 RPDU2_B2_SSPC_TripSta_04 "SSPC4跳闸状态";
CM_ SG_ 2417360928 RPDU2_B2_SSPC_BitErr_04 "SSPC4通断周期自检状态";
CM_ SG_ 2417360928 RPDU2_B2_SSPC_OnOffSta_04 "SSPC4通断状态";
CM_ SG_ 2417360928 RPDU2_B2_SSPC_DianHuErr_04 "SSPC4电弧故障状态";
CM_ SG_ 2417360928 BackUp273 "预留";
CM_ SG_ 2417360928 RPDU2_B2_SSPC_I_Load_03 "SSPC3通道电流";
CM_ SG_ 2417360928 RPDU2_B2_SSPC_TripSta_03 "SSPC3跳闸状态";
CM_ SG_ 2417360928 RPDU2_B2_SSPC_BitErr_03 "SSPC3通断周期自检状态";
CM_ SG_ 2417360928 RPDU2_B2_SSPC_OnOffSta_03 "SSPC3通断状态";
CM_ SG_ 2417360928 RPDU2_B2_SSPC_DianHuErr_03 "SSPC3电弧故障状态";
CM_ SG_ 2417360928 BackUp272 "预留";
CM_ SG_ 2417360928 RPDU2_B2_SSPC_I_Load_02 "SSPC2通道电流";
CM_ SG_ 2417360928 RPDU2_B2_SSPC_TripSta_02 "SSPC2跳闸状态";
CM_ SG_ 2417360928 RPDU2_B2_SSPC_BitErr_02 "SSPC2通断周期自检状态";
CM_ SG_ 2417360928 RPDU2_B2_SSPC_OnOffSta_02 "SSPC2通断状态";
CM_ SG_ 2417360928 RPDU2_B2_SSPC_DianHuErr_02 "SSPC2电弧故障状态";
CM_ SG_ 2417360928 BackUp271 "预留";
CM_ SG_ 2417360928 RPDU2_B2_SSPC_I_Load_01 "SSPC1通道电流";
CM_ SG_ 2417360928 RPDU2_B2_SSPC_TripSta_01 "SSPC1跳闸状态";
CM_ SG_ 2417360928 RPDU2_B2_SSPC_BitErr_01 "SSPC1通断周期自检状态";
CM_ SG_ 2417360928 RPDU2_B2_SSPC_OnOffSta_01 "SSPC1通断状态";
CM_ SG_ 2417360928 RPDU2_B2_SSPC_DianHuErr_01 "SSPC1电弧故障状态";
CM_ SG_ 2417360928 BackUp270 "预留";
CM_ SG_ 2417295392 BackUp269 "预留";
CM_ SG_ 2417295392 BackUp268 "预留";
CM_ SG_ 2417295392 BackUp267 "预留";
CM_ SG_ 2417295392 BackUp266 "预留";
CM_ SG_ 2417295392 RPDU2_B1_SSPC_I_Load_18 "SSPC18通道电流";
CM_ SG_ 2417295392 RPDU2_B1_SSPC_TripSta_18 "SSPC18跳闸状态";
CM_ SG_ 2417295392 RPDU2_B1_SSPC_BitErr_18 "SSPC18通断周期自检状态";
CM_ SG_ 2417295392 RPDU2_B1_SSPC_OnOffSta_18 "SSPC18通断状态";
CM_ SG_ 2417295392 RPDU2_B1_SSPC_DianHuErr_18 "SSPC18电弧故障状态";
CM_ SG_ 2417295392 BackUp265 "预留";
CM_ SG_ 2417295392 RPDU2_B1_SSPC_I_Load_17 "SSPC17通道电流";
CM_ SG_ 2417295392 RPDU2_B1_SSPC_TripSta_17 "SSPC17跳闸状态";
CM_ SG_ 2417295392 RPDU2_B1_SSPC_BitErr_17 "SSPC17通断周期自检状态";
CM_ SG_ 2417295392 RPDU2_B1_SSPC_OnOffSta_17 "SSPC17通断状态";
CM_ SG_ 2417295392 RPDU2_B1_SSPC_DianHuErr_17 "SSPC17电弧故障状态";
CM_ SG_ 2417295392 BackUp264 "预留";
CM_ SG_ 2417229856 RPDU2_B1_SSPC_I_Load_16 "SSPC16通道电流";
CM_ SG_ 2417229856 RPDU2_B1_SSPC_TripSta_16 "SSPC16跳闸状态";
CM_ SG_ 2417229856 RPDU2_B1_SSPC_BitErr_16 "SSPC16通断周期自检状态";
CM_ SG_ 2417229856 RPDU2_B1_SSPC_OnOffSta_16 "SSPC16通断状态";
CM_ SG_ 2417229856 RPDU2_B1_SSPC_DianHuErr_16 "SSPC16电弧故障状态";
CM_ SG_ 2417229856 BackUp263 "预留";
CM_ SG_ 2417229856 RPDU2_B1_SSPC_I_Load_15 "SSPC15通道电流";
CM_ SG_ 2417229856 RPDU2_B1_SSPC_TripSta_15 "SSPC15跳闸状态";
CM_ SG_ 2417229856 RPDU2_B1_SSPC_BitErr_15 "SSPC15通断周期自检状态";
CM_ SG_ 2417229856 RPDU2_B1_SSPC_OnOffSta_15 "SSPC15通断状态";
CM_ SG_ 2417229856 RPDU2_B1_SSPC_DianHuErr_15 "SSPC15电弧故障状态";
CM_ SG_ 2417229856 BackUp262 "预留";
CM_ SG_ 2417229856 RPDU2_B1_SSPC_I_Load_14 "SSPC14通道电流";
CM_ SG_ 2417229856 RPDU2_B1_SSPC_TripSta_14 "SSPC14跳闸状态";
CM_ SG_ 2417229856 RPDU2_B1_SSPC_BitErr_14 "SSPC14通断周期自检状态";
CM_ SG_ 2417229856 RPDU2_B1_SSPC_OnOffSta_14 "SSPC14通断状态";
CM_ SG_ 2417229856 RPDU2_B1_SSPC_DianHuErr_14 "SSPC14电弧故障状态";
CM_ SG_ 2417229856 BackUp261 "预留";
CM_ SG_ 2417229856 RPDU2_B1_SSPC_I_Load_13 "SSPC13通道电流";
CM_ SG_ 2417229856 RPDU2_B1_SSPC_TripSta_13 "SSPC13跳闸状态";
CM_ SG_ 2417229856 RPDU2_B1_SSPC_BitErr_13 "SSPC13通断周期自检状态";
CM_ SG_ 2417229856 RPDU2_B1_SSPC_OnOffSta_13 "SSPC13通断状态";
CM_ SG_ 2417229856 RPDU2_B1_SSPC_DianHuErr_13 "SSPC13电弧故障状态";
CM_ SG_ 2417229856 BackUp260 "预留";
CM_ SG_ 2417164320 RPDU2_B1_SSPC_I_Load_12 "SSPC12通道电流";
CM_ SG_ 2417164320 RPDU2_B1_SSPC_TripSta_12 "SSPC12跳闸状态";
CM_ SG_ 2417164320 RPDU2_B1_SSPC_BitErr_12 "SSPC12通断周期自检状态";
CM_ SG_ 2417164320 RPDU2_B1_SSPC_OnOffSta_12 "SSPC12通断状态";
CM_ SG_ 2417164320 RPDU2_B1_SSPC_DianHuErr_12 "SSPC12电弧故障状态";
CM_ SG_ 2417164320 BackUp259 "预留";
CM_ SG_ 2417164320 RPDU2_B1_SSPC_I_Load_11 "SSPC11通道电流";
CM_ SG_ 2417164320 RPDU2_B1_SSPC_TripSta_11 "SSPC11跳闸状态";
CM_ SG_ 2417164320 RPDU2_B1_SSPC_BitErr_11 "SSPC11通断周期自检状态";
CM_ SG_ 2417164320 RPDU2_B1_SSPC_OnOffSta_11 "SSPC11通断状态";
CM_ SG_ 2417164320 RPDU2_B1_SSPC_DianHuErr_11 "SSPC11电弧故障状态";
CM_ SG_ 2417164320 BackUp258 "预留";
CM_ SG_ 2417164320 RPDU2_B1_SSPC_I_Load_10 "SSPC10通道电流";
CM_ SG_ 2417164320 RPDU2_B1_SSPC_TripSta_10 "SSPC10跳闸状态";
CM_ SG_ 2417164320 RPDU2_B1_SSPC_BitErr_10 "SSPC10通断周期自检状态";
CM_ SG_ 2417164320 RPDU2_B1_SSPC_OnOffSta_10 "SSPC10通断状态";
CM_ SG_ 2417164320 RPDU2_B1_SSPC_DianHuErr_10 "SSPC10电弧故障状态";
CM_ SG_ 2417164320 BackUp257 "预留";
CM_ SG_ 2417164320 RPDU2_B1_SSPC_I_Load_09 "SSPC9通道电流";
CM_ SG_ 2417164320 RPDU2_B1_SSPC_TripSta_09 "SSPC9跳闸状态";
CM_ SG_ 2417164320 RPDU2_B1_SSPC_BitErr_09 "SSPC9通断周期自检状态";
CM_ SG_ 2417164320 RPDU2_B1_SSPC_OnOffSta_09 "SSPC9通断状态";
CM_ SG_ 2417164320 RPDU2_B1_SSPC_DianHuErr_09 "SSPC9电弧故障状态";
CM_ SG_ 2417164320 BackUp256 "预留";
CM_ SG_ 2417098784 RPDU2_B1_SSPC_I_Load_08 "SSPC8通道电流";
CM_ SG_ 2417098784 RPDU2_B1_SSPC_TripSta_08 "SSPC8跳闸状态";
CM_ SG_ 2417098784 RPDU2_B1_SSPC_BitErr_08 "SSPC8通断周期自检状态";
CM_ SG_ 2417098784 RPDU2_B1_SSPC_OnOffSta_08 "SSPC8通断状态";
CM_ SG_ 2417098784 RPDU2_B1_SSPC_DianHuErr_08 "SSPC8电弧故障状态";
CM_ SG_ 2417098784 BackUp255 "预留";
CM_ SG_ 2417098784 RPDU2_B1_SSPC_I_Load_07 "SSPC7通道电流";
CM_ SG_ 2417098784 RPDU2_B1_SSPC_TripSta_07 "SSPC7跳闸状态";
CM_ SG_ 2417098784 RPDU2_B1_SSPC_BitErr_07 "SSPC7通断周期自检状态";
CM_ SG_ 2417098784 RPDU2_B1_SSPC_OnOffSta_07 "SSPC7通断状态";
CM_ SG_ 2417098784 RPDU2_B1_SSPC_DianHuErr_07 "SSPC7电弧故障状态";
CM_ SG_ 2417098784 BackUp254 "预留";
CM_ SG_ 2417098784 RPDU2_B1_SSPC_I_Load_06 "SSPC6通道电流";
CM_ SG_ 2417098784 RPDU2_B1_SSPC_TripSta_06 "SSPC6跳闸状态";
CM_ SG_ 2417098784 RPDU2_B1_SSPC_BitErr_06 "SSPC6通断周期自检状态";
CM_ SG_ 2417098784 RPDU2_B1_SSPC_OnOffSta_06 "SSPC6通断状态";
CM_ SG_ 2417098784 RPDU2_B1_SSPC_DianHuErr_06 "SSPC6电弧故障状态";
CM_ SG_ 2417098784 BackUp253 "预留";
CM_ SG_ 2417098784 RPDU2_B1_SSPC_I_Load_05 "SSPC5通道电流";
CM_ SG_ 2417098784 RPDU2_B1_SSPC_TripSta_05 "SSPC5跳闸状态";
CM_ SG_ 2417098784 RPDU2_B1_SSPC_BitErr_05 "SSPC5通断周期自检状态";
CM_ SG_ 2417098784 RPDU2_B1_SSPC_OnOffSta_05 "SSPC5通断状态";
CM_ SG_ 2417098784 RPDU2_B1_SSPC_DianHuErr_05 "SSPC5电弧故障状态";
CM_ SG_ 2417098784 BackUp252 "预留";
CM_ SG_ 2417033248 RPDU2_B1_SSPC_I_Load_04 "SSPC4通道电流";
CM_ SG_ 2417033248 RPDU2_B1_SSPC_TripSta_04 "SSPC4跳闸状态";
CM_ SG_ 2417033248 RPDU2_B1_SSPC_BitErr_04 "SSPC4通断周期自检状态";
CM_ SG_ 2417033248 RPDU2_B1_SSPC_OnOffSta_04 "SSPC4通断状态";
CM_ SG_ 2417033248 RPDU2_B1_SSPC_DianHuErr_04 "SSPC4电弧故障状态";
CM_ SG_ 2417033248 BackUp251 "预留";
CM_ SG_ 2417033248 RPDU2_B1_SSPC_I_Load_03 "SSPC3通道电流";
CM_ SG_ 2417033248 RPDU2_B1_SSPC_TripSta_03 "SSPC3跳闸状态";
CM_ SG_ 2417033248 RPDU2_B1_SSPC_BitErr_03 "SSPC3通断周期自检状态";
CM_ SG_ 2417033248 RPDU2_B1_SSPC_OnOffSta_03 "SSPC3通断状态";
CM_ SG_ 2417033248 RPDU2_B1_SSPC_DianHuErr_03 "SSPC3电弧故障状态";
CM_ SG_ 2417033248 BackUp250 "预留";
CM_ SG_ 2417033248 RPDU2_B1_SSPC_I_Load_02 "SSPC2通道电流";
CM_ SG_ 2417033248 RPDU2_B1_SSPC_TripSta_02 "SSPC2跳闸状态";
CM_ SG_ 2417033248 RPDU2_B1_SSPC_BitErr_02 "SSPC2通断周期自检状态";
CM_ SG_ 2417033248 RPDU2_B1_SSPC_OnOffSta_02 "SSPC2通断状态";
CM_ SG_ 2417033248 RPDU2_B1_SSPC_DianHuErr_02 "SSPC2电弧故障状态";
CM_ SG_ 2417033248 BackUp249 "预留";
CM_ SG_ 2417033248 RPDU2_B1_SSPC_I_Load_01 "SSPC1通道电流";
CM_ SG_ 2417033248 RPDU2_B1_SSPC_TripSta_01 "SSPC1跳闸状态";
CM_ SG_ 2417033248 RPDU2_B1_SSPC_BitErr_01 "SSPC1通断周期自检状态";
CM_ SG_ 2417033248 RPDU2_B1_SSPC_OnOffSta_01 "SSPC1通断状态";
CM_ SG_ 2417033248 RPDU2_B1_SSPC_DianHuErr_01 "SSPC1电弧故障状态";
CM_ SG_ 2417033248 BackUp248 "预留";
CM_ SG_ 2416967712 BackUp247 "预留";
CM_ SG_ 2416967712 R_TouChuan_DCDC_DDCSta "DDC 接触器状态信号";
CM_ SG_ 2416967712 R_TouChuan_DCDC_DDCCtrl "DDC 接触器控制信号";
CM_ SG_ 2416967712 R_TouChuan_DCDC_FanWarn "风扇异常告警";
CM_ SG_ 2416967712 R_TouChuan_DCDC_ConnStaErr "输出接触器状态故障";
CM_ SG_ 2416967712 R_TouChuan_DCDC_HardOutOverErr "硬件输出过压故障";
CM_ SG_ 2416967712 R_TouChuan_DCDC_TOverErr "过温故障";
CM_ SG_ 2416967712 R_TouChuan_DCDC_TOverWarn "过温告警";
CM_ SG_ 2416967712 R_TouChuan_DCDC_OutILimitErr "输出限流故障";
CM_ SG_ 2416967712 R_TouChuan_DCDC_OutIOverErr "输出过流故障";
CM_ SG_ 2416967712 R_TouChuan_DCDC_OutPowOverErr "输出过压故障";
CM_ SG_ 2416967712 R_TouChuan_DCDC_OutPowLowErr "输出欠压故障";
CM_ SG_ 2416967712 R_TouChuan_DCDC_OutPowLowWarn "输出电压低告警";
CM_ SG_ 2416967712 R_TouChuan_DCDC_InPowLowErr "输入欠压故障";
CM_ SG_ 2416902176 BackUp246 "预留";
CM_ SG_ 2416902176 BackUp245 "预留";
CM_ SG_ 2416902176 BackUp244 "预留";
CM_ SG_ 2416902176 R_TouChuan_DCDC_12_2U "二次电源12V-2";
CM_ SG_ 2416836640 R_TouChuan_DCDC_12_1U "二次电源12V-1";
CM_ SG_ 2416836640 R_TouChuan_DCDC_5_U "二次电源5V电压";
CM_ SG_ 2416836640 R_TouChuan_DCDC_270To28_U "270V转28V电压";
CM_ SG_ 2416836640 R_TouChuan_DCDC_In_28U "28V输入电压";
CM_ SG_ 2416771104 R_TouChuan_DCDC_T "产品内部温度";
CM_ SG_ 2416771104 R_TouChuan_DCDC_Out_I "输出电流";
CM_ SG_ 2416771104 R_TouChuan_DCDC_Out_U "输出电压";
CM_ SG_ 2416771104 R_TouChuan_DCDC_In_U "输入电压";
CM_ SG_ 2416705568 R_DCDC_Ver_D "版本号段D";
CM_ SG_ 2416705568 R_DCDC_Ver_C "版本号段C";
CM_ SG_ 2416705568 R_DCDC_Ver_B "版本号段B";
CM_ SG_ 2416705568 R_DCDC_Ver_A "版本号段A";
CM_ SG_ 2416574496 R_MCU_Ver_Day "日期";
CM_ SG_ 2416574496 R_MCU_Ver_Month "月份";
CM_ SG_ 2416574496 R_MCU_Ver_Year "年份";
CM_ SG_ 2416574496 R_MCU_Ver_D "版本号段D";
CM_ SG_ 2416574496 R_MCU_Ver_C "版本号段C";
CM_ SG_ 2416574496 R_MCU_Ver_B "版本号段B";
CM_ SG_ 2416574496 R_MCU_Ver_A "版本号段A";
CM_ SG_ 2416508960 BackUp243 "预留";
CM_ SG_ 2416508960 R_DuanLuQi_Sta_49 "断路器49状态";
CM_ SG_ 2416508960 R_DuanLuQi_Sta_48 "断路器48状态";
CM_ SG_ 2416508960 R_DuanLuQi_Sta_47 "断路器47状态";
CM_ SG_ 2416508960 R_DuanLuQi_Sta_46 "断路器46状态";
CM_ SG_ 2416508960 R_DuanLuQi_Sta_45 "断路器45状态";
CM_ SG_ 2416508960 R_DuanLuQi_Sta_44 "断路器44状态";
CM_ SG_ 2416508960 R_DuanLuQi_Sta_43 "断路器43状态";
CM_ SG_ 2416508960 R_DuanLuQi_Sta_42 "断路器42状态";
CM_ SG_ 2416508960 R_DuanLuQi_Sta_41 "断路器41状态";
CM_ SG_ 2416508960 R_DuanLuQi_Sta_40 "断路器40状态";
CM_ SG_ 2416508960 R_DuanLuQi_Sta_39 "断路器39状态";
CM_ SG_ 2416508960 R_DuanLuQi_Sta_38 "断路器38状态";
CM_ SG_ 2416508960 R_DuanLuQi_Sta_37 "断路器37状态";
CM_ SG_ 2416508960 R_DuanLuQi_Sta_36 "断路器36状态";
CM_ SG_ 2416508960 R_DuanLuQi_Sta_35 "断路器35状态";
CM_ SG_ 2416508960 R_DuanLuQi_Sta_34 "断路器34状态";
CM_ SG_ 2416508960 R_DuanLuQi_Sta_33 "断路器33状态";
CM_ SG_ 2416508960 R_DuanLuQi_Sta_32 "断路器32状态";
CM_ SG_ 2416508960 R_DuanLuQi_Sta_31 "断路器31状态";
CM_ SG_ 2416508960 R_DuanLuQi_Sta_30 "断路器30状态";
CM_ SG_ 2416508960 R_DuanLuQi_Sta_29 "断路器29状态";
CM_ SG_ 2416508960 R_DuanLuQi_Sta_28 "断路器28状态";
CM_ SG_ 2416508960 R_DuanLuQi_Sta_27 "断路器27状态";
CM_ SG_ 2416508960 R_DuanLuQi_Sta_26 "断路器26状态";
CM_ SG_ 2416508960 R_DuanLuQi_Sta_25 "断路器25状态";
CM_ SG_ 2416508960 R_DuanLuQi_Sta_24 "断路器24状态";
CM_ SG_ 2416508960 R_DuanLuQi_Sta_23 "断路器23状态";
CM_ SG_ 2416508960 R_DuanLuQi_Sta_22 "断路器22状态";
CM_ SG_ 2416508960 R_DuanLuQi_Sta_21 "断路器21状态";
CM_ SG_ 2416508960 R_DuanLuQi_Sta_20 "断路器20状态";
CM_ SG_ 2416508960 R_DuanLuQi_Sta_19 "断路器19状态";
CM_ SG_ 2416508960 R_DuanLuQi_Sta_18 "断路器18状态";
CM_ SG_ 2416508960 R_DuanLuQi_Sta_17 "断路器17状态";
CM_ SG_ 2416508960 R_DuanLuQi_Sta_16 "断路器16状态";
CM_ SG_ 2416508960 R_DuanLuQi_Sta_15 "断路器15状态";
CM_ SG_ 2416508960 R_DuanLuQi_Sta_14 "断路器14状态";
CM_ SG_ 2416508960 R_DuanLuQi_Sta_13 "断路器13状态";
CM_ SG_ 2416508960 R_DuanLuQi_Sta_12 "断路器12状态";
CM_ SG_ 2416508960 R_DuanLuQi_Sta_11 "断路器11状态";
CM_ SG_ 2416508960 R_DuanLuQi_Sta_10 "断路器10状态";
CM_ SG_ 2416508960 R_DuanLuQi_Sta_09 "断路器9状态";
CM_ SG_ 2416508960 R_DuanLuQi_Sta_08 "断路器8状态";
CM_ SG_ 2416508960 R_DuanLuQi_Sta_07 "断路器7状态";
CM_ SG_ 2416508960 R_DuanLuQi_Sta_06 "断路器6状态";
CM_ SG_ 2416508960 R_DuanLuQi_Sta_05 "断路器5状态";
CM_ SG_ 2416508960 R_DuanLuQi_Sta_04 "断路器4状态";
CM_ SG_ 2416508960 R_DuanLuQi_Sta_03 "断路器3状态";
CM_ SG_ 2416508960 R_DuanLuQi_Sta_02 "断路器2状态";
CM_ SG_ 2416508960 R_DuanLuQi_Sta_01 "断路器1状态";
CM_ SG_ 2416443424 BackUp242 "预留";
CM_ SG_ 2416443424 R_RE28IOver "R/E 28V DC汇流条1转换电流状态";
CM_ SG_ 2416443424 R_RL28IOver "R/L 28V DC汇流条2转换电流状态";
CM_ SG_ 2416443424 R_HLT281IOver "R 28 DC汇流条1输入电流状态";
CM_ SG_ 2416443424 R_HLT282IOver "R 28 DC汇流条2输入电流状态";
CM_ SG_ 2416443424 R_RE270IOver "R/E 270 DC汇流条转换电流状态";
CM_ SG_ 2416443424 BackUp241 "预留";
CM_ SG_ 2416443424 R_HLT270IOver "R 270 DC汇流条输入电流状态";
CM_ SG_ 2416443424 BackUp240 "预留";
CM_ SG_ 2416443424 R_HOTBBUSta "HOTBB汇流条电压状态";
CM_ SG_ 2416443424 R_HLT281USta "R 28 DC汇流条1电压状态";
CM_ SG_ 2416443424 R_HLT282USta "R 28 DC汇流条2电压状态";
CM_ SG_ 2416443424 R_DCDC28OutUSta "R 270-28 DCDC变换器输出电源电压状态";
CM_ SG_ 2416443424 R_DCDC270InUSta "R 270-28 DCDC变换器输入电源电压状态";
CM_ SG_ 2416443424 R_HLT270USta "R 270 DC汇流条电压状态";
CM_ SG_ 2416443424 R_Batter270USta "R 270电池输入电压状态";
CM_ SG_ 2416443424 BackUp239 "预留";
CM_ SG_ 2416443424 R_Heart_BIT "主备心跳自检";
CM_ SG_ 2416443424 R_ZBUART_BIT "主备通讯自检";
CM_ SG_ 2416443424 R_ADCIN_BIT "模拟量采集电路自检";
CM_ SG_ 2416443424 R_GpioIN_BIT "离散量采集电路自检";
CM_ SG_ 2416443424 R_Flash_BIT "存储电路自检";
CM_ SG_ 2416443424 R_UART_BIT "RS422总线自检";
CM_ SG_ 2416443424 R_IntCAN2_BIT "内部CAN总线2自检";
CM_ SG_ 2416443424 R_IntCAN1_BIT "内部CAN总线1自检";
CM_ SG_ 2416443424 R_ExtCAN_BIT "外部CAN总线自检";
CM_ SG_ 2416443424 R_CPU_BIT "主处理器自检";
CM_ SG_ 2416443424 R_Pow_BIT "电源电路自检";
CM_ SG_ 2416377888 RTSSR_STA "RTSSR状态";
CM_ SG_ 2416377888 EBC_STA_R "EBC接触器状态";
CM_ SG_ 2416377888 BackUp238 "预留";
CM_ SG_ 2416377888 RETC1_STA "RETC1接触器状态";
CM_ SG_ 2416377888 BTC1_STA "BTC1接触器状态";
CM_ SG_ 2416377888 RDC2_STA "RDC2接触器状态";
CM_ SG_ 2416377888 RETR_STA "RETR接触器状态";
CM_ SG_ 2416377888 RBC_STA "RBC接触器状态";
CM_ SG_ 2416312352 BackUp237 "预留";
CM_ SG_ 2416312352 BackUp236 "预留";
CM_ SG_ 2416312352 RTSSR_U "RTSSR后端电压";
CM_ SG_ 2416312352 RE28_HLT_ZH_U "R/E 28V DC汇流条1转换电压";
CM_ SG_ 2416246816 RL28_HLT2_ZH_U "R/L 28V DC汇流条2转换电压";
CM_ SG_ 2416246816 R28_HLT2_U "R 28 DC汇流条2电压";
CM_ SG_ 2416246816 R28_HLT1_U "R 28 DC汇流条1电压";
CM_ SG_ 2416246816 R_DCDC_Out_U "R 270-28 DCDC变换器输出电源电压";
CM_ SG_ 2416181280 R_DCDC_In_U "R 270-28 DCDC变换器输入电源电压";
CM_ SG_ 2416181280 RE270_HLT_ZH_U "R/E 270 DC汇流条转换电压";
CM_ SG_ 2416181280 BackUp235 "预留";
CM_ SG_ 2416181280 R270_HLT_U "R 270 DC汇流条电压";
CM_ SG_ 2416115744 R270_Batter_U "R 270电池输入电压";
CM_ SG_ 2416115744 R_HOTBB_HLT_U "HOTBB汇流条电压";
CM_ SG_ 2416115744 R_E28_HLT_U "E 28 DC汇流条电压";
CM_ SG_ 2416115744 R_E270_HLT_U "E 270 DC汇流条电压";
CM_ SG_ 2416050208 RTSSR_I "RTSSR电流";
CM_ SG_ 2416050208 RE28_HLT1_ZH_I "R/E 28V DC汇流条转换电流1";
CM_ SG_ 2416050208 RL28_HLT2_ZH_I "R/L 28V DC汇流条转换电流2";
CM_ SG_ 2416050208 R28_HLT2_In_I "R 28 DC汇流条2输入电流";
CM_ SG_ 2415984672 R28_HLT1_In_I "R 28 DC汇流条1输入电流";
CM_ SG_ 2415984672 RE270_HLT_ZH_I "R/E 270 DC汇流条转换电流";
CM_ SG_ 2415984672 BackUp234 "预留";
CM_ SG_ 2415984672 R270_HLT_In_I "R 270 DC汇流条输入电流";
CM_ SG_ 2421178384 BackUp233 "预留";
CM_ SG_ 2421178384 BackUp232 "预留";
CM_ SG_ 2421178384 BackUp231 "预留";
CM_ SG_ 2421178384 BackUp230 "预留";
CM_ SG_ 2421178384 LETC1_Ctrl "LETC1接触器控制信号";
CM_ SG_ 2421178384 LETR_Ctrl "LETR接触器控制信号";
CM_ SG_ 2421178384 LETR_STA_ChongGou "LETR接触器状态";
CM_ SG_ 2421178384 LETC1_ChongGou_ChangJing "LETC1控制时的场景";
CM_ SG_ 2421178384 LETC1_STA_ChongGou "LETC1接触器状态";
CM_ SG_ 2421178384 BTC2_STA_ChongGou "BTC2接触器状态";
CM_ SG_ 2421178384 BackUp229 "预留";
CM_ SG_ 2421178384 BTC2_ReSta "BTC2 接触器辅助触点状态";
CM_ SG_ 2421178384 BackUp228 "预留";
CM_ SG_ 2421178384 LTR_Ctrl "LTR接触器控制信号";
CM_ SG_ 2421178384 LDC2_Ctrl "LDC2接触器控制信号";
CM_ SG_ 2421178384 LDC1_Ctrl "LDC1接触器控制信号";
CM_ SG_ 2421178384 BTC2_ChongGou_ChangJing "BTC2接触器控制时的场景";
CM_ SG_ 2421178384 BackUp227 "预留";
CM_ SG_ 2421178384 LETC1_ReSta "LETC1接触器辅助触点状态";
CM_ SG_ 2421178384 L_HLT282IOver_ChongGou "L28DC汇流条2输入电流过流";
CM_ SG_ 2421178384 L_HLT281IOver_ChongGou "L28DC汇流条1输入电流过流";
CM_ SG_ 2421178384 L_HLT270IOver_ChongGou "L270DC汇流条输入电流过流";
CM_ SG_ 2420244496 RPDU3_Index "序号";
CM_ SG_ 2420244496 BackUp226 "预留";
CM_ SG_ 2420244496 RPDU3_Time "时间";
CM_ SG_ 2420244496 RPDU3_SSPC_Ver "SSPC模块软件版本号";
CM_ SG_ 2420244496 RPDU3_PS_Ver "PS软件版本号";
CM_ SG_ 2420244496 BackUp225 "预留";
CM_ SG_ 2420244496 RPDU3_Hard_Num "硬件修改号";
CM_ SG_ 2420178960 BackUp224 "预留";
CM_ SG_ 2420178960 BackUp223 "预留";
CM_ SG_ 2420178960 RPDU3_B6_SSPC_I_Load_07 "SSPC7通道电流";
CM_ SG_ 2420178960 RPDU3_B6_SSPC_TripSta_07 "SSPC7跳闸状态";
CM_ SG_ 2420178960 RPDU3_B6_SSPC_BitErr_07 "SSPC7通断周期自检状态";
CM_ SG_ 2420178960 RPDU3_B6_SSPC_OnOffSta_07 "SSPC7通断状态";
CM_ SG_ 2420178960 RPDU3_B6_SSPC_DianHuErr_07 "SSPC7电弧故障状态";
CM_ SG_ 2420178960 BackUp222 "预留";
CM_ SG_ 2420178960 RPDU3_B6_SSPC_I_Load_06 "SSPC6通道电流";
CM_ SG_ 2420178960 RPDU3_B6_SSPC_TripSta_06 "SSPC6跳闸状态";
CM_ SG_ 2420178960 RPDU3_B6_SSPC_BitErr_06 "SSPC6通断周期自检状态";
CM_ SG_ 2420178960 RPDU3_B6_SSPC_OnOffSta_06 "SSPC6通断状态";
CM_ SG_ 2420178960 RPDU3_B6_SSPC_DianHuErr_06 "SSPC6电弧故障状态";
CM_ SG_ 2420178960 BackUp221 "预留";
CM_ SG_ 2420178960 RPDU3_B6_SSPC_I_Load_05 "SSPC5通道电流";
CM_ SG_ 2420178960 RPDU3_B6_SSPC_TripSta_05 "SSPC5跳闸状态";
CM_ SG_ 2420178960 RPDU3_B6_SSPC_BitErr_05 "SSPC5通断周期自检状态";
CM_ SG_ 2420178960 RPDU3_B6_SSPC_OnOffSta_05 "SSPC5通断状态";
CM_ SG_ 2420178960 RPDU3_B6_SSPC_DianHuErr_05 "SSPC5电弧故障状态";
CM_ SG_ 2420178960 BackUp220 "预留";
CM_ SG_ 2420113424 RPDU3_B6_SSPC_I_Load_04 "SSPC4通道电流";
CM_ SG_ 2420113424 RPDU3_B6_SSPC_TripSta_04 "SSPC4跳闸状态";
CM_ SG_ 2420113424 RPDU3_B6_SSPC_BitErr_04 "SSPC4通断周期自检状态";
CM_ SG_ 2420113424 RPDU3_B6_SSPC_OnOffSta_04 "SSPC4通断状态";
CM_ SG_ 2420113424 RPDU3_B6_SSPC_DianHuErr_04 "SSPC4电弧故障状态";
CM_ SG_ 2420113424 BackUp219 "预留";
CM_ SG_ 2420113424 RPDU3_B6_SSPC_I_Load_03 "SSPC3通道电流";
CM_ SG_ 2420113424 RPDU3_B6_SSPC_TripSta_03 "SSPC3跳闸状态";
CM_ SG_ 2420113424 RPDU3_B6_SSPC_BitErr_03 "SSPC3通断周期自检状态";
CM_ SG_ 2420113424 RPDU3_B6_SSPC_OnOffSta_03 "SSPC3通断状态";
CM_ SG_ 2420113424 RPDU3_B6_SSPC_DianHuErr_03 "SSPC3电弧故障状态";
CM_ SG_ 2420113424 BackUp218 "预留";
CM_ SG_ 2420113424 RPDU3_B6_SSPC_I_Load_02 "SSPC2通道电流";
CM_ SG_ 2420113424 RPDU3_B6_SSPC_TripSta_02 "SSPC2跳闸状态";
CM_ SG_ 2420113424 RPDU3_B6_SSPC_BitErr_02 "SSPC2通断周期自检状态";
CM_ SG_ 2420113424 RPDU3_B6_SSPC_OnOffSta_02 "SSPC2通断状态";
CM_ SG_ 2420113424 RPDU3_B6_SSPC_DianHuErr_02 "SSPC2电弧故障状态";
CM_ SG_ 2420113424 BackUp217 "预留";
CM_ SG_ 2420113424 RPDU3_B6_SSPC_I_Load_01 "SSPC1通道电流";
CM_ SG_ 2420113424 RPDU3_B6_SSPC_TripSta_01 "SSPC1跳闸状态";
CM_ SG_ 2420113424 RPDU3_B6_SSPC_BitErr_01 "SSPC1通断周期自检状态";
CM_ SG_ 2420113424 RPDU3_B6_SSPC_OnOffSta_01 "SSPC1通断状态";
CM_ SG_ 2420113424 RPDU3_B6_SSPC_DianHuErr_01 "SSPC1电弧故障状态";
CM_ SG_ 2420113424 BackUp216 "预留";
CM_ SG_ 2420047888 BackUp215 "预留";
CM_ SG_ 2420047888 BackUp214 "预留";
CM_ SG_ 2420047888 RPDU3_B5_SSPC_I_Load_07 "SSPC7通道电流";
CM_ SG_ 2420047888 RPDU3_B5_SSPC_TripSta_07 "SSPC7跳闸状态";
CM_ SG_ 2420047888 RPDU3_B5_SSPC_BitErr_07 "SSPC7通断周期自检状态";
CM_ SG_ 2420047888 RPDU3_B5_SSPC_OnOffSta_07 "SSPC7通断状态";
CM_ SG_ 2420047888 RPDU3_B5_SSPC_DianHuErr_07 "SSPC7电弧故障状态";
CM_ SG_ 2420047888 BackUp213 "预留";
CM_ SG_ 2420047888 RPDU3_B5_SSPC_I_Load_06 "SSPC6通道电流";
CM_ SG_ 2420047888 RPDU3_B5_SSPC_TripSta_06 "SSPC6跳闸状态";
CM_ SG_ 2420047888 RPDU3_B5_SSPC_BitErr_06 "SSPC6通断周期自检状态";
CM_ SG_ 2420047888 RPDU3_B5_SSPC_OnOffSta_06 "SSPC6通断状态";
CM_ SG_ 2420047888 RPDU3_B5_SSPC_DianHuErr_06 "SSPC6电弧故障状态";
CM_ SG_ 2420047888 BackUp212 "预留";
CM_ SG_ 2420047888 RPDU3_B5_SSPC_I_Load_05 "SSPC5通道电流";
CM_ SG_ 2420047888 RPDU3_B5_SSPC_TripSta_05 "SSPC5跳闸状态";
CM_ SG_ 2420047888 RPDU3_B5_SSPC_BitErr_05 "SSPC5通断周期自检状态";
CM_ SG_ 2420047888 RPDU3_B5_SSPC_OnOffSta_05 "SSPC5通断状态";
CM_ SG_ 2420047888 RPDU3_B5_SSPC_DianHuErr_05 "SSPC5电弧故障状态";
CM_ SG_ 2420047888 BackUp211 "预留";
CM_ SG_ 2419982352 RPDU3_B5_SSPC_I_Load_04 "SSPC4通道电流";
CM_ SG_ 2419982352 RPDU3_B5_SSPC_TripSta_04 "SSPC4跳闸状态";
CM_ SG_ 2419982352 RPDU3_B5_SSPC_BitErr_04 "SSPC4通断周期自检状态";
CM_ SG_ 2419982352 RPDU3_B5_SSPC_OnOffSta_04 "SSPC4通断状态";
CM_ SG_ 2419982352 RPDU3_B5_SSPC_DianHuErr_04 "SSPC4电弧故障状态";
CM_ SG_ 2419982352 BackUp210 "预留";
CM_ SG_ 2419982352 RPDU3_B5_SSPC_I_Load_03 "SSPC3通道电流";
CM_ SG_ 2419982352 RPDU3_B5_SSPC_TripSta_03 "SSPC3跳闸状态";
CM_ SG_ 2419982352 RPDU3_B5_SSPC_BitErr_03 "SSPC3通断周期自检状态";
CM_ SG_ 2419982352 RPDU3_B5_SSPC_OnOffSta_03 "SSPC3通断状态";
CM_ SG_ 2419982352 RPDU3_B5_SSPC_DianHuErr_03 "SSPC3电弧故障状态";
CM_ SG_ 2419982352 BackUp209 "预留";
CM_ SG_ 2419982352 RPDU3_B5_SSPC_I_Load_02 "SSPC2通道电流";
CM_ SG_ 2419982352 RPDU3_B5_SSPC_TripSta_02 "SSPC2跳闸状态";
CM_ SG_ 2419982352 RPDU3_B5_SSPC_BitErr_02 "SSPC2通断周期自检状态";
CM_ SG_ 2419982352 RPDU3_B5_SSPC_OnOffSta_02 "SSPC2通断状态";
CM_ SG_ 2419982352 RPDU3_B5_SSPC_DianHuErr_02 "SSPC2电弧故障状态";
CM_ SG_ 2419982352 BackUp208 "预留";
CM_ SG_ 2419982352 RPDU3_B5_SSPC_I_Load_01 "SSPC1通道电流";
CM_ SG_ 2419982352 RPDU3_B5_SSPC_TripSta_01 "SSPC1跳闸状态";
CM_ SG_ 2419982352 RPDU3_B5_SSPC_BitErr_01 "SSPC1通断周期自检状态";
CM_ SG_ 2419982352 RPDU3_B5_SSPC_OnOffSta_01 "SSPC1通断状态";
CM_ SG_ 2419982352 RPDU3_B5_SSPC_DianHuErr_01 "SSPC1电弧故障状态";
CM_ SG_ 2419982352 BackUp207 "预留";
CM_ SG_ 2419916816 BackUp206 "预留";
CM_ SG_ 2419916816 BackUp205 "预留";
CM_ SG_ 2419916816 BackUp204 "预留";
CM_ SG_ 2419916816 BackUp203 "预留";
CM_ SG_ 2419916816 RPDU3_B4_SSPC_I_Load_18 "SSPC18通道电流";
CM_ SG_ 2419916816 RPDU3_B4_SSPC_TripSta_18 "SSPC18跳闸状态";
CM_ SG_ 2419916816 RPDU3_B4_SSPC_BitErr_18 "SSPC18通断周期自检状态";
CM_ SG_ 2419916816 RPDU3_B4_SSPC_OnOffSta_18 "SSPC18通断状态";
CM_ SG_ 2419916816 RPDU3_B4_SSPC_DianHuErr_18 "SSPC18电弧故障状态";
CM_ SG_ 2419916816 BackUp202 "预留";
CM_ SG_ 2419916816 RPDU3_B4_SSPC_I_Load_17 "SSPC17通道电流";
CM_ SG_ 2419916816 RPDU3_B4_SSPC_TripSta_17 "SSPC17跳闸状态";
CM_ SG_ 2419916816 RPDU3_B4_SSPC_BitErr_17 "SSPC17通断周期自检状态";
CM_ SG_ 2419916816 RPDU3_B4_SSPC_OnOffSta_17 "SSPC17通断状态";
CM_ SG_ 2419916816 RPDU3_B4_SSPC_DianHuErr_17 "SSPC17电弧故障状态";
CM_ SG_ 2419916816 BackUp201 "预留";
CM_ SG_ 2419851280 RPDU3_B4_SSPC_I_Load_16 "SSPC16通道电流";
CM_ SG_ 2419851280 RPDU3_B4_SSPC_TripSta_16 "SSPC16跳闸状态";
CM_ SG_ 2419851280 RPDU3_B4_SSPC_BitErr_16 "SSPC16通断周期自检状态";
CM_ SG_ 2419851280 RPDU3_B4_SSPC_OnOffSta_16 "SSPC16通断状态";
CM_ SG_ 2419851280 RPDU3_B4_SSPC_DianHuErr_16 "SSPC16电弧故障状态";
CM_ SG_ 2419851280 BackUp200 "预留";
CM_ SG_ 2419851280 RPDU3_B4_SSPC_I_Load_15 "SSPC15通道电流";
CM_ SG_ 2419851280 RPDU3_B4_SSPC_TripSta_15 "SSPC15跳闸状态";
CM_ SG_ 2419851280 RPDU3_B4_SSPC_BitErr_15 "SSPC15通断周期自检状态";
CM_ SG_ 2419851280 RPDU3_B4_SSPC_OnOffSta_15 "SSPC15通断状态";
CM_ SG_ 2419851280 RPDU3_B4_SSPC_DianHuErr_15 "SSPC15电弧故障状态";
CM_ SG_ 2419851280 BackUp199 "预留";
CM_ SG_ 2419851280 RPDU3_B4_SSPC_I_Load_14 "SSPC14通道电流";
CM_ SG_ 2419851280 RPDU3_B4_SSPC_TripSta_14 "SSPC14跳闸状态";
CM_ SG_ 2419851280 RPDU3_B4_SSPC_BitErr_14 "SSPC14通断周期自检状态";
CM_ SG_ 2419851280 RPDU3_B4_SSPC_OnOffSta_14 "SSPC14通断状态";
CM_ SG_ 2419851280 RPDU3_B4_SSPC_DianHuErr_14 "SSPC14电弧故障状态";
CM_ SG_ 2419851280 BackUp198 "预留";
CM_ SG_ 2419851280 RPDU3_B4_SSPC_I_Load_13 "SSPC13通道电流";
CM_ SG_ 2419851280 RPDU3_B4_SSPC_TripSta_13 "SSPC13跳闸状态";
CM_ SG_ 2419851280 RPDU3_B4_SSPC_BitErr_13 "SSPC13通断周期自检状态";
CM_ SG_ 2419851280 RPDU3_B4_SSPC_OnOffSta_13 "SSPC13通断状态";
CM_ SG_ 2419851280 RPDU3_B4_SSPC_DianHuErr_13 "SSPC13电弧故障状态";
CM_ SG_ 2419851280 BackUp197 "预留";
CM_ SG_ 2419785744 RPDU3_B4_SSPC_I_Load_12 "SSPC12通道电流";
CM_ SG_ 2419785744 RPDU3_B4_SSPC_TripSta_12 "SSPC12跳闸状态";
CM_ SG_ 2419785744 RPDU3_B4_SSPC_BitErr_12 "SSPC12通断周期自检状态";
CM_ SG_ 2419785744 RPDU3_B4_SSPC_OnOffSta_12 "SSPC12通断状态";
CM_ SG_ 2419785744 RPDU3_B4_SSPC_DianHuErr_12 "SSPC12电弧故障状态";
CM_ SG_ 2419785744 BackUp196 "预留";
CM_ SG_ 2419785744 RPDU3_B4_SSPC_I_Load_11 "SSPC11通道电流";
CM_ SG_ 2419785744 RPDU3_B4_SSPC_TripSta_11 "SSPC11跳闸状态";
CM_ SG_ 2419785744 RPDU3_B4_SSPC_BitErr_11 "SSPC11通断周期自检状态";
CM_ SG_ 2419785744 RPDU3_B4_SSPC_OnOffSta_11 "SSPC11通断状态";
CM_ SG_ 2419785744 RPDU3_B4_SSPC_DianHuErr_11 "SSPC11电弧故障状态";
CM_ SG_ 2419785744 BackUp195 "预留";
CM_ SG_ 2419785744 RPDU3_B4_SSPC_I_Load_10 "SSPC10通道电流";
CM_ SG_ 2419785744 RPDU3_B4_SSPC_TripSta_10 "SSPC10跳闸状态";
CM_ SG_ 2419785744 RPDU3_B4_SSPC_BitErr_10 "SSPC10通断周期自检状态";
CM_ SG_ 2419785744 RPDU3_B4_SSPC_OnOffSta_10 "SSPC10通断状态";
CM_ SG_ 2419785744 RPDU3_B4_SSPC_DianHuErr_10 "SSPC10电弧故障状态";
CM_ SG_ 2419785744 BackUp194 "预留";
CM_ SG_ 2419785744 RPDU3_B4_SSPC_I_Load_09 "SSPC9通道电流";
CM_ SG_ 2419785744 RPDU3_B4_SSPC_TripSta_09 "SSPC9跳闸状态";
CM_ SG_ 2419785744 RPDU3_B4_SSPC_BitErr_09 "SSPC9通断周期自检状态";
CM_ SG_ 2419785744 RPDU3_B4_SSPC_OnOffSta_09 "SSPC9通断状态";
CM_ SG_ 2419785744 RPDU3_B4_SSPC_DianHuErr_09 "SSPC9电弧故障状态";
CM_ SG_ 2419785744 BackUp193 "预留";
CM_ SG_ 2419720208 RPDU3_B4_SSPC_I_Load_08 "SSPC8通道电流";
CM_ SG_ 2419720208 RPDU3_B4_SSPC_TripSta_08 "SSPC8跳闸状态";
CM_ SG_ 2419720208 RPDU3_B4_SSPC_BitErr_08 "SSPC8通断周期自检状态";
CM_ SG_ 2419720208 RPDU3_B4_SSPC_OnOffSta_08 "SSPC8通断状态";
CM_ SG_ 2419720208 RPDU3_B4_SSPC_DianHuErr_08 "SSPC8电弧故障状态";
CM_ SG_ 2419720208 BackUp192 "预留";
CM_ SG_ 2419720208 RPDU3_B4_SSPC_I_Load_07 "SSPC7通道电流";
CM_ SG_ 2419720208 RPDU3_B4_SSPC_TripSta_07 "SSPC7跳闸状态";
CM_ SG_ 2419720208 RPDU3_B4_SSPC_BitErr_07 "SSPC7通断周期自检状态";
CM_ SG_ 2419720208 RPDU3_B4_SSPC_OnOffSta_07 "SSPC7通断状态";
CM_ SG_ 2419720208 RPDU3_B4_SSPC_DianHuErr_07 "SSPC7电弧故障状态";
CM_ SG_ 2419720208 BackUp191 "预留";
CM_ SG_ 2419720208 RPDU3_B4_SSPC_I_Load_06 "SSPC6通道电流";
CM_ SG_ 2419720208 RPDU3_B4_SSPC_TripSta_06 "SSPC6跳闸状态";
CM_ SG_ 2419720208 RPDU3_B4_SSPC_BitErr_06 "SSPC6通断周期自检状态";
CM_ SG_ 2419720208 RPDU3_B4_SSPC_OnOffSta_06 "SSPC6通断状态";
CM_ SG_ 2419720208 RPDU3_B4_SSPC_DianHuErr_06 "SSPC6电弧故障状态";
CM_ SG_ 2419720208 BackUp190 "预留";
CM_ SG_ 2419720208 RPDU3_B4_SSPC_I_Load_05 "SSPC5通道电流";
CM_ SG_ 2419720208 RPDU3_B4_SSPC_TripSta_05 "SSPC5跳闸状态";
CM_ SG_ 2419720208 RPDU3_B4_SSPC_BitErr_05 "SSPC5通断周期自检状态";
CM_ SG_ 2419720208 RPDU3_B4_SSPC_OnOffSta_05 "SSPC5通断状态";
CM_ SG_ 2419720208 RPDU3_B4_SSPC_DianHuErr_05 "SSPC5电弧故障状态";
CM_ SG_ 2419720208 BackUp189 "预留";
CM_ SG_ 2419654672 RPDU3_B4_SSPC_I_Load_04 "SSPC4通道电流";
CM_ SG_ 2419654672 RPDU3_B4_SSPC_TripSta_04 "SSPC4跳闸状态";
CM_ SG_ 2419654672 RPDU3_B4_SSPC_BitErr_04 "SSPC4通断周期自检状态";
CM_ SG_ 2419654672 RPDU3_B4_SSPC_OnOffSta_04 "SSPC4通断状态";
CM_ SG_ 2419654672 RPDU3_B4_SSPC_DianHuErr_04 "SSPC4电弧故障状态";
CM_ SG_ 2419654672 BackUp188 "预留";
CM_ SG_ 2419654672 RPDU3_B4_SSPC_I_Load_03 "SSPC3通道电流";
CM_ SG_ 2419654672 RPDU3_B4_SSPC_TripSta_03 "SSPC3跳闸状态";
CM_ SG_ 2419654672 RPDU3_B4_SSPC_BitErr_03 "SSPC3通断周期自检状态";
CM_ SG_ 2419654672 RPDU3_B4_SSPC_OnOffSta_03 "SSPC3通断状态";
CM_ SG_ 2419654672 RPDU3_B4_SSPC_DianHuErr_03 "SSPC3电弧故障状态";
CM_ SG_ 2419654672 BackUp187 "预留";
CM_ SG_ 2419654672 RPDU3_B4_SSPC_I_Load_02 "SSPC2通道电流";
CM_ SG_ 2419654672 RPDU3_B4_SSPC_TripSta_02 "SSPC2跳闸状态";
CM_ SG_ 2419654672 RPDU3_B4_SSPC_BitErr_02 "SSPC2通断周期自检状态";
CM_ SG_ 2419654672 RPDU3_B4_SSPC_OnOffSta_02 "SSPC2通断状态";
CM_ SG_ 2419654672 RPDU3_B4_SSPC_DianHuErr_02 "SSPC2电弧故障状态";
CM_ SG_ 2419654672 BackUp186 "预留";
CM_ SG_ 2419654672 RPDU3_B4_SSPC_I_Load_01 "SSPC1通道电流";
CM_ SG_ 2419654672 RPDU3_B4_SSPC_TripSta_01 "SSPC1跳闸状态";
CM_ SG_ 2419654672 RPDU3_B4_SSPC_BitErr_01 "SSPC1通断周期自检状态";
CM_ SG_ 2419654672 RPDU3_B4_SSPC_OnOffSta_01 "SSPC1通断状态";
CM_ SG_ 2419654672 RPDU3_B4_SSPC_DianHuErr_01 "SSPC1电弧故障状态";
CM_ SG_ 2419654672 BackUp185 "预留";
BA_DEF_ SG_  "GenSigSwitchedByIgnition" ENUM  "No","Yes";
BA_DEF_ SG_  "GenSigFuncType" ENUM  "NoFunction","MsgCounter","CRC-8","XOR","XOR-2","DatedBit","SW-Kl15","CHK","Constant","Protocol","CRC-8-SAE_J1850","CRC-32","DataLength","DataID","MsgCounter16","SOK-Signatur","Cluster";
BA_DEF_ BO_  "MsgType" ENUM  "Application","NM ","NMH","TP2.0","ISO-TP ","BAP","EID","KS","XCP_PRE_CONFIGURED","XCP_RUNTIME_CONFIGURED";
BA_DEF_ BO_  "GenMsgILSupport" ENUM  "No","Yes";
BA_DEF_ BO_  "GenMsgCycleTime" INT 0 65535;
BA_DEF_ BO_  "GenMsgMinAcceptLength" INT 0 8;
BA_DEF_ BO_  "GenMsgSendType" ENUM  "Cyclic","CyclicAndSpontanX","Event";
BA_DEF_ BO_  "CANFD_BRS" ENUM  "0","1";
BA_DEF_ BO_  "VFrameFormat" ENUM  "StandardCAN","ExtendedCAN","reserved","reserved","reserved","reserved","reserved","reserved","reserved","reserved","reserved","reserved","reserved","reserved","StandardCAN_FD","ExtendedCAN_FD";
BA_DEF_ SG_  "GenSigEnvVarType" ENUM  "undef","int","float";
BA_DEF_ SG_  "GenSigSendType" ENUM  "Cyclic","OnWrite","OnWriteWithRepetition","OnChange","OnChangeWithRepetition","IfActive","IfActiveWithRepetition","NoSigSendType","NotUsed","NotUsed","NotUsed","NotUsed","NotUsed";
BA_DEF_ SG_  "GenSigStartValue" FLOAT 0 1215752192;
BA_DEF_DEF_  "GenSigSwitchedByIgnition" "Yes";
BA_DEF_DEF_  "GenSigFuncType" "NoFunction";
BA_DEF_DEF_  "MsgType" "Application";
BA_DEF_DEF_  "GenMsgILSupport" "Yes";
BA_DEF_DEF_  "GenMsgCycleTime" 10;
BA_DEF_DEF_  "GenMsgMinAcceptLength" 8;
BA_DEF_DEF_  "GenMsgSendType" "Cyclic";
BA_DEF_DEF_  "CANFD_BRS" "1";
BA_DEF_DEF_  "VFrameFormat" "StandardCAN";
BA_DEF_DEF_  "GenSigEnvVarType" "undef";
BA_DEF_DEF_  "GenSigSendType" "Cyclic";
BA_DEF_DEF_  "GenSigStartValue" 0;
BA_ "GenMsgCycleTime" BO_ 2418933792 400;
BA_ "VFrameFormat" BO_ 2418933792 1;
BA_ "GenMsgCycleTime" BO_ 2418868256 400;
BA_ "VFrameFormat" BO_ 2418868256 1;
BA_ "GenMsgCycleTime" BO_ 2418802720 400;
BA_ "VFrameFormat" BO_ 2418802720 1;
BA_ "GenMsgCycleTime" BO_ 2418737184 400;
BA_ "VFrameFormat" BO_ 2418737184 1;
BA_ "GenMsgCycleTime" BO_ 2418671648 400;
BA_ "VFrameFormat" BO_ 2418671648 1;
BA_ "GenMsgCycleTime" BO_ 2418606112 400;
BA_ "VFrameFormat" BO_ 2418606112 1;
BA_ "GenMsgCycleTime" BO_ 2418540576 400;
BA_ "VFrameFormat" BO_ 2418540576 1;
BA_ "GenMsgCycleTime" BO_ 2418475040 400;
BA_ "VFrameFormat" BO_ 2418475040 1;
BA_ "GenMsgCycleTime" BO_ 2418409504 400;
BA_ "VFrameFormat" BO_ 2418409504 1;
BA_ "GenMsgCycleTime" BO_ 2418343968 400;
BA_ "VFrameFormat" BO_ 2418343968 1;
BA_ "GenMsgCycleTime" BO_ 2418278432 400;
BA_ "VFrameFormat" BO_ 2418278432 1;
BA_ "GenMsgCycleTime" BO_ 2418212896 400;
BA_ "VFrameFormat" BO_ 2418212896 1;
BA_ "GenMsgCycleTime" BO_ 2418147360 400;
BA_ "VFrameFormat" BO_ 2418147360 1;
BA_ "GenMsgCycleTime" BO_ 2418081824 400;
BA_ "VFrameFormat" BO_ 2418081824 1;
BA_ "GenMsgCycleTime" BO_ 2418016288 400;
BA_ "VFrameFormat" BO_ 2418016288 1;
BA_ "GenMsgCycleTime" BO_ 2417950752 400;
BA_ "VFrameFormat" BO_ 2417950752 1;
BA_ "GenMsgCycleTime" BO_ 2417885216 400;
BA_ "VFrameFormat" BO_ 2417885216 1;
BA_ "GenMsgCycleTime" BO_ 2417819680 400;
BA_ "VFrameFormat" BO_ 2417819680 1;
BA_ "GenMsgCycleTime" BO_ 2417754144 400;
BA_ "VFrameFormat" BO_ 2417754144 1;
BA_ "GenMsgCycleTime" BO_ 2417688608 400;
BA_ "VFrameFormat" BO_ 2417688608 1;
BA_ "GenMsgCycleTime" BO_ 2417623072 400;
BA_ "VFrameFormat" BO_ 2417623072 1;
BA_ "GenMsgCycleTime" BO_ 2417557536 400;
BA_ "VFrameFormat" BO_ 2417557536 1;
BA_ "GenMsgCycleTime" BO_ 2417492000 400;
BA_ "VFrameFormat" BO_ 2417492000 1;
BA_ "GenMsgCycleTime" BO_ 2417426464 400;
BA_ "VFrameFormat" BO_ 2417426464 1;
BA_ "GenMsgCycleTime" BO_ 2417360928 400;
BA_ "VFrameFormat" BO_ 2417360928 1;
BA_ "GenMsgCycleTime" BO_ 2417295392 400;
BA_ "VFrameFormat" BO_ 2417295392 1;
BA_ "GenMsgCycleTime" BO_ 2417229856 400;
BA_ "VFrameFormat" BO_ 2417229856 1;
BA_ "GenMsgCycleTime" BO_ 2417164320 400;
BA_ "VFrameFormat" BO_ 2417164320 1;
BA_ "GenMsgCycleTime" BO_ 2417098784 400;
BA_ "VFrameFormat" BO_ 2417098784 1;
BA_ "GenMsgCycleTime" BO_ 2417033248 400;
BA_ "VFrameFormat" BO_ 2417033248 1;
BA_ "GenMsgCycleTime" BO_ 2416967712 400;
BA_ "VFrameFormat" BO_ 2416967712 1;
BA_ "GenMsgCycleTime" BO_ 2416902176 400;
BA_ "VFrameFormat" BO_ 2416902176 1;
BA_ "GenMsgCycleTime" BO_ 2416836640 400;
BA_ "VFrameFormat" BO_ 2416836640 1;
BA_ "GenMsgCycleTime" BO_ 2416771104 400;
BA_ "VFrameFormat" BO_ 2416771104 1;
BA_ "GenMsgCycleTime" BO_ 2416705568 400;
BA_ "VFrameFormat" BO_ 2416705568 1;
BA_ "GenMsgCycleTime" BO_ 2416574496 400;
BA_ "VFrameFormat" BO_ 2416574496 1;
BA_ "GenMsgCycleTime" BO_ 2416508960 400;
BA_ "VFrameFormat" BO_ 2416508960 1;
BA_ "GenMsgCycleTime" BO_ 2416443424 400;
BA_ "VFrameFormat" BO_ 2416443424 1;
BA_ "GenMsgCycleTime" BO_ 2416377888 400;
BA_ "VFrameFormat" BO_ 2416377888 1;
BA_ "GenMsgCycleTime" BO_ 2416312352 400;
BA_ "VFrameFormat" BO_ 2416312352 1;
BA_ "GenMsgCycleTime" BO_ 2416246816 400;
BA_ "VFrameFormat" BO_ 2416246816 1;
BA_ "GenMsgCycleTime" BO_ 2416181280 400;
BA_ "VFrameFormat" BO_ 2416181280 1;
BA_ "GenMsgCycleTime" BO_ 2416115744 400;
BA_ "VFrameFormat" BO_ 2416115744 1;
BA_ "GenMsgCycleTime" BO_ 2416050208 400;
BA_ "VFrameFormat" BO_ 2416050208 1;
BA_ "GenMsgCycleTime" BO_ 2415984672 400;
BA_ "VFrameFormat" BO_ 2415984672 1;
BA_ "VFrameFormat" BO_ 2421178384 1;
BA_ "GenMsgCycleTime" BO_ 2420244496 400;
BA_ "VFrameFormat" BO_ 2420244496 1;
BA_ "GenMsgCycleTime" BO_ 2420178960 400;
BA_ "VFrameFormat" BO_ 2420178960 1;
BA_ "GenMsgCycleTime" BO_ 2420113424 400;
BA_ "VFrameFormat" BO_ 2420113424 1;
BA_ "GenMsgCycleTime" BO_ 2420047888 400;
BA_ "VFrameFormat" BO_ 2420047888 1;
BA_ "GenMsgCycleTime" BO_ 2419982352 400;
BA_ "VFrameFormat" BO_ 2419982352 1;
BA_ "GenMsgCycleTime" BO_ 2419916816 400;
BA_ "VFrameFormat" BO_ 2419916816 1;
BA_ "GenMsgCycleTime" BO_ 2419851280 400;
BA_ "VFrameFormat" BO_ 2419851280 1;
BA_ "GenMsgCycleTime" BO_ 2419785744 400;
BA_ "VFrameFormat" BO_ 2419785744 1;
BA_ "GenMsgCycleTime" BO_ 2419720208 400;
BA_ "VFrameFormat" BO_ 2419720208 1;
BA_ "GenMsgCycleTime" BO_ 2419654672 400;
BA_ "VFrameFormat" BO_ 2419654672 1;
BA_ "GenSigStartValue" SG_ 2416574496 R_MCU_Ver_Day 1;
BA_ "GenSigStartValue" SG_ 2416574496 R_MCU_Ver_Month 1;
VAL_ 2418933792 RPDU4_B1_SSPC_TripSta_18 1 "短路跳闸" 2 "过流跳闸" 0 "正常" 3 "无定义" ;
VAL_ 2418933792 RPDU4_B1_SSPC_BitErr_18 1 "故障" 0 "正常" ;
VAL_ 2418933792 RPDU4_B1_SSPC_OnOffSta_18 1 "接通" 0 "断开" ;
VAL_ 2418933792 RPDU4_B1_SSPC_DianHuErr_18 1 "有故障" 0 "无故障" ;
VAL_ 2418933792 RPDU4_B1_SSPC_TripSta_17 1 "短路跳闸" 2 "过流跳闸" 0 "正常" 3 "无定义" ;
VAL_ 2418933792 RPDU4_B1_SSPC_BitErr_17 1 "故障" 0 "正常" ;
VAL_ 2418933792 RPDU4_B1_SSPC_OnOffSta_17 1 "接通" 0 "断开" ;
VAL_ 2418933792 RPDU4_B1_SSPC_DianHuErr_17 1 "有故障" 0 "无故障" ;
VAL_ 2418868256 RPDU4_B1_SSPC_TripSta_16 1 "短路跳闸" 2 "过流跳闸" 0 "正常" 3 "无定义" ;
VAL_ 2418868256 RPDU4_B1_SSPC_BitErr_16 1 "故障" 0 "正常" ;
VAL_ 2418868256 RPDU4_B1_SSPC_OnOffSta_16 1 "接通" 0 "断开" ;
VAL_ 2418868256 RPDU4_B1_SSPC_DianHuErr_16 1 "有故障" 0 "无故障" ;
VAL_ 2418868256 RPDU4_B1_SSPC_TripSta_15 1 "短路跳闸" 2 "过流跳闸" 0 "正常" 3 "无定义" ;
VAL_ 2418868256 RPDU4_B1_SSPC_BitErr_15 1 "故障" 0 "正常" ;
VAL_ 2418868256 RPDU4_B1_SSPC_OnOffSta_15 1 "接通" 0 "断开" ;
VAL_ 2418868256 RPDU4_B1_SSPC_DianHuErr_15 1 "有故障" 0 "无故障" ;
VAL_ 2418868256 RPDU4_B1_SSPC_TripSta_14 1 "短路跳闸" 2 "过流跳闸" 0 "正常" 3 "无定义" ;
VAL_ 2418868256 RPDU4_B1_SSPC_BitErr_14 1 "故障" 0 "正常" ;
VAL_ 2418868256 RPDU4_B1_SSPC_OnOffSta_14 1 "接通" 0 "断开" ;
VAL_ 2418868256 RPDU4_B1_SSPC_DianHuErr_14 1 "有故障" 0 "无故障" ;
VAL_ 2418868256 RPDU4_B1_SSPC_TripSta_13 1 "短路跳闸" 2 "过流跳闸" 0 "正常" 3 "无定义" ;
VAL_ 2418868256 RPDU4_B1_SSPC_BitErr_13 1 "故障" 0 "正常" ;
VAL_ 2418868256 RPDU4_B1_SSPC_OnOffSta_13 1 "接通" 0 "断开" ;
VAL_ 2418868256 RPDU4_B1_SSPC_DianHuErr_13 1 "有故障" 0 "无故障" ;
VAL_ 2418802720 RPDU4_B1_SSPC_TripSta_12 1 "短路跳闸" 2 "过流跳闸" 0 "正常" 3 "无定义" ;
VAL_ 2418802720 RPDU4_B1_SSPC_BitErr_12 1 "故障" 0 "正常" ;
VAL_ 2418802720 RPDU4_B1_SSPC_OnOffSta_12 1 "接通" 0 "断开" ;
VAL_ 2418802720 RPDU4_B1_SSPC_DianHuErr_12 1 "有故障" 0 "无故障" ;
VAL_ 2418802720 RPDU4_B1_SSPC_TripSta_11 1 "短路跳闸" 2 "过流跳闸" 0 "正常" 3 "无定义" ;
VAL_ 2418802720 RPDU4_B1_SSPC_BitErr_11 1 "故障" 0 "正常" ;
VAL_ 2418802720 RPDU4_B1_SSPC_OnOffSta_11 1 "接通" 0 "断开" ;
VAL_ 2418802720 RPDU4_B1_SSPC_DianHuErr_11 1 "有故障" 0 "无故障" ;
VAL_ 2418802720 RPDU4_B1_SSPC_TripSta_10 1 "短路跳闸" 2 "过流跳闸" 0 "正常" 3 "无定义" ;
VAL_ 2418802720 RPDU4_B1_SSPC_BitErr_10 1 "故障" 0 "正常" ;
VAL_ 2418802720 RPDU4_B1_SSPC_OnOffSta_10 1 "接通" 0 "断开" ;
VAL_ 2418802720 RPDU4_B1_SSPC_DianHuErr_10 1 "有故障" 0 "无故障" ;
VAL_ 2418802720 RPDU4_B1_SSPC_TripSta_09 1 "短路跳闸" 2 "过流跳闸" 0 "正常" 3 "无定义" ;
VAL_ 2418802720 RPDU4_B1_SSPC_BitErr_09 1 "故障" 0 "正常" ;
VAL_ 2418802720 RPDU4_B1_SSPC_OnOffSta_09 1 "接通" 0 "断开" ;
VAL_ 2418802720 RPDU4_B1_SSPC_DianHuErr_09 1 "有故障" 0 "无故障" ;
VAL_ 2418737184 RPDU4_B1_SSPC_TripSta_08 1 "短路跳闸" 2 "过流跳闸" 0 "正常" 3 "无定义" ;
VAL_ 2418737184 RPDU4_B1_SSPC_BitErr_08 1 "故障" 0 "正常" ;
VAL_ 2418737184 RPDU4_B1_SSPC_OnOffSta_08 1 "接通" 0 "断开" ;
VAL_ 2418737184 RPDU4_B1_SSPC_DianHuErr_08 1 "有故障" 0 "无故障" ;
VAL_ 2418737184 RPDU4_B1_SSPC_TripSta_07 1 "短路跳闸" 2 "过流跳闸" 0 "正常" 3 "无定义" ;
VAL_ 2418737184 RPDU4_B1_SSPC_BitErr_07 1 "故障" 0 "正常" ;
VAL_ 2418737184 RPDU4_B1_SSPC_OnOffSta_07 1 "接通" 0 "断开" ;
VAL_ 2418737184 RPDU4_B1_SSPC_DianHuErr_07 1 "有故障" 0 "无故障" ;
VAL_ 2418737184 RPDU4_B1_SSPC_TripSta_06 1 "短路跳闸" 2 "过流跳闸" 0 "正常" 3 "无定义" ;
VAL_ 2418737184 RPDU4_B1_SSPC_BitErr_06 1 "故障" 0 "正常" ;
VAL_ 2418737184 RPDU4_B1_SSPC_OnOffSta_06 1 "接通" 0 "断开" ;
VAL_ 2418737184 RPDU4_B1_SSPC_DianHuErr_06 1 "有故障" 0 "无故障" ;
VAL_ 2418737184 RPDU4_B1_SSPC_TripSta_05 1 "短路跳闸" 2 "过流跳闸" 0 "正常" 3 "无定义" ;
VAL_ 2418737184 RPDU4_B1_SSPC_BitErr_05 1 "故障" 0 "正常" ;
VAL_ 2418737184 RPDU4_B1_SSPC_OnOffSta_05 1 "接通" 0 "断开" ;
VAL_ 2418737184 RPDU4_B1_SSPC_DianHuErr_05 1 "有故障" 0 "无故障" ;
VAL_ 2418671648 RPDU4_B1_SSPC_TripSta_04 1 "短路跳闸" 2 "过流跳闸" 0 "正常" 3 "无定义" ;
VAL_ 2418671648 RPDU4_B1_SSPC_BitErr_04 1 "故障" 0 "正常" ;
VAL_ 2418671648 RPDU4_B1_SSPC_OnOffSta_04 1 "接通" 0 "断开" ;
VAL_ 2418671648 RPDU4_B1_SSPC_DianHuErr_04 1 "有故障" 0 "无故障" ;
VAL_ 2418671648 RPDU4_B1_SSPC_TripSta_03 1 "短路跳闸" 2 "过流跳闸" 0 "正常" 3 "无定义" ;
VAL_ 2418671648 RPDU4_B1_SSPC_BitErr_03 1 "故障" 0 "正常" ;
VAL_ 2418671648 RPDU4_B1_SSPC_OnOffSta_03 1 "接通" 0 "断开" ;
VAL_ 2418671648 RPDU4_B1_SSPC_DianHuErr_03 1 "有故障" 0 "无故障" ;
VAL_ 2418671648 RPDU4_B1_SSPC_TripSta_02 1 "短路跳闸" 2 "过流跳闸" 0 "正常" 3 "无定义" ;
VAL_ 2418671648 RPDU4_B1_SSPC_BitErr_02 1 "故障" 0 "正常" ;
VAL_ 2418671648 RPDU4_B1_SSPC_OnOffSta_02 1 "接通" 0 "断开" ;
VAL_ 2418671648 RPDU4_B1_SSPC_DianHuErr_02 1 "有故障" 0 "无故障" ;
VAL_ 2418671648 RPDU4_B1_SSPC_TripSta_01 1 "短路跳闸" 2 "过流跳闸" 0 "正常" 3 "无定义" ;
VAL_ 2418671648 RPDU4_B1_SSPC_BitErr_01 1 "故障" 0 "正常" ;
VAL_ 2418671648 RPDU4_B1_SSPC_OnOffSta_01 1 "接通" 0 "断开" ;
VAL_ 2418671648 RPDU4_B1_SSPC_DianHuErr_01 1 "有故障" 0 "无故障" ;
VAL_ 2418540576 RPDU2_B6_SSPC_TripSta_07 1 "短路跳闸" 2 "过流跳闸" 0 "正常" 3 "无定义" ;
VAL_ 2418540576 RPDU2_B6_SSPC_BitErr_07 1 "故障" 0 "正常" ;
VAL_ 2418540576 RPDU2_B6_SSPC_OnOffSta_07 1 "接通" 0 "断开" ;
VAL_ 2418540576 RPDU2_B6_SSPC_DianHuErr_07 1 "有故障" 0 "无故障" ;
VAL_ 2418540576 RPDU2_B6_SSPC_TripSta_06 1 "短路跳闸" 2 "过流跳闸" 0 "正常" 3 "无定义" ;
VAL_ 2418540576 RPDU2_B6_SSPC_BitErr_06 1 "故障" 0 "正常" ;
VAL_ 2418540576 RPDU2_B6_SSPC_OnOffSta_06 1 "接通" 0 "断开" ;
VAL_ 2418540576 RPDU2_B6_SSPC_DianHuErr_06 1 "有故障" 0 "无故障" ;
VAL_ 2418540576 RPDU2_B6_SSPC_TripSta_05 1 "短路跳闸" 2 "过流跳闸" 0 "正常" 3 "无定义" ;
VAL_ 2418540576 RPDU2_B6_SSPC_BitErr_05 1 "故障" 0 "正常" ;
VAL_ 2418540576 RPDU2_B6_SSPC_OnOffSta_05 1 "接通" 0 "断开" ;
VAL_ 2418540576 RPDU2_B6_SSPC_DianHuErr_05 1 "有故障" 0 "无故障" ;
VAL_ 2418475040 RPDU2_B6_SSPC_TripSta_04 1 "短路跳闸" 2 "过流跳闸" 0 "正常" 3 "无定义" ;
VAL_ 2418475040 RPDU2_B6_SSPC_BitErr_04 1 "故障" 0 "正常" ;
VAL_ 2418475040 RPDU2_B6_SSPC_OnOffSta_04 1 "接通" 0 "断开" ;
VAL_ 2418475040 RPDU2_B6_SSPC_DianHuErr_04 1 "有故障" 0 "无故障" ;
VAL_ 2418475040 RPDU2_B6_SSPC_TripSta_03 1 "短路跳闸" 2 "过流跳闸" 0 "正常" 3 "无定义" ;
VAL_ 2418475040 RPDU2_B6_SSPC_BitErr_03 1 "故障" 0 "正常" ;
VAL_ 2418475040 RPDU2_B6_SSPC_OnOffSta_03 1 "接通" 0 "断开" ;
VAL_ 2418475040 RPDU2_B6_SSPC_DianHuErr_03 1 "有故障" 0 "无故障" ;
VAL_ 2418475040 RPDU2_B6_SSPC_TripSta_02 1 "短路跳闸" 2 "过流跳闸" 0 "正常" 3 "无定义" ;
VAL_ 2418475040 RPDU2_B6_SSPC_BitErr_02 1 "故障" 0 "正常" ;
VAL_ 2418475040 RPDU2_B6_SSPC_OnOffSta_02 1 "接通" 0 "断开" ;
VAL_ 2418475040 RPDU2_B6_SSPC_DianHuErr_02 1 "有故障" 0 "无故障" ;
VAL_ 2418475040 RPDU2_B6_SSPC_TripSta_01 1 "短路跳闸" 2 "过流跳闸" 0 "正常" 3 "无定义" ;
VAL_ 2418475040 RPDU2_B6_SSPC_BitErr_01 1 "故障" 0 "正常" ;
VAL_ 2418475040 RPDU2_B6_SSPC_OnOffSta_01 1 "接通" 0 "断开" ;
VAL_ 2418475040 RPDU2_B6_SSPC_DianHuErr_01 1 "有故障" 0 "无故障" ;
VAL_ 2418409504 RPDU2_B5_SSPC_TripSta_07 1 "短路跳闸" 2 "过流跳闸" 0 "正常" 3 "无定义" ;
VAL_ 2418409504 RPDU2_B5_SSPC_BitErr_07 1 "故障" 0 "正常" ;
VAL_ 2418409504 RPDU2_B5_SSPC_OnOffSta_07 1 "接通" 0 "断开" ;
VAL_ 2418409504 RPDU2_B5_SSPC_DianHuErr_07 1 "有故障" 0 "无故障" ;
VAL_ 2418409504 RPDU2_B5_SSPC_TripSta_06 1 "短路跳闸" 2 "过流跳闸" 0 "正常" 3 "无定义" ;
VAL_ 2418409504 RPDU2_B5_SSPC_BitErr_06 1 "故障" 0 "正常" ;
VAL_ 2418409504 RPDU2_B5_SSPC_OnOffSta_06 1 "接通" 0 "断开" ;
VAL_ 2418409504 RPDU2_B5_SSPC_DianHuErr_06 1 "有故障" 0 "无故障" ;
VAL_ 2418409504 RPDU2_B5_SSPC_TripSta_05 1 "短路跳闸" 2 "过流跳闸" 0 "正常" 3 "无定义" ;
VAL_ 2418409504 RPDU2_B5_SSPC_BitErr_05 1 "故障" 0 "正常" ;
VAL_ 2418409504 RPDU2_B5_SSPC_OnOffSta_05 1 "接通" 0 "断开" ;
VAL_ 2418409504 RPDU2_B5_SSPC_DianHuErr_05 1 "有故障" 0 "无故障" ;
VAL_ 2418343968 RPDU2_B5_SSPC_TripSta_04 1 "短路跳闸" 2 "过流跳闸" 0 "正常" 3 "无定义" ;
VAL_ 2418343968 RPDU2_B5_SSPC_BitErr_04 1 "故障" 0 "正常" ;
VAL_ 2418343968 RPDU2_B5_SSPC_OnOffSta_04 1 "接通" 0 "断开" ;
VAL_ 2418343968 RPDU2_B5_SSPC_DianHuErr_04 1 "有故障" 0 "无故障" ;
VAL_ 2418343968 RPDU2_B5_SSPC_TripSta_03 1 "短路跳闸" 2 "过流跳闸" 0 "正常" 3 "无定义" ;
VAL_ 2418343968 RPDU2_B5_SSPC_BitErr_03 1 "故障" 0 "正常" ;
VAL_ 2418343968 RPDU2_B5_SSPC_OnOffSta_03 1 "接通" 0 "断开" ;
VAL_ 2418343968 RPDU2_B5_SSPC_DianHuErr_03 1 "有故障" 0 "无故障" ;
VAL_ 2418343968 RPDU2_B5_SSPC_TripSta_02 1 "短路跳闸" 2 "过流跳闸" 0 "正常" 3 "无定义" ;
VAL_ 2418343968 RPDU2_B5_SSPC_BitErr_02 1 "故障" 0 "正常" ;
VAL_ 2418343968 RPDU2_B5_SSPC_OnOffSta_02 1 "接通" 0 "断开" ;
VAL_ 2418343968 RPDU2_B5_SSPC_DianHuErr_02 1 "有故障" 0 "无故障" ;
VAL_ 2418343968 RPDU2_B5_SSPC_TripSta_01 1 "短路跳闸" 2 "过流跳闸" 0 "正常" 3 "无定义" ;
VAL_ 2418343968 RPDU2_B5_SSPC_BitErr_01 1 "故障" 0 "正常" ;
VAL_ 2418343968 RPDU2_B5_SSPC_OnOffSta_01 1 "接通" 0 "断开" ;
VAL_ 2418343968 RPDU2_B5_SSPC_DianHuErr_01 1 "有故障" 0 "无故障" ;
VAL_ 2418278432 RPDU2_B4_SSPC_TripSta_18 1 "短路跳闸" 2 "过流跳闸" 0 "正常" 3 "无定义" ;
VAL_ 2418278432 RPDU2_B4_SSPC_BitErr_18 1 "故障" 0 "正常" ;
VAL_ 2418278432 RPDU2_B4_SSPC_OnOffSta_18 1 "接通" 0 "断开" ;
VAL_ 2418278432 RPDU2_B4_SSPC_DianHuErr_18 1 "有故障" 0 "无故障" ;
VAL_ 2418278432 RPDU2_B4_SSPC_TripSta_17 1 "短路跳闸" 2 "过流跳闸" 0 "正常" 3 "无定义" ;
VAL_ 2418278432 RPDU2_B4_SSPC_BitErr_17 1 "故障" 0 "正常" ;
VAL_ 2418278432 RPDU2_B4_SSPC_OnOffSta_17 1 "接通" 0 "断开" ;
VAL_ 2418278432 RPDU2_B4_SSPC_DianHuErr_17 1 "有故障" 0 "无故障" ;
VAL_ 2418212896 RPDU2_B4_SSPC_TripSta_16 1 "短路跳闸" 2 "过流跳闸" 0 "正常" 3 "无定义" ;
VAL_ 2418212896 RPDU2_B4_SSPC_BitErr_16 1 "故障" 0 "正常" ;
VAL_ 2418212896 RPDU2_B4_SSPC_OnOffSta_16 1 "接通" 0 "断开" ;
VAL_ 2418212896 RPDU2_B4_SSPC_DianHuErr_16 1 "有故障" 0 "无故障" ;
VAL_ 2418212896 RPDU2_B4_SSPC_TripSta_15 1 "短路跳闸" 2 "过流跳闸" 0 "正常" 3 "无定义" ;
VAL_ 2418212896 RPDU2_B4_SSPC_BitErr_15 1 "故障" 0 "正常" ;
VAL_ 2418212896 RPDU2_B4_SSPC_OnOffSta_15 1 "接通" 0 "断开" ;
VAL_ 2418212896 RPDU2_B4_SSPC_DianHuErr_15 1 "有故障" 0 "无故障" ;
VAL_ 2418212896 RPDU2_B4_SSPC_TripSta_14 1 "短路跳闸" 2 "过流跳闸" 0 "正常" 3 "无定义" ;
VAL_ 2418212896 RPDU2_B4_SSPC_BitErr_14 1 "故障" 0 "正常" ;
VAL_ 2418212896 RPDU2_B4_SSPC_OnOffSta_14 1 "接通" 0 "断开" ;
VAL_ 2418212896 RPDU2_B4_SSPC_DianHuErr_14 1 "有故障" 0 "无故障" ;
VAL_ 2418212896 RPDU2_B4_SSPC_TripSta_13 1 "短路跳闸" 2 "过流跳闸" 0 "正常" 3 "无定义" ;
VAL_ 2418212896 RPDU2_B4_SSPC_BitErr_13 1 "故障" 0 "正常" ;
VAL_ 2418212896 RPDU2_B4_SSPC_OnOffSta_13 1 "接通" 0 "断开" ;
VAL_ 2418212896 RPDU2_B4_SSPC_DianHuErr_13 1 "有故障" 0 "无故障" ;
VAL_ 2418147360 RPDU2_B4_SSPC_TripSta_12 1 "短路跳闸" 2 "过流跳闸" 0 "正常" 3 "无定义" ;
VAL_ 2418147360 RPDU2_B4_SSPC_BitErr_12 1 "故障" 0 "正常" ;
VAL_ 2418147360 RPDU2_B4_SSPC_OnOffSta_12 1 "接通" 0 "断开" ;
VAL_ 2418147360 RPDU2_B4_SSPC_DianHuErr_12 1 "有故障" 0 "无故障" ;
VAL_ 2418147360 RPDU2_B4_SSPC_TripSta_11 1 "短路跳闸" 2 "过流跳闸" 0 "正常" 3 "无定义" ;
VAL_ 2418147360 RPDU2_B4_SSPC_BitErr_11 1 "故障" 0 "正常" ;
VAL_ 2418147360 RPDU2_B4_SSPC_OnOffSta_11 1 "接通" 0 "断开" ;
VAL_ 2418147360 RPDU2_B4_SSPC_DianHuErr_11 1 "有故障" 0 "无故障" ;
VAL_ 2418147360 RPDU2_B4_SSPC_TripSta_10 1 "短路跳闸" 2 "过流跳闸" 0 "正常" 3 "无定义" ;
VAL_ 2418147360 RPDU2_B4_SSPC_BitErr_10 1 "故障" 0 "正常" ;
VAL_ 2418147360 RPDU2_B4_SSPC_OnOffSta_10 1 "接通" 0 "断开" ;
VAL_ 2418147360 RPDU2_B4_SSPC_DianHuErr_10 1 "有故障" 0 "无故障" ;
VAL_ 2418147360 RPDU2_B4_SSPC_TripSta_09 1 "短路跳闸" 2 "过流跳闸" 0 "正常" 3 "无定义" ;
VAL_ 2418147360 RPDU2_B4_SSPC_BitErr_09 1 "故障" 0 "正常" ;
VAL_ 2418147360 RPDU2_B4_SSPC_OnOffSta_09 1 "接通" 0 "断开" ;
VAL_ 2418147360 RPDU2_B4_SSPC_DianHuErr_09 1 "有故障" 0 "无故障" ;
VAL_ 2418081824 RPDU2_B4_SSPC_TripSta_08 1 "短路跳闸" 2 "过流跳闸" 0 "正常" 3 "无定义" ;
VAL_ 2418081824 RPDU2_B4_SSPC_BitErr_08 1 "故障" 0 "正常" ;
VAL_ 2418081824 RPDU2_B4_SSPC_OnOffSta_08 1 "接通" 0 "断开" ;
VAL_ 2418081824 RPDU2_B4_SSPC_DianHuErr_08 1 "有故障" 0 "无故障" ;
VAL_ 2418081824 RPDU2_B4_SSPC_TripSta_07 1 "短路跳闸" 2 "过流跳闸" 0 "正常" 3 "无定义" ;
VAL_ 2418081824 RPDU2_B4_SSPC_BitErr_07 1 "故障" 0 "正常" ;
VAL_ 2418081824 RPDU2_B4_SSPC_OnOffSta_07 1 "接通" 0 "断开" ;
VAL_ 2418081824 RPDU2_B4_SSPC_DianHuErr_07 1 "有故障" 0 "无故障" ;
VAL_ 2418081824 RPDU2_B4_SSPC_TripSta_06 1 "短路跳闸" 2 "过流跳闸" 0 "正常" 3 "无定义" ;
VAL_ 2418081824 RPDU2_B4_SSPC_BitErr_06 1 "故障" 0 "正常" ;
VAL_ 2418081824 RPDU2_B4_SSPC_OnOffSta_06 1 "接通" 0 "断开" ;
VAL_ 2418081824 RPDU2_B4_SSPC_DianHuErr_06 1 "有故障" 0 "无故障" ;
VAL_ 2418081824 RPDU2_B4_SSPC_TripSta_05 1 "短路跳闸" 2 "过流跳闸" 0 "正常" 3 "无定义" ;
VAL_ 2418081824 RPDU2_B4_SSPC_BitErr_05 1 "故障" 0 "正常" ;
VAL_ 2418081824 RPDU2_B4_SSPC_OnOffSta_05 1 "接通" 0 "断开" ;
VAL_ 2418081824 RPDU2_B4_SSPC_DianHuErr_05 1 "有故障" 0 "无故障" ;
VAL_ 2418016288 RPDU2_B4_SSPC_TripSta_04 1 "短路跳闸" 2 "过流跳闸" 0 "正常" 3 "无定义" ;
VAL_ 2418016288 RPDU2_B4_SSPC_BitErr_04 1 "故障" 0 "正常" ;
VAL_ 2418016288 RPDU2_B4_SSPC_OnOffSta_04 1 "接通" 0 "断开" ;
VAL_ 2418016288 RPDU2_B4_SSPC_DianHuErr_04 1 "有故障" 0 "无故障" ;
VAL_ 2418016288 RPDU2_B4_SSPC_TripSta_03 1 "短路跳闸" 2 "过流跳闸" 0 "正常" 3 "无定义" ;
VAL_ 2418016288 RPDU2_B4_SSPC_BitErr_03 1 "故障" 0 "正常" ;
VAL_ 2418016288 RPDU2_B4_SSPC_OnOffSta_03 1 "接通" 0 "断开" ;
VAL_ 2418016288 RPDU2_B4_SSPC_DianHuErr_03 1 "有故障" 0 "无故障" ;
VAL_ 2418016288 RPDU2_B4_SSPC_TripSta_02 1 "短路跳闸" 2 "过流跳闸" 0 "正常" 3 "无定义" ;
VAL_ 2418016288 RPDU2_B4_SSPC_BitErr_02 1 "故障" 0 "正常" ;
VAL_ 2418016288 RPDU2_B4_SSPC_OnOffSta_02 1 "接通" 0 "断开" ;
VAL_ 2418016288 RPDU2_B4_SSPC_DianHuErr_02 1 "有故障" 0 "无故障" ;
VAL_ 2418016288 RPDU2_B4_SSPC_TripSta_01 1 "短路跳闸" 2 "过流跳闸" 0 "正常" 3 "无定义" ;
VAL_ 2418016288 RPDU2_B4_SSPC_BitErr_01 1 "故障" 0 "正常" ;
VAL_ 2418016288 RPDU2_B4_SSPC_OnOffSta_01 1 "接通" 0 "断开" ;
VAL_ 2418016288 RPDU2_B4_SSPC_DianHuErr_01 1 "有故障" 0 "无故障" ;
VAL_ 2417950752 RPDU2_B3_SSPC_TripSta_18 1 "短路跳闸" 2 "过流跳闸" 0 "正常" 3 "无定义" ;
VAL_ 2417950752 RPDU2_B3_SSPC_BitErr_18 1 "故障" 0 "正常" ;
VAL_ 2417950752 RPDU2_B3_SSPC_OnOffSta_18 1 "接通" 0 "断开" ;
VAL_ 2417950752 RPDU2_B3_SSPC_DianHuErr_18 1 "有故障" 0 "无故障" ;
VAL_ 2417950752 RPDU2_B3_SSPC_TripSta_17 1 "短路跳闸" 2 "过流跳闸" 0 "正常" 3 "无定义" ;
VAL_ 2417950752 RPDU2_B3_SSPC_BitErr_17 1 "故障" 0 "正常" ;
VAL_ 2417950752 RPDU2_B3_SSPC_OnOffSta_17 1 "接通" 0 "断开" ;
VAL_ 2417950752 RPDU2_B3_SSPC_DianHuErr_17 1 "有故障" 0 "无故障" ;
VAL_ 2417885216 RPDU2_B3_SSPC_TripSta_16 1 "短路跳闸" 2 "过流跳闸" 0 "正常" 3 "无定义" ;
VAL_ 2417885216 RPDU2_B3_SSPC_BitErr_16 1 "故障" 0 "正常" ;
VAL_ 2417885216 RPDU2_B3_SSPC_OnOffSta_16 1 "接通" 0 "断开" ;
VAL_ 2417885216 RPDU2_B3_SSPC_DianHuErr_16 1 "有故障" 0 "无故障" ;
VAL_ 2417885216 RPDU2_B3_SSPC_TripSta_15 1 "短路跳闸" 2 "过流跳闸" 0 "正常" 3 "无定义" ;
VAL_ 2417885216 RPDU2_B3_SSPC_BitErr_15 1 "故障" 0 "正常" ;
VAL_ 2417885216 RPDU2_B3_SSPC_OnOffSta_15 1 "接通" 0 "断开" ;
VAL_ 2417885216 RPDU2_B3_SSPC_DianHuErr_15 1 "有故障" 0 "无故障" ;
VAL_ 2417885216 RPDU2_B3_SSPC_TripSta_14 1 "短路跳闸" 2 "过流跳闸" 0 "正常" 3 "无定义" ;
VAL_ 2417885216 RPDU2_B3_SSPC_BitErr_14 1 "故障" 0 "正常" ;
VAL_ 2417885216 RPDU2_B3_SSPC_OnOffSta_14 1 "接通" 0 "断开" ;
VAL_ 2417885216 RPDU2_B3_SSPC_DianHuErr_14 1 "有故障" 0 "无故障" ;
VAL_ 2417885216 RPDU2_B3_SSPC_TripSta_13 1 "短路跳闸" 2 "过流跳闸" 0 "正常" 3 "无定义" ;
VAL_ 2417885216 RPDU2_B3_SSPC_BitErr_13 1 "故障" 0 "正常" ;
VAL_ 2417885216 RPDU2_B3_SSPC_OnOffSta_13 1 "接通" 0 "断开" ;
VAL_ 2417885216 RPDU2_B3_SSPC_DianHuErr_13 1 "有故障" 0 "无故障" ;
VAL_ 2417819680 RPDU2_B3_SSPC_TripSta_12 1 "短路跳闸" 2 "过流跳闸" 0 "正常" 3 "无定义" ;
VAL_ 2417819680 RPDU2_B3_SSPC_BitErr_12 1 "故障" 0 "正常" ;
VAL_ 2417819680 RPDU2_B3_SSPC_OnOffSta_12 1 "接通" 0 "断开" ;
VAL_ 2417819680 RPDU2_B3_SSPC_DianHuErr_12 1 "有故障" 0 "无故障" ;
VAL_ 2417819680 RPDU2_B3_SSPC_TripSta_11 1 "短路跳闸" 2 "过流跳闸" 0 "正常" 3 "无定义" ;
VAL_ 2417819680 RPDU2_B3_SSPC_BitErr_11 1 "故障" 0 "正常" ;
VAL_ 2417819680 RPDU2_B3_SSPC_OnOffSta_11 1 "接通" 0 "断开" ;
VAL_ 2417819680 RPDU2_B3_SSPC_DianHuErr_11 1 "有故障" 0 "无故障" ;
VAL_ 2417819680 RPDU2_B3_SSPC_TripSta_10 1 "短路跳闸" 2 "过流跳闸" 0 "正常" 3 "无定义" ;
VAL_ 2417819680 RPDU2_B3_SSPC_BitErr_10 1 "故障" 0 "正常" ;
VAL_ 2417819680 RPDU2_B3_SSPC_OnOffSta_10 1 "接通" 0 "断开" ;
VAL_ 2417819680 RPDU2_B3_SSPC_DianHuErr_10 1 "有故障" 0 "无故障" ;
VAL_ 2417819680 RPDU2_B3_SSPC_TripSta_09 1 "短路跳闸" 2 "过流跳闸" 0 "正常" 3 "无定义" ;
VAL_ 2417819680 RPDU2_B3_SSPC_BitErr_09 1 "故障" 0 "正常" ;
VAL_ 2417819680 RPDU2_B3_SSPC_OnOffSta_09 1 "接通" 0 "断开" ;
VAL_ 2417819680 RPDU2_B3_SSPC_DianHuErr_09 1 "有故障" 0 "无故障" ;
VAL_ 2417754144 RPDU2_B3_SSPC_TripSta_08 1 "短路跳闸" 2 "过流跳闸" 0 "正常" 3 "无定义" ;
VAL_ 2417754144 RPDU2_B3_SSPC_BitErr_08 1 "故障" 0 "正常" ;
VAL_ 2417754144 RPDU2_B3_SSPC_OnOffSta_08 1 "接通" 0 "断开" ;
VAL_ 2417754144 RPDU2_B3_SSPC_DianHuErr_08 1 "有故障" 0 "无故障" ;
VAL_ 2417754144 RPDU2_B3_SSPC_TripSta_07 1 "短路跳闸" 2 "过流跳闸" 0 "正常" 3 "无定义" ;
VAL_ 2417754144 RPDU2_B3_SSPC_BitErr_07 1 "故障" 0 "正常" ;
VAL_ 2417754144 RPDU2_B3_SSPC_OnOffSta_07 1 "接通" 0 "断开" ;
VAL_ 2417754144 RPDU2_B3_SSPC_DianHuErr_07 1 "有故障" 0 "无故障" ;
VAL_ 2417754144 RPDU2_B3_SSPC_TripSta_06 1 "短路跳闸" 2 "过流跳闸" 0 "正常" 3 "无定义" ;
VAL_ 2417754144 RPDU2_B3_SSPC_BitErr_06 1 "故障" 0 "正常" ;
VAL_ 2417754144 RPDU2_B3_SSPC_OnOffSta_06 1 "接通" 0 "断开" ;
VAL_ 2417754144 RPDU2_B3_SSPC_DianHuErr_06 1 "有故障" 0 "无故障" ;
VAL_ 2417754144 RPDU2_B3_SSPC_TripSta_05 1 "短路跳闸" 2 "过流跳闸" 0 "正常" 3 "无定义" ;
VAL_ 2417754144 RPDU2_B3_SSPC_BitErr_05 1 "故障" 0 "正常" ;
VAL_ 2417754144 RPDU2_B3_SSPC_OnOffSta_05 1 "接通" 0 "断开" ;
VAL_ 2417754144 RPDU2_B3_SSPC_DianHuErr_05 1 "有故障" 0 "无故障" ;
VAL_ 2417688608 RPDU2_B3_SSPC_TripSta_04 1 "短路跳闸" 2 "过流跳闸" 0 "正常" 3 "无定义" ;
VAL_ 2417688608 RPDU2_B3_SSPC_BitErr_04 1 "故障" 0 "正常" ;
VAL_ 2417688608 RPDU2_B3_SSPC_OnOffSta_04 1 "接通" 0 "断开" ;
VAL_ 2417688608 RPDU2_B3_SSPC_DianHuErr_04 1 "有故障" 0 "无故障" ;
VAL_ 2417688608 RPDU2_B3_SSPC_TripSta_03 1 "短路跳闸" 2 "过流跳闸" 0 "正常" 3 "无定义" ;
VAL_ 2417688608 RPDU2_B3_SSPC_BitErr_03 1 "故障" 0 "正常" ;
VAL_ 2417688608 RPDU2_B3_SSPC_OnOffSta_03 1 "接通" 0 "断开" ;
VAL_ 2417688608 RPDU2_B3_SSPC_DianHuErr_03 1 "有故障" 0 "无故障" ;
VAL_ 2417688608 RPDU2_B3_SSPC_TripSta_02 1 "短路跳闸" 2 "过流跳闸" 0 "正常" 3 "无定义" ;
VAL_ 2417688608 RPDU2_B3_SSPC_BitErr_02 1 "故障" 0 "正常" ;
VAL_ 2417688608 RPDU2_B3_SSPC_OnOffSta_02 1 "接通" 0 "断开" ;
VAL_ 2417688608 RPDU2_B3_SSPC_DianHuErr_02 1 "有故障" 0 "无故障" ;
VAL_ 2417688608 RPDU2_B3_SSPC_TripSta_01 1 "短路跳闸" 2 "过流跳闸" 0 "正常" 3 "无定义" ;
VAL_ 2417688608 RPDU2_B3_SSPC_BitErr_01 1 "故障" 0 "正常" ;
VAL_ 2417688608 RPDU2_B3_SSPC_OnOffSta_01 1 "接通" 0 "断开" ;
VAL_ 2417688608 RPDU2_B3_SSPC_DianHuErr_01 1 "有故障" 0 "无故障" ;
VAL_ 2417623072 RPDU2_B2_SSPC_TripSta_18 1 "短路跳闸" 2 "过流跳闸" 0 "正常" 3 "无定义" ;
VAL_ 2417623072 RPDU2_B2_SSPC_BitErr_18 1 "故障" 0 "正常" ;
VAL_ 2417623072 RPDU2_B2_SSPC_OnOffSta_18 1 "接通" 0 "断开" ;
VAL_ 2417623072 RPDU2_B2_SSPC_DianHuErr_18 1 "有故障" 0 "无故障" ;
VAL_ 2417623072 RPDU2_B2_SSPC_TripSta_17 1 "短路跳闸" 2 "过流跳闸" 0 "正常" 3 "无定义" ;
VAL_ 2417623072 RPDU2_B2_SSPC_BitErr_17 1 "故障" 0 "正常" ;
VAL_ 2417623072 RPDU2_B2_SSPC_OnOffSta_17 1 "接通" 0 "断开" ;
VAL_ 2417623072 RPDU2_B2_SSPC_DianHuErr_17 1 "有故障" 0 "无故障" ;
VAL_ 2417557536 RPDU2_B2_SSPC_TripSta_16 1 "短路跳闸" 2 "过流跳闸" 0 "正常" 3 "无定义" ;
VAL_ 2417557536 RPDU2_B2_SSPC_BitErr_16 1 "故障" 0 "正常" ;
VAL_ 2417557536 RPDU2_B2_SSPC_OnOffSta_16 1 "接通" 0 "断开" ;
VAL_ 2417557536 RPDU2_B2_SSPC_DianHuErr_16 1 "有故障" 0 "无故障" ;
VAL_ 2417557536 RPDU2_B2_SSPC_TripSta_15 1 "短路跳闸" 2 "过流跳闸" 0 "正常" 3 "无定义" ;
VAL_ 2417557536 RPDU2_B2_SSPC_BitErr_15 1 "故障" 0 "正常" ;
VAL_ 2417557536 RPDU2_B2_SSPC_OnOffSta_15 1 "接通" 0 "断开" ;
VAL_ 2417557536 RPDU2_B2_SSPC_DianHuErr_15 1 "有故障" 0 "无故障" ;
VAL_ 2417557536 RPDU2_B2_SSPC_TripSta_14 1 "短路跳闸" 2 "过流跳闸" 0 "正常" 3 "无定义" ;
VAL_ 2417557536 RPDU2_B2_SSPC_BitErr_14 1 "故障" 0 "正常" ;
VAL_ 2417557536 RPDU2_B2_SSPC_OnOffSta_14 1 "接通" 0 "断开" ;
VAL_ 2417557536 RPDU2_B2_SSPC_DianHuErr_14 1 "有故障" 0 "无故障" ;
VAL_ 2417557536 RPDU2_B2_SSPC_TripSta_13 1 "短路跳闸" 2 "过流跳闸" 0 "正常" 3 "无定义" ;
VAL_ 2417557536 RPDU2_B2_SSPC_BitErr_13 1 "故障" 0 "正常" ;
VAL_ 2417557536 RPDU2_B2_SSPC_OnOffSta_13 1 "接通" 0 "断开" ;
VAL_ 2417557536 RPDU2_B2_SSPC_DianHuErr_13 1 "有故障" 0 "无故障" ;
VAL_ 2417492000 RPDU2_B2_SSPC_TripSta_12 1 "短路跳闸" 2 "过流跳闸" 0 "正常" 3 "无定义" ;
VAL_ 2417492000 RPDU2_B2_SSPC_BitErr_12 1 "故障" 0 "正常" ;
VAL_ 2417492000 RPDU2_B2_SSPC_OnOffSta_12 1 "接通" 0 "断开" ;
VAL_ 2417492000 RPDU2_B2_SSPC_DianHuErr_12 1 "有故障" 0 "无故障" ;
VAL_ 2417492000 RPDU2_B2_SSPC_TripSta_11 1 "短路跳闸" 2 "过流跳闸" 0 "正常" 3 "无定义" ;
VAL_ 2417492000 RPDU2_B2_SSPC_BitErr_11 1 "故障" 0 "正常" ;
VAL_ 2417492000 RPDU2_B2_SSPC_OnOffSta_11 1 "接通" 0 "断开" ;
VAL_ 2417492000 RPDU2_B2_SSPC_DianHuErr_11 1 "有故障" 0 "无故障" ;
VAL_ 2417492000 RPDU2_B2_SSPC_TripSta_10 1 "短路跳闸" 2 "过流跳闸" 0 "正常" 3 "无定义" ;
VAL_ 2417492000 RPDU2_B2_SSPC_BitErr_10 1 "故障" 0 "正常" ;
VAL_ 2417492000 RPDU2_B2_SSPC_OnOffSta_10 1 "接通" 0 "断开" ;
VAL_ 2417492000 RPDU2_B2_SSPC_DianHuErr_10 1 "有故障" 0 "无故障" ;
VAL_ 2417492000 RPDU2_B2_SSPC_TripSta_09 1 "短路跳闸" 2 "过流跳闸" 0 "正常" 3 "无定义" ;
VAL_ 2417492000 RPDU2_B2_SSPC_BitErr_09 1 "故障" 0 "正常" ;
VAL_ 2417492000 RPDU2_B2_SSPC_OnOffSta_09 1 "接通" 0 "断开" ;
VAL_ 2417492000 RPDU2_B2_SSPC_DianHuErr_09 1 "有故障" 0 "无故障" ;
VAL_ 2417426464 RPDU2_B2_SSPC_TripSta_08 1 "短路跳闸" 2 "过流跳闸" 0 "正常" 3 "无定义" ;
VAL_ 2417426464 RPDU2_B2_SSPC_BitErr_08 1 "故障" 0 "正常" ;
VAL_ 2417426464 RPDU2_B2_SSPC_OnOffSta_08 1 "接通" 0 "断开" ;
VAL_ 2417426464 RPDU2_B2_SSPC_DianHuErr_08 1 "有故障" 0 "无故障" ;
VAL_ 2417426464 RPDU2_B2_SSPC_TripSta_07 1 "短路跳闸" 2 "过流跳闸" 0 "正常" 3 "无定义" ;
VAL_ 2417426464 RPDU2_B2_SSPC_BitErr_07 1 "故障" 0 "正常" ;
VAL_ 2417426464 RPDU2_B2_SSPC_OnOffSta_07 1 "接通" 0 "断开" ;
VAL_ 2417426464 RPDU2_B2_SSPC_DianHuErr_07 1 "有故障" 0 "无故障" ;
VAL_ 2417426464 RPDU2_B2_SSPC_TripSta_06 1 "短路跳闸" 2 "过流跳闸" 0 "正常" 3 "无定义" ;
VAL_ 2417426464 RPDU2_B2_SSPC_BitErr_06 1 "故障" 0 "正常" ;
VAL_ 2417426464 RPDU2_B2_SSPC_OnOffSta_06 1 "接通" 0 "断开" ;
VAL_ 2417426464 RPDU2_B2_SSPC_DianHuErr_06 1 "有故障" 0 "无故障" ;
VAL_ 2417426464 RPDU2_B2_SSPC_TripSta_05 1 "短路跳闸" 2 "过流跳闸" 0 "正常" 3 "无定义" ;
VAL_ 2417426464 RPDU2_B2_SSPC_BitErr_05 1 "故障" 0 "正常" ;
VAL_ 2417426464 RPDU2_B2_SSPC_OnOffSta_05 1 "接通" 0 "断开" ;
VAL_ 2417426464 RPDU2_B2_SSPC_DianHuErr_05 1 "有故障" 0 "无故障" ;
VAL_ 2417360928 RPDU2_B2_SSPC_TripSta_04 1 "短路跳闸" 2 "过流跳闸" 0 "正常" 3 "无定义" ;
VAL_ 2417360928 RPDU2_B2_SSPC_BitErr_04 1 "故障" 0 "正常" ;
VAL_ 2417360928 RPDU2_B2_SSPC_OnOffSta_04 1 "接通" 0 "断开" ;
VAL_ 2417360928 RPDU2_B2_SSPC_DianHuErr_04 1 "有故障" 0 "无故障" ;
VAL_ 2417360928 RPDU2_B2_SSPC_TripSta_03 1 "短路跳闸" 2 "过流跳闸" 0 "正常" 3 "无定义" ;
VAL_ 2417360928 RPDU2_B2_SSPC_BitErr_03 1 "故障" 0 "正常" ;
VAL_ 2417360928 RPDU2_B2_SSPC_OnOffSta_03 1 "接通" 0 "断开" ;
VAL_ 2417360928 RPDU2_B2_SSPC_DianHuErr_03 1 "有故障" 0 "无故障" ;
VAL_ 2417360928 RPDU2_B2_SSPC_TripSta_02 1 "短路跳闸" 2 "过流跳闸" 0 "正常" 3 "无定义" ;
VAL_ 2417360928 RPDU2_B2_SSPC_BitErr_02 1 "故障" 0 "正常" ;
VAL_ 2417360928 RPDU2_B2_SSPC_OnOffSta_02 1 "接通" 0 "断开" ;
VAL_ 2417360928 RPDU2_B2_SSPC_DianHuErr_02 1 "有故障" 0 "无故障" ;
VAL_ 2417360928 RPDU2_B2_SSPC_TripSta_01 1 "短路跳闸" 2 "过流跳闸" 0 "正常" 3 "无定义" ;
VAL_ 2417360928 RPDU2_B2_SSPC_BitErr_01 1 "故障" 0 "正常" ;
VAL_ 2417360928 RPDU2_B2_SSPC_OnOffSta_01 1 "接通" 0 "断开" ;
VAL_ 2417360928 RPDU2_B2_SSPC_DianHuErr_01 1 "有故障" 0 "无故障" ;
VAL_ 2417295392 RPDU2_B1_SSPC_TripSta_18 1 "短路跳闸" 2 "过流跳闸" 0 "正常" 3 "无定义" ;
VAL_ 2417295392 RPDU2_B1_SSPC_BitErr_18 1 "故障" 0 "正常" ;
VAL_ 2417295392 RPDU2_B1_SSPC_OnOffSta_18 1 "接通" 0 "断开" ;
VAL_ 2417295392 RPDU2_B1_SSPC_DianHuErr_18 1 "有故障" 0 "无故障" ;
VAL_ 2417295392 RPDU2_B1_SSPC_TripSta_17 1 "短路跳闸" 2 "过流跳闸" 0 "正常" 3 "无定义" ;
VAL_ 2417295392 RPDU2_B1_SSPC_BitErr_17 1 "故障" 0 "正常" ;
VAL_ 2417295392 RPDU2_B1_SSPC_OnOffSta_17 1 "接通" 0 "断开" ;
VAL_ 2417295392 RPDU2_B1_SSPC_DianHuErr_17 1 "有故障" 0 "无故障" ;
VAL_ 2417229856 RPDU2_B1_SSPC_TripSta_16 1 "短路跳闸" 2 "过流跳闸" 0 "正常" 3 "无定义" ;
VAL_ 2417229856 RPDU2_B1_SSPC_BitErr_16 1 "故障" 0 "正常" ;
VAL_ 2417229856 RPDU2_B1_SSPC_OnOffSta_16 1 "接通" 0 "断开" ;
VAL_ 2417229856 RPDU2_B1_SSPC_DianHuErr_16 1 "有故障" 0 "无故障" ;
VAL_ 2417229856 RPDU2_B1_SSPC_TripSta_15 1 "短路跳闸" 2 "过流跳闸" 0 "正常" 3 "无定义" ;
VAL_ 2417229856 RPDU2_B1_SSPC_BitErr_15 1 "故障" 0 "正常" ;
VAL_ 2417229856 RPDU2_B1_SSPC_OnOffSta_15 1 "接通" 0 "断开" ;
VAL_ 2417229856 RPDU2_B1_SSPC_DianHuErr_15 1 "有故障" 0 "无故障" ;
VAL_ 2417229856 RPDU2_B1_SSPC_TripSta_14 1 "短路跳闸" 2 "过流跳闸" 0 "正常" 3 "无定义" ;
VAL_ 2417229856 RPDU2_B1_SSPC_BitErr_14 1 "故障" 0 "正常" ;
VAL_ 2417229856 RPDU2_B1_SSPC_OnOffSta_14 1 "接通" 0 "断开" ;
VAL_ 2417229856 RPDU2_B1_SSPC_DianHuErr_14 1 "有故障" 0 "无故障" ;
VAL_ 2417229856 RPDU2_B1_SSPC_TripSta_13 1 "短路跳闸" 2 "过流跳闸" 0 "正常" 3 "无定义" ;
VAL_ 2417229856 RPDU2_B1_SSPC_BitErr_13 1 "故障" 0 "正常" ;
VAL_ 2417229856 RPDU2_B1_SSPC_OnOffSta_13 1 "接通" 0 "断开" ;
VAL_ 2417229856 RPDU2_B1_SSPC_DianHuErr_13 1 "有故障" 0 "无故障" ;
VAL_ 2417164320 RPDU2_B1_SSPC_TripSta_12 1 "短路跳闸" 2 "过流跳闸" 0 "正常" 3 "无定义" ;
VAL_ 2417164320 RPDU2_B1_SSPC_BitErr_12 1 "故障" 0 "正常" ;
VAL_ 2417164320 RPDU2_B1_SSPC_OnOffSta_12 1 "接通" 0 "断开" ;
VAL_ 2417164320 RPDU2_B1_SSPC_DianHuErr_12 1 "有故障" 0 "无故障" ;
VAL_ 2417164320 RPDU2_B1_SSPC_TripSta_11 1 "短路跳闸" 2 "过流跳闸" 0 "正常" 3 "无定义" ;
VAL_ 2417164320 RPDU2_B1_SSPC_BitErr_11 1 "故障" 0 "正常" ;
VAL_ 2417164320 RPDU2_B1_SSPC_OnOffSta_11 1 "接通" 0 "断开" ;
VAL_ 2417164320 RPDU2_B1_SSPC_DianHuErr_11 1 "有故障" 0 "无故障" ;
VAL_ 2417164320 RPDU2_B1_SSPC_TripSta_10 1 "短路跳闸" 2 "过流跳闸" 0 "正常" 3 "无定义" ;
VAL_ 2417164320 RPDU2_B1_SSPC_BitErr_10 1 "故障" 0 "正常" ;
VAL_ 2417164320 RPDU2_B1_SSPC_OnOffSta_10 1 "接通" 0 "断开" ;
VAL_ 2417164320 RPDU2_B1_SSPC_DianHuErr_10 1 "有故障" 0 "无故障" ;
VAL_ 2417164320 RPDU2_B1_SSPC_TripSta_09 1 "短路跳闸" 2 "过流跳闸" 0 "正常" 3 "无定义" ;
VAL_ 2417164320 RPDU2_B1_SSPC_BitErr_09 1 "故障" 0 "正常" ;
VAL_ 2417164320 RPDU2_B1_SSPC_OnOffSta_09 1 "接通" 0 "断开" ;
VAL_ 2417164320 RPDU2_B1_SSPC_DianHuErr_09 1 "有故障" 0 "无故障" ;
VAL_ 2417098784 RPDU2_B1_SSPC_TripSta_08 1 "短路跳闸" 2 "过流跳闸" 0 "正常" 3 "无定义" ;
VAL_ 2417098784 RPDU2_B1_SSPC_BitErr_08 1 "故障" 0 "正常" ;
VAL_ 2417098784 RPDU2_B1_SSPC_OnOffSta_08 1 "接通" 0 "断开" ;
VAL_ 2417098784 RPDU2_B1_SSPC_DianHuErr_08 1 "有故障" 0 "无故障" ;
VAL_ 2417098784 RPDU2_B1_SSPC_TripSta_07 1 "短路跳闸" 2 "过流跳闸" 0 "正常" 3 "无定义" ;
VAL_ 2417098784 RPDU2_B1_SSPC_BitErr_07 1 "故障" 0 "正常" ;
VAL_ 2417098784 RPDU2_B1_SSPC_OnOffSta_07 1 "接通" 0 "断开" ;
VAL_ 2417098784 RPDU2_B1_SSPC_DianHuErr_07 1 "有故障" 0 "无故障" ;
VAL_ 2417098784 RPDU2_B1_SSPC_TripSta_06 1 "短路跳闸" 2 "过流跳闸" 0 "正常" 3 "无定义" ;
VAL_ 2417098784 RPDU2_B1_SSPC_BitErr_06 1 "故障" 0 "正常" ;
VAL_ 2417098784 RPDU2_B1_SSPC_OnOffSta_06 1 "接通" 0 "断开" ;
VAL_ 2417098784 RPDU2_B1_SSPC_DianHuErr_06 1 "有故障" 0 "无故障" ;
VAL_ 2417098784 RPDU2_B1_SSPC_TripSta_05 1 "短路跳闸" 2 "过流跳闸" 0 "正常" 3 "无定义" ;
VAL_ 2417098784 RPDU2_B1_SSPC_BitErr_05 1 "故障" 0 "正常" ;
VAL_ 2417098784 RPDU2_B1_SSPC_OnOffSta_05 1 "接通" 0 "断开" ;
VAL_ 2417098784 RPDU2_B1_SSPC_DianHuErr_05 1 "有故障" 0 "无故障" ;
VAL_ 2417033248 RPDU2_B1_SSPC_TripSta_04 1 "短路跳闸" 2 "过流跳闸" 0 "正常" 3 "无定义" ;
VAL_ 2417033248 RPDU2_B1_SSPC_BitErr_04 1 "故障" 0 "正常" ;
VAL_ 2417033248 RPDU2_B1_SSPC_OnOffSta_04 1 "接通" 0 "断开" ;
VAL_ 2417033248 RPDU2_B1_SSPC_DianHuErr_04 1 "有故障" 0 "无故障" ;
VAL_ 2417033248 RPDU2_B1_SSPC_TripSta_03 1 "短路跳闸" 2 "过流跳闸" 0 "正常" 3 "无定义" ;
VAL_ 2417033248 RPDU2_B1_SSPC_BitErr_03 1 "故障" 0 "正常" ;
VAL_ 2417033248 RPDU2_B1_SSPC_OnOffSta_03 1 "接通" 0 "断开" ;
VAL_ 2417033248 RPDU2_B1_SSPC_DianHuErr_03 1 "有故障" 0 "无故障" ;
VAL_ 2417033248 RPDU2_B1_SSPC_TripSta_02 1 "短路跳闸" 2 "过流跳闸" 0 "正常" 3 "无定义" ;
VAL_ 2417033248 RPDU2_B1_SSPC_BitErr_02 1 "故障" 0 "正常" ;
VAL_ 2417033248 RPDU2_B1_SSPC_OnOffSta_02 1 "接通" 0 "断开" ;
VAL_ 2417033248 RPDU2_B1_SSPC_DianHuErr_02 1 "有故障" 0 "无故障" ;
VAL_ 2417033248 RPDU2_B1_SSPC_TripSta_01 1 "短路跳闸" 2 "过流跳闸" 0 "正常" 3 "无定义" ;
VAL_ 2417033248 RPDU2_B1_SSPC_BitErr_01 1 "故障" 0 "正常" ;
VAL_ 2417033248 RPDU2_B1_SSPC_OnOffSta_01 1 "接通" 0 "断开" ;
VAL_ 2417033248 RPDU2_B1_SSPC_DianHuErr_01 1 "有故障" 0 "无故障" ;
VAL_ 2416967712 R_TouChuan_DCDC_DDCSta 0 "断开" 1 "接通" ;
VAL_ 2416967712 R_TouChuan_DCDC_DDCCtrl 0 "断开" 1 "接通" ;
VAL_ 2416967712 R_TouChuan_DCDC_FanWarn 0 "正常" 1 "故障" ;
VAL_ 2416967712 R_TouChuan_DCDC_ConnStaErr 0 "正常" 1 "故障" ;
VAL_ 2416967712 R_TouChuan_DCDC_HardOutOverErr 0 "正常" 1 "故障" ;
VAL_ 2416967712 R_TouChuan_DCDC_TOverErr 0 "正常" 1 "故障" ;
VAL_ 2416967712 R_TouChuan_DCDC_TOverWarn 0 "正常" 1 "故障" ;
VAL_ 2416967712 R_TouChuan_DCDC_OutILimitErr 0 "正常" 1 "故障" ;
VAL_ 2416967712 R_TouChuan_DCDC_OutIOverErr 0 "正常" 1 "故障" ;
VAL_ 2416967712 R_TouChuan_DCDC_OutPowOverErr 0 "正常" 1 "故障" ;
VAL_ 2416967712 R_TouChuan_DCDC_OutPowLowErr 0 "正常" 1 "故障" ;
VAL_ 2416967712 R_TouChuan_DCDC_OutPowLowWarn 0 "正常" 1 "故障" ;
VAL_ 2416967712 R_TouChuan_DCDC_InPowLowErr 0 "正常" 1 "故障" ;
VAL_ 2416508960 R_DuanLuQi_Sta_49 0 "接通" 1 "断开" ;
VAL_ 2416508960 R_DuanLuQi_Sta_48 0 "接通" 1 "断开" ;
VAL_ 2416508960 R_DuanLuQi_Sta_47 0 "接通" 1 "断开" ;
VAL_ 2416508960 R_DuanLuQi_Sta_46 0 "接通" 1 "断开" ;
VAL_ 2416508960 R_DuanLuQi_Sta_45 0 "接通" 1 "断开" ;
VAL_ 2416508960 R_DuanLuQi_Sta_44 0 "接通" 1 "断开" ;
VAL_ 2416508960 R_DuanLuQi_Sta_43 0 "接通" 1 "断开" ;
VAL_ 2416508960 R_DuanLuQi_Sta_42 0 "接通" 1 "断开" ;
VAL_ 2416508960 R_DuanLuQi_Sta_41 0 "接通" 1 "断开" ;
VAL_ 2416508960 R_DuanLuQi_Sta_40 0 "接通" 1 "断开" ;
VAL_ 2416508960 R_DuanLuQi_Sta_39 0 "接通" 1 "断开" ;
VAL_ 2416508960 R_DuanLuQi_Sta_38 0 "接通" 1 "断开" ;
VAL_ 2416508960 R_DuanLuQi_Sta_37 0 "接通" 1 "断开" ;
VAL_ 2416508960 R_DuanLuQi_Sta_36 0 "接通" 1 "断开" ;
VAL_ 2416508960 R_DuanLuQi_Sta_35 0 "接通" 1 "断开" ;
VAL_ 2416508960 R_DuanLuQi_Sta_34 0 "接通" 1 "断开" ;
VAL_ 2416508960 R_DuanLuQi_Sta_33 0 "接通" 1 "断开" ;
VAL_ 2416508960 R_DuanLuQi_Sta_32 0 "接通" 1 "断开" ;
VAL_ 2416508960 R_DuanLuQi_Sta_31 0 "接通" 1 "断开" ;
VAL_ 2416508960 R_DuanLuQi_Sta_30 0 "接通" 1 "断开" ;
VAL_ 2416508960 R_DuanLuQi_Sta_29 0 "接通" 1 "断开" ;
VAL_ 2416508960 R_DuanLuQi_Sta_28 0 "接通" 1 "断开" ;
VAL_ 2416508960 R_DuanLuQi_Sta_27 0 "接通" 1 "断开" ;
VAL_ 2416508960 R_DuanLuQi_Sta_26 0 "接通" 1 "断开" ;
VAL_ 2416508960 R_DuanLuQi_Sta_25 0 "接通" 1 "断开" ;
VAL_ 2416508960 R_DuanLuQi_Sta_24 0 "接通" 1 "断开" ;
VAL_ 2416508960 R_DuanLuQi_Sta_23 0 "接通" 1 "断开" ;
VAL_ 2416508960 R_DuanLuQi_Sta_22 0 "接通" 1 "断开" ;
VAL_ 2416508960 R_DuanLuQi_Sta_21 0 "接通" 1 "断开" ;
VAL_ 2416508960 R_DuanLuQi_Sta_20 0 "接通" 1 "断开" ;
VAL_ 2416508960 R_DuanLuQi_Sta_19 0 "接通" 1 "断开" ;
VAL_ 2416508960 R_DuanLuQi_Sta_18 0 "接通" 1 "断开" ;
VAL_ 2416508960 R_DuanLuQi_Sta_17 0 "接通" 1 "断开" ;
VAL_ 2416508960 R_DuanLuQi_Sta_16 0 "接通" 1 "断开" ;
VAL_ 2416508960 R_DuanLuQi_Sta_15 0 "接通" 1 "断开" ;
VAL_ 2416508960 R_DuanLuQi_Sta_14 0 "接通" 1 "断开" ;
VAL_ 2416508960 R_DuanLuQi_Sta_13 0 "接通" 1 "断开" ;
VAL_ 2416508960 R_DuanLuQi_Sta_12 0 "接通" 1 "断开" ;
VAL_ 2416508960 R_DuanLuQi_Sta_11 0 "接通" 1 "断开" ;
VAL_ 2416508960 R_DuanLuQi_Sta_10 0 "接通" 1 "断开" ;
VAL_ 2416508960 R_DuanLuQi_Sta_09 0 "接通" 1 "断开" ;
VAL_ 2416508960 R_DuanLuQi_Sta_08 0 "接通" 1 "断开" ;
VAL_ 2416508960 R_DuanLuQi_Sta_07 0 "接通" 1 "断开" ;
VAL_ 2416508960 R_DuanLuQi_Sta_06 0 "接通" 1 "断开" ;
VAL_ 2416508960 R_DuanLuQi_Sta_05 0 "接通" 1 "断开" ;
VAL_ 2416508960 R_DuanLuQi_Sta_04 0 "接通" 1 "断开" ;
VAL_ 2416508960 R_DuanLuQi_Sta_03 0 "接通" 1 "断开" ;
VAL_ 2416508960 R_DuanLuQi_Sta_02 0 "接通" 1 "断开" ;
VAL_ 2416508960 R_DuanLuQi_Sta_01 0 "接通" 1 "断开" ;
VAL_ 2416443424 R_RE28IOver 0 "不过流" 1 "过流" ;
VAL_ 2416443424 R_RL28IOver 0 "不过流" 1 "过流" ;
VAL_ 2416443424 R_HLT281IOver 0 "不过流" 1 "过流" ;
VAL_ 2416443424 R_HLT282IOver 0 "不过流" 1 "过流" ;
VAL_ 2416443424 R_RE270IOver 0 "不过流" 1 "过流" ;
VAL_ 2416443424 R_HLT270IOver 0 "不过流" 1 "过流" ;
VAL_ 2416443424 R_HOTBBUSta 0 "正常" 1 "欠压" 2 "过压" 3 "无定义" ;
VAL_ 2416443424 R_HLT281USta 0 "正常" 1 "欠压" 2 "过压" 3 "无定义" ;
VAL_ 2416443424 R_HLT282USta 0 "正常" 1 "欠压" 2 "过压" 3 "无定义" ;
VAL_ 2416443424 R_DCDC28OutUSta 0 "正常" 1 "欠压" 2 "过压" 3 "无定义" ;
VAL_ 2416443424 R_DCDC270InUSta 0 "正常" 1 "欠压" 2 "过压" 3 "无定义" ;
VAL_ 2416443424 R_HLT270USta 0 "正常" 1 "欠压" 2 "过压" 3 "无定义" ;
VAL_ 2416443424 R_Batter270USta 0 "正常" 1 "欠压" 2 "过压" 3 "无定义" ;
VAL_ 2416443424 R_Heart_BIT 0 "正常" 1 "故障" ;
VAL_ 2416443424 R_ZBUART_BIT 0 "正常" 1 "故障" ;
VAL_ 2416443424 R_ADCIN_BIT 0 "正常" 1 "故障" ;
VAL_ 2416443424 R_GpioIN_BIT 0 "正常" 1 "故障" ;
VAL_ 2416443424 R_Flash_BIT 0 "正常" 1 "故障" ;
VAL_ 2416443424 R_UART_BIT 0 "正常" 1 "故障" ;
VAL_ 2416443424 R_IntCAN2_BIT 0 "正常" 1 "故障" ;
VAL_ 2416443424 R_IntCAN1_BIT 0 "正常" 1 "故障" ;
VAL_ 2416443424 R_ExtCAN_BIT 0 "正常" 1 "故障" ;
VAL_ 2416443424 R_CPU_BIT 0 "正常" 1 "故障" ;
VAL_ 2416443424 R_Pow_BIT 0 "正常" 1 "故障" ;
VAL_ 2416377888 RTSSR_STA 0 "接通" 1 "断开" 2 "无效" 3 "无效" ;
VAL_ 2416377888 EBC_STA_R 0 "接通正常" 1 "接通故障" 3 "断开正常" 2 "断开故障" ;
VAL_ 2416377888 RETC1_STA 0 "接通正常" 1 "接通故障" 3 "断开正常" 2 "断开故障" ;
VAL_ 2416377888 BTC1_STA 0 "接通正常" 1 "接通故障" 3 "断开正常" 2 "断开故障" ;
VAL_ 2416377888 RDC2_STA 0 "接通正常" 1 "接通故障" 3 "断开正常" 2 "断开故障" ;
VAL_ 2416377888 RETR_STA 0 "接通正常" 1 "接通故障" 3 "断开正常" 2 "断开故障" ;
VAL_ 2416377888 RBC_STA 0 "接通正常" 1 "接通故障" 3 "断开正常" 2 "断开故障" ;
VAL_ 2421178384 LETC1_Ctrl 0 "接通" 1 "断开" ;
VAL_ 2421178384 LETR_Ctrl 0 "接通" 1 "断开" ;
VAL_ 2421178384 LETR_STA_ChongGou 0 "接通正常" 1 "接通故障" 3 "断开正常" 2 "断开故障" ;
VAL_ 2421178384 LETC1_ChongGou_ChangJing 0 "无控制或断开" 1 "左欠压,E正常" 2 "左正常,E欠压" 3 "左欠压,E欠压" ;
VAL_ 2421178384 LETC1_STA_ChongGou 0 "接通正常" 1 "接通故障" 3 "断开正常" 2 "断开故障" ;
VAL_ 2421178384 BTC2_STA_ChongGou 0 "接通正常" 1 "接通故障" 3 "断开正常" 2 "断开故障" ;
VAL_ 2421178384 BTC2_ReSta 0 "接通" 1 "断开" ;
VAL_ 2421178384 LTR_Ctrl 0 "接通" 1 "断开" ;
VAL_ 2421178384 LDC2_Ctrl 0 "接通" 1 "断开" ;
VAL_ 2421178384 LDC1_Ctrl 0 "接通" 1 "断开" ;
VAL_ 2421178384 BTC2_ChongGou_ChangJing 0 "无控制" 1 "左欠压,右正常" 2 "左正常,右欠压" 3 "无定义" ;
VAL_ 2421178384 LETC1_ReSta 0 "接通" 1 "断开" ;
VAL_ 2421178384 L_HLT282IOver_ChongGou 0 "不过流" 1 "过流" ;
VAL_ 2421178384 L_HLT281IOver_ChongGou 0 "不过流" 1 "过流" ;
VAL_ 2421178384 L_HLT270IOver_ChongGou 0 "不过流" 1 "过流" ;
VAL_ 2420178960 RPDU3_B6_SSPC_TripSta_07 1 "短路跳闸" 2 "过流跳闸" 0 "正常" 3 "无定义" ;
VAL_ 2420178960 RPDU3_B6_SSPC_BitErr_07 1 "故障" 0 "正常" ;
VAL_ 2420178960 RPDU3_B6_SSPC_OnOffSta_07 1 "接通" 0 "断开" ;
VAL_ 2420178960 RPDU3_B6_SSPC_DianHuErr_07 1 "有故障" 0 "无故障" ;
VAL_ 2420178960 RPDU3_B6_SSPC_TripSta_06 1 "短路跳闸" 2 "过流跳闸" 0 "正常" 3 "无定义" ;
VAL_ 2420178960 RPDU3_B6_SSPC_BitErr_06 1 "故障" 0 "正常" ;
VAL_ 2420178960 RPDU3_B6_SSPC_OnOffSta_06 1 "接通" 0 "断开" ;
VAL_ 2420178960 RPDU3_B6_SSPC_DianHuErr_06 1 "有故障" 0 "无故障" ;
VAL_ 2420178960 RPDU3_B6_SSPC_TripSta_05 1 "短路跳闸" 2 "过流跳闸" 0 "正常" 3 "无定义" ;
VAL_ 2420178960 RPDU3_B6_SSPC_BitErr_05 1 "故障" 0 "正常" ;
VAL_ 2420178960 RPDU3_B6_SSPC_OnOffSta_05 1 "接通" 0 "断开" ;
VAL_ 2420178960 RPDU3_B6_SSPC_DianHuErr_05 1 "有故障" 0 "无故障" ;
VAL_ 2420113424 RPDU3_B6_SSPC_TripSta_04 1 "短路跳闸" 2 "过流跳闸" 0 "正常" 3 "无定义" ;
VAL_ 2420113424 RPDU3_B6_SSPC_BitErr_04 1 "故障" 0 "正常" ;
VAL_ 2420113424 RPDU3_B6_SSPC_OnOffSta_04 1 "接通" 0 "断开" ;
VAL_ 2420113424 RPDU3_B6_SSPC_DianHuErr_04 1 "有故障" 0 "无故障" ;
VAL_ 2420113424 RPDU3_B6_SSPC_TripSta_03 1 "短路跳闸" 2 "过流跳闸" 0 "正常" 3 "无定义" ;
VAL_ 2420113424 RPDU3_B6_SSPC_BitErr_03 1 "故障" 0 "正常" ;
VAL_ 2420113424 RPDU3_B6_SSPC_OnOffSta_03 1 "接通" 0 "断开" ;
VAL_ 2420113424 RPDU3_B6_SSPC_DianHuErr_03 1 "有故障" 0 "无故障" ;
VAL_ 2420113424 RPDU3_B6_SSPC_TripSta_02 1 "短路跳闸" 2 "过流跳闸" 0 "正常" 3 "无定义" ;
VAL_ 2420113424 RPDU3_B6_SSPC_BitErr_02 1 "故障" 0 "正常" ;
VAL_ 2420113424 RPDU3_B6_SSPC_OnOffSta_02 1 "接通" 0 "断开" ;
VAL_ 2420113424 RPDU3_B6_SSPC_DianHuErr_02 1 "有故障" 0 "无故障" ;
VAL_ 2420113424 RPDU3_B6_SSPC_TripSta_01 1 "短路跳闸" 2 "过流跳闸" 0 "正常" 3 "无定义" ;
VAL_ 2420113424 RPDU3_B6_SSPC_BitErr_01 1 "故障" 0 "正常" ;
VAL_ 2420113424 RPDU3_B6_SSPC_OnOffSta_01 1 "接通" 0 "断开" ;
VAL_ 2420113424 RPDU3_B6_SSPC_DianHuErr_01 1 "有故障" 0 "无故障" ;
VAL_ 2420047888 RPDU3_B5_SSPC_TripSta_07 1 "短路跳闸" 2 "过流跳闸" 0 "正常" 3 "无定义" ;
VAL_ 2420047888 RPDU3_B5_SSPC_BitErr_07 1 "故障" 0 "正常" ;
VAL_ 2420047888 RPDU3_B5_SSPC_OnOffSta_07 1 "接通" 0 "断开" ;
VAL_ 2420047888 RPDU3_B5_SSPC_DianHuErr_07 1 "有故障" 0 "无故障" ;
VAL_ 2420047888 RPDU3_B5_SSPC_TripSta_06 1 "短路跳闸" 2 "过流跳闸" 0 "正常" 3 "无定义" ;
VAL_ 2420047888 RPDU3_B5_SSPC_BitErr_06 1 "故障" 0 "正常" ;
VAL_ 2420047888 RPDU3_B5_SSPC_OnOffSta_06 1 "接通" 0 "断开" ;
VAL_ 2420047888 RPDU3_B5_SSPC_DianHuErr_06 1 "有故障" 0 "无故障" ;
VAL_ 2420047888 RPDU3_B5_SSPC_TripSta_05 1 "短路跳闸" 2 "过流跳闸" 0 "正常" 3 "无定义" ;
VAL_ 2420047888 RPDU3_B5_SSPC_BitErr_05 1 "故障" 0 "正常" ;
VAL_ 2420047888 RPDU3_B5_SSPC_OnOffSta_05 1 "接通" 0 "断开" ;
VAL_ 2420047888 RPDU3_B5_SSPC_DianHuErr_05 1 "有故障" 0 "无故障" ;
VAL_ 2419982352 RPDU3_B5_SSPC_TripSta_04 1 "短路跳闸" 2 "过流跳闸" 0 "正常" 3 "无定义" ;
VAL_ 2419982352 RPDU3_B5_SSPC_BitErr_04 1 "故障" 0 "正常" ;
VAL_ 2419982352 RPDU3_B5_SSPC_OnOffSta_04 1 "接通" 0 "断开" ;
VAL_ 2419982352 RPDU3_B5_SSPC_DianHuErr_04 1 "有故障" 0 "无故障" ;
VAL_ 2419982352 RPDU3_B5_SSPC_TripSta_03 1 "短路跳闸" 2 "过流跳闸" 0 "正常" 3 "无定义" ;
VAL_ 2419982352 RPDU3_B5_SSPC_BitErr_03 1 "故障" 0 "正常" ;
VAL_ 2419982352 RPDU3_B5_SSPC_OnOffSta_03 1 "接通" 0 "断开" ;
VAL_ 2419982352 RPDU3_B5_SSPC_DianHuErr_03 1 "有故障" 0 "无故障" ;
VAL_ 2419982352 RPDU3_B5_SSPC_TripSta_02 1 "短路跳闸" 2 "过流跳闸" 0 "正常" 3 "无定义" ;
VAL_ 2419982352 RPDU3_B5_SSPC_BitErr_02 1 "故障" 0 "正常" ;
VAL_ 2419982352 RPDU3_B5_SSPC_OnOffSta_02 1 "接通" 0 "断开" ;
VAL_ 2419982352 RPDU3_B5_SSPC_DianHuErr_02 1 "有故障" 0 "无故障" ;
VAL_ 2419982352 RPDU3_B5_SSPC_TripSta_01 1 "短路跳闸" 2 "过流跳闸" 0 "正常" 3 "无定义" ;
VAL_ 2419982352 RPDU3_B5_SSPC_BitErr_01 1 "故障" 0 "正常" ;
VAL_ 2419982352 RPDU3_B5_SSPC_OnOffSta_01 1 "接通" 0 "断开" ;
VAL_ 2419982352 RPDU3_B5_SSPC_DianHuErr_01 1 "有故障" 0 "无故障" ;
VAL_ 2419916816 RPDU3_B4_SSPC_TripSta_18 1 "短路跳闸" 2 "过流跳闸" 0 "正常" 3 "无定义" ;
VAL_ 2419916816 RPDU3_B4_SSPC_BitErr_18 1 "故障" 0 "正常" ;
VAL_ 2419916816 RPDU3_B4_SSPC_OnOffSta_18 1 "接通" 0 "断开" ;
VAL_ 2419916816 RPDU3_B4_SSPC_DianHuErr_18 1 "有故障" 0 "无故障" ;
VAL_ 2419916816 RPDU3_B4_SSPC_TripSta_17 1 "短路跳闸" 2 "过流跳闸" 0 "正常" 3 "无定义" ;
VAL_ 2419916816 RPDU3_B4_SSPC_BitErr_17 1 "故障" 0 "正常" ;
VAL_ 2419916816 RPDU3_B4_SSPC_OnOffSta_17 1 "接通" 0 "断开" ;
VAL_ 2419916816 RPDU3_B4_SSPC_DianHuErr_17 1 "有故障" 0 "无故障" ;
VAL_ 2419851280 RPDU3_B4_SSPC_TripSta_16 1 "短路跳闸" 2 "过流跳闸" 0 "正常" 3 "无定义" ;
VAL_ 2419851280 RPDU3_B4_SSPC_BitErr_16 1 "故障" 0 "正常" ;
VAL_ 2419851280 RPDU3_B4_SSPC_OnOffSta_16 1 "接通" 0 "断开" ;
VAL_ 2419851280 RPDU3_B4_SSPC_DianHuErr_16 1 "有故障" 0 "无故障" ;
VAL_ 2419851280 RPDU3_B4_SSPC_TripSta_15 1 "短路跳闸" 2 "过流跳闸" 0 "正常" 3 "无定义" ;
VAL_ 2419851280 RPDU3_B4_SSPC_BitErr_15 1 "故障" 0 "正常" ;
VAL_ 2419851280 RPDU3_B4_SSPC_OnOffSta_15 1 "接通" 0 "断开" ;
VAL_ 2419851280 RPDU3_B4_SSPC_DianHuErr_15 1 "有故障" 0 "无故障" ;
VAL_ 2419851280 RPDU3_B4_SSPC_TripSta_14 1 "短路跳闸" 2 "过流跳闸" 0 "正常" 3 "无定义" ;
VAL_ 2419851280 RPDU3_B4_SSPC_BitErr_14 1 "故障" 0 "正常" ;
VAL_ 2419851280 RPDU3_B4_SSPC_OnOffSta_14 1 "接通" 0 "断开" ;
VAL_ 2419851280 RPDU3_B4_SSPC_DianHuErr_14 1 "有故障" 0 "无故障" ;
VAL_ 2419851280 RPDU3_B4_SSPC_TripSta_13 1 "短路跳闸" 2 "过流跳闸" 0 "正常" 3 "无定义" ;
VAL_ 2419851280 RPDU3_B4_SSPC_BitErr_13 1 "故障" 0 "正常" ;
VAL_ 2419851280 RPDU3_B4_SSPC_OnOffSta_13 1 "接通" 0 "断开" ;
VAL_ 2419851280 RPDU3_B4_SSPC_DianHuErr_13 1 "有故障" 0 "无故障" ;
VAL_ 2419785744 RPDU3_B4_SSPC_TripSta_12 1 "短路跳闸" 2 "过流跳闸" 0 "正常" 3 "无定义" ;
VAL_ 2419785744 RPDU3_B4_SSPC_BitErr_12 1 "故障" 0 "正常" ;
VAL_ 2419785744 RPDU3_B4_SSPC_OnOffSta_12 1 "接通" 0 "断开" ;
VAL_ 2419785744 RPDU3_B4_SSPC_DianHuErr_12 1 "有故障" 0 "无故障" ;
VAL_ 2419785744 RPDU3_B4_SSPC_TripSta_11 1 "短路跳闸" 2 "过流跳闸" 0 "正常" 3 "无定义" ;
VAL_ 2419785744 RPDU3_B4_SSPC_BitErr_11 1 "故障" 0 "正常" ;
VAL_ 2419785744 RPDU3_B4_SSPC_OnOffSta_11 1 "接通" 0 "断开" ;
VAL_ 2419785744 RPDU3_B4_SSPC_DianHuErr_11 1 "有故障" 0 "无故障" ;
VAL_ 2419785744 RPDU3_B4_SSPC_TripSta_10 1 "短路跳闸" 2 "过流跳闸" 0 "正常" 3 "无定义" ;
VAL_ 2419785744 RPDU3_B4_SSPC_BitErr_10 1 "故障" 0 "正常" ;
VAL_ 2419785744 RPDU3_B4_SSPC_OnOffSta_10 1 "接通" 0 "断开" ;
VAL_ 2419785744 RPDU3_B4_SSPC_DianHuErr_10 1 "有故障" 0 "无故障" ;
VAL_ 2419785744 RPDU3_B4_SSPC_TripSta_09 1 "短路跳闸" 2 "过流跳闸" 0 "正常" 3 "无定义" ;
VAL_ 2419785744 RPDU3_B4_SSPC_BitErr_09 1 "故障" 0 "正常" ;
VAL_ 2419785744 RPDU3_B4_SSPC_OnOffSta_09 1 "接通" 0 "断开" ;
VAL_ 2419785744 RPDU3_B4_SSPC_DianHuErr_09 1 "有故障" 0 "无故障" ;
VAL_ 2419720208 RPDU3_B4_SSPC_TripSta_08 1 "短路跳闸" 2 "过流跳闸" 0 "正常" 3 "无定义" ;
VAL_ 2419720208 RPDU3_B4_SSPC_BitErr_08 1 "故障" 0 "正常" ;
VAL_ 2419720208 RPDU3_B4_SSPC_OnOffSta_08 1 "接通" 0 "断开" ;
VAL_ 2419720208 RPDU3_B4_SSPC_DianHuErr_08 1 "有故障" 0 "无故障" ;
VAL_ 2419720208 RPDU3_B4_SSPC_TripSta_07 1 "短路跳闸" 2 "过流跳闸" 0 "正常" 3 "无定义" ;
VAL_ 2419720208 RPDU3_B4_SSPC_BitErr_07 1 "故障" 0 "正常" ;
VAL_ 2419720208 RPDU3_B4_SSPC_OnOffSta_07 1 "接通" 0 "断开" ;
VAL_ 2419720208 RPDU3_B4_SSPC_DianHuErr_07 1 "有故障" 0 "无故障" ;
VAL_ 2419720208 RPDU3_B4_SSPC_TripSta_06 1 "短路跳闸" 2 "过流跳闸" 0 "正常" 3 "无定义" ;
VAL_ 2419720208 RPDU3_B4_SSPC_BitErr_06 1 "故障" 0 "正常" ;
VAL_ 2419720208 RPDU3_B4_SSPC_OnOffSta_06 1 "接通" 0 "断开" ;
VAL_ 2419720208 RPDU3_B4_SSPC_DianHuErr_06 1 "有故障" 0 "无故障" ;
VAL_ 2419720208 RPDU3_B4_SSPC_TripSta_05 1 "短路跳闸" 2 "过流跳闸" 0 "正常" 3 "无定义" ;
VAL_ 2419720208 RPDU3_B4_SSPC_BitErr_05 1 "故障" 0 "正常" ;
VAL_ 2419720208 RPDU3_B4_SSPC_OnOffSta_05 1 "接通" 0 "断开" ;
VAL_ 2419720208 RPDU3_B4_SSPC_DianHuErr_05 1 "有故障" 0 "无故障" ;
VAL_ 2419654672 RPDU3_B4_SSPC_TripSta_04 1 "短路跳闸" 2 "过流跳闸" 0 "正常" 3 "无定义" ;
VAL_ 2419654672 RPDU3_B4_SSPC_BitErr_04 1 "故障" 0 "正常" ;
VAL_ 2419654672 RPDU3_B4_SSPC_OnOffSta_04 1 "接通" 0 "断开" ;
VAL_ 2419654672 RPDU3_B4_SSPC_DianHuErr_04 1 "有故障" 0 "无故障" ;
VAL_ 2419654672 RPDU3_B4_SSPC_TripSta_03 1 "短路跳闸" 2 "过流跳闸" 0 "正常" 3 "无定义" ;
VAL_ 2419654672 RPDU3_B4_SSPC_BitErr_03 1 "故障" 0 "正常" ;
VAL_ 2419654672 RPDU3_B4_SSPC_OnOffSta_03 1 "接通" 0 "断开" ;
VAL_ 2419654672 RPDU3_B4_SSPC_DianHuErr_03 1 "有故障" 0 "无故障" ;
VAL_ 2419654672 RPDU3_B4_SSPC_TripSta_02 1 "短路跳闸" 2 "过流跳闸" 0 "正常" 3 "无定义" ;
VAL_ 2419654672 RPDU3_B4_SSPC_BitErr_02 1 "故障" 0 "正常" ;
VAL_ 2419654672 RPDU3_B4_SSPC_OnOffSta_02 1 "接通" 0 "断开" ;
VAL_ 2419654672 RPDU3_B4_SSPC_DianHuErr_02 1 "有故障" 0 "无故障" ;
VAL_ 2419654672 RPDU3_B4_SSPC_TripSta_01 1 "短路跳闸" 2 "过流跳闸" 0 "正常" 3 "无定义" ;
VAL_ 2419654672 RPDU3_B4_SSPC_BitErr_01 1 "故障" 0 "正常" ;
VAL_ 2419654672 RPDU3_B4_SSPC_OnOffSta_01 1 "接通" 0 "断开" ;
VAL_ 2419654672 RPDU3_B4_SSPC_DianHuErr_01 1 "有故障" 0 "无故障" ;
